VERSION "FL_IC_CANFD"

NS_ :

BS_:

BU_: AVAS BBCM CMSM DVR EAMP EPC FLZCU ICC PCL PLG SBOX SCU

BO_ 1028 PEPS_2: 16 FLZCU
 SG_ PEPS_WelcomeON : 17|2@0+ (1,0) [0|3] ""  ICC
 SG_ PEPS_VehicleSearchReq : 19|2@0+ (1,0) [0|3] ""  ICC
 SG_ PEPS_SATOReminder : 21|2@0+ (1,0) [0|3] ""  ICC
 SG_ PEPS_PLGUnlockReq : 23|2@0+ (1,0) [0|3] ""  ICC
 SG_ PEPS_RKETrunkSts : 25|2@0+ (1,0) [0|3] ""  ICC
 SG_ PEPS_SSBInhibitCWCSts : 27|2@0+ (1,0) [0|3] ""  ICC
 SG_ PEPS_WirelessChargingCtrSts : 29|2@0+ (1,0) [0|3] ""  ICC
 SG_ PEPS_EmgyShutdown : 35|2@0+ (1,0) [0|3] ""  ICC
 SG_ PEPS_SSBInputFailure : 37|2@0+ (1,0) [0|3] ""  ICC
 SG_ PEPS_SmartSystemWarning1_1 : 39|2@0+ (1,0) [0|3] ""  ICC
 SG_ PEPS_SmartSystemWarning2_2 : 41|2@0+ (1,0) [0|3] ""  ICC
 SG_ PEPS_SmartSystemWarning3_1 : 43|2@0+ (1,0) [0|3] ""  ICC
 SG_ PEPS_SmartSystemWarning3_2 : 45|2@0+ (1,0) [0|3] ""  ICC
 SG_ PEPS_SmartSystemWarning4_2 : 47|2@0+ (1,0) [0|3] ""  ICC
 SG_ PEPS_SmartSystemWarning4_3 : 49|2@0+ (1,0) [0|3] ""  ICC
 SG_ PEPS_SystemWarning : 51|2@0+ (1,0) [0|3] ""  ICC
 SG_ PEPS_BLTKeyPESts : 53|2@0+ (1,0) [0|3] ""  ICC

BO_ 1030 FLZCU_12: 16 FLZCU
 SG_ RearViewFoldSts : 58|2@0+ (1,0) [0|3] ""  ICC
 SG_ FLZCU_AlrmSts : 61|3@0+ (1,0) [0|7] ""  ICC
 SG_ FLZCU_SteeringMode : 82|2@0+ (1,0) [0|3] ""  ICC
 SG_ FLZCU_OBDDiagOccupy : 105|2@0+ (1,0) [0|3] ""  ICC

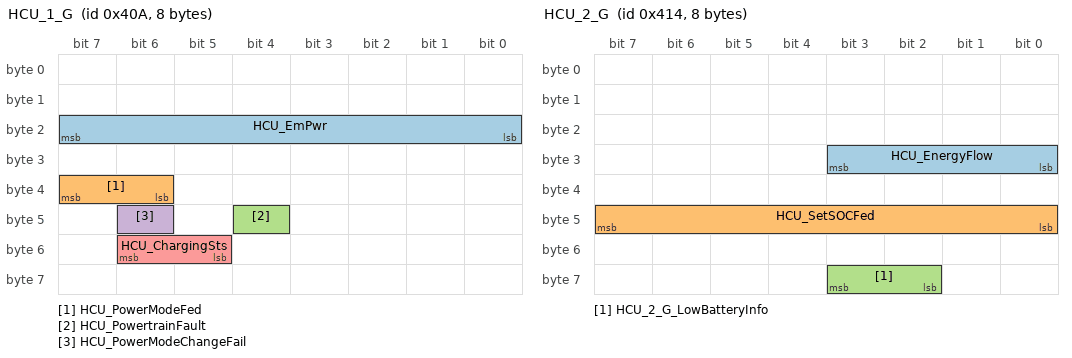
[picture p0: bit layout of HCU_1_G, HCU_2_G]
BO_ 1034 HCU_1_G: 8 FLZCU
 SG_ HCU_EmPwr : 23|8@0+ (1,-128) [-100|100] "%"  ICC
 SG_ HCU_PowerModeFed : 39|2@0+ (1,0) [0|3] ""  ICC
 SG_ HCU_PowertrainFault : 44|1@0+ (1,0) [0|1] ""  ICC
 SG_ HCU_PowerModeChangeFail : 46|1@0+ (1,0) [0|1] ""  ICC
 SG_ HCU_ChargingSts : 54|2@0+ (1,0) [0|3] ""  ICC

BO_ 1035 VCC_1: 8 FLZCU
 SG_ VCC_1_OTASts : 17|2@0+ (1,0) [0|3] ""  ICC
 SG_ VCC_1_DriveMode : 36|5@0+ (1,0) [0|31] ""  ICC

BO_ 1037 ADAS_ZCU_1: 24 FLZCU
 SG_ ADS_FCTAWarn_Right : 26|1@0+ (1,0) [0|1] ""  ICC
 SG_ ADS_FCTAWarn_Left : 27|1@0+ (1,0) [0|1] ""  ICC
 SG_ ADS_RCTAWarn_Rigth : 28|1@0+ (1,0) [0|1] ""  ICC
 SG_ ADS_RCTAWarn_Left : 29|1@0+ (1,0) [0|1] ""  ICC
 SG_ ADAS_enum_AESSts_40Dh : 33|2@0+ (1,0) [0|3] ""  ICC
 SG_ ADAS_enum_AudibleBeepRate_40Dh : 44|3@0+ (1,0) [0|7] ""  ICC
 SG_ ADAS_enum_FCTASettingStsFb_40Dh : 55|3@0+ (1,0) [0|7] ""  ICC
 SG_ ADAS_enum_RadarWorkSts_40Dh : 80|1@0+ (1,0) [0|1] ""  ICC
 SG_ ADAS_enum_PasSwitch_40Dh : 81|1@0+ (1,0) [0|1] ""  ICC
 SG_ ADAS_enum_MEBSts_40Dh : 83|2@0+ (1,0) [0|3] ""  ICC
 SG_ ADAS_enum_MAASts_40Dh : 85|2@0+ (1,0) [0|3] ""  ICC
 SG_ IHU_11_VoiceplayModeSwtSet_40Dh : 113|2@0+ (1,0) [0|3] ""  ICC
 SG_ IHU_11_LightingBlueSwtSet_40Dh : 115|2@0+ (1,0) [0|3] ""  ICC
 SG_ enum_CECULVDSOutputStatus_40Dh : 160|1@0+ (1,0) [0|1] ""  ICC

BO_ 1041 ADS_HW_411h: 48 FLZCU
 SG_ ADS_RadarWarning0Distance_411h : 23|8@0+ (1,0) [0|255] "cm"  ICC
 SG_ ADS_RadarWarning1Distance_411h : 31|8@0+ (1,0) [0|255] "cm"  ICC
 SG_ ADS_RadarWarning2Distance_411h : 39|8@0+ (1,0) [0|255] "cm"  ICC
 SG_ ADS_RadarWarning3Distance_411h : 47|8@0+ (1,0) [0|255] "cm"  ICC
 SG_ ADS_RadarWarning4Distance_411h : 55|8@0+ (1,0) [0|255] "cm"  ICC
 SG_ ADS_RadarWarning5Distance_411h : 63|8@0+ (1,0) [0|255] "cm"  ICC
 SG_ ADS_RadarWarning6Distance_411h : 87|8@0+ (1,0) [0|255] "cm"  ICC
 SG_ ADS_RadarWarning7Distance_411h : 95|8@0+ (1,0) [0|255] "cm"  ICC
 SG_ ADS_RadarWarning8Distance_411h : 103|8@0+ (1,0) [0|255] "cm"  ICC
 SG_ ADS_RadarWarning9Distance_411h : 111|8@0+ (1,0) [0|255] "cm"  ICC
 SG_ ADS_RadarWarning10Distance_411h : 119|8@0+ (1,0) [0|255] "cm"  ICC
 SG_ ADS_RadarWarning11Distance_411h : 127|8@0+ (1,0) [0|255] "cm"  ICC
 SG_ ADS_RadarWarning12Distance_411h : 151|8@0+ (1,0) [0|255] "cm"  ICC
 SG_ ADS_RadarWarning13Distance_411h : 159|8@0+ (1,0) [0|255] "cm"  ICC
 SG_ ADS_RadarWarning14Distance_411h : 167|8@0+ (1,0) [0|255] "cm"  ICC
 SG_ ADS_RadarWarning15Distance_411h : 175|8@0+ (1,0) [0|255] "cm"  ICC
 SG_ ADS_RadarWarning2AcLvl_411h : 177|3@0+ (1,0) [0|7] ""  ICC
 SG_ ADS_RadarWarning1AcLvl_411h : 180|3@0+ (1,0) [0|7] ""  ICC
 SG_ ADS_RadarWarning0AcLvl_411h : 183|3@0+ (1,0) [0|7] ""  ICC
 SG_ ADS_RadarWarning4AcLvl_411h : 187|3@0+ (1,0) [0|7] ""  ICC
 SG_ ADS_RadarWarning3AcLvl_411h : 190|3@0+ (1,0) [0|7] ""  ICC
 SG_ ADS_RadarWarning7AcLvl_411h : 209|3@0+ (1,0) [0|7] ""  ICC
 SG_ ADS_RadarWarning6AcLvl_411h : 212|3@0+ (1,0) [0|7] ""  ICC
 SG_ ADS_RadarWarning5AcLvl_411h : 215|3@0+ (1,0) [0|7] ""  ICC
 SG_ ADS_RadarWarning10AcLvl_411h : 216|3@0+ (1,0) [0|7] ""  ICC
 SG_ ADS_RadarWarning9AcLvl_411h : 219|3@0+ (1,0) [0|7] ""  ICC
 SG_ ADS_RadarWarning8AcLvl_411h : 222|3@0+ (1,0) [0|7] ""  ICC
 SG_ ADS_RadarWarning12AcLvl_411h : 226|3@0+ (1,0) [0|7] ""  ICC
 SG_ ADS_RadarWarning11AcLvl_411h : 229|3@0+ (1,0) [0|7] ""  ICC
 SG_ ADS_RadarWarning15AcLvl_411h : 233|3@0+ (1,0) [0|7] ""  ICC
 SG_ ADS_RadarWarning14AcLvl_411h : 236|3@0+ (1,0) [0|7] ""  ICC
 SG_ ADS_RadarWarning13AcLvl_411h : 239|3@0+ (1,0) [0|7] ""  ICC
 SG_ ADC_MdcSentryAlarmMod_411h : 244|1@0+ (1,0) [0|1] ""  ICC
 SG_ ADC_FuncReq_SentryModDetec_411h : 245|1@0+ (1,0) [0|1] ""  ICC
 SG_ ADC_FuncReq_SentryModWarn_411h : 246|1@0+ (1,0) [0|1] ""  ICC

BO_ 1042 ADS_HW_412h: 16 FLZCU
 SG_ ADS_CRC1_412h : 7|8@0+ (1,0) [0|255] ""  ICC
 SG_ ADS_RollgCntr1_412h : 11|4@0+ (1,0) [0|14] ""  ICC
 SG_ ADS_Resd1_412h : 15|4@0+ (1,0) [0|15] ""  ICC
 SG_ ADS_RiFrntDowWarning_412h : 17|2@0+ (1,0) [0|3] ""  ICC
 SG_ ADS_LeFrntDowWarning_412h : 19|2@0+ (1,0) [0|3] ""  ICC
 SG_ ADS_AutoLightSwCtrl_412h : 21|2@0+ (1,0) [0|3] ""  ICC
 SG_ ADS_BrkBeamReq_412h : 23|2@0+ (1,0) [0|3] ""  ICC
 SG_ ADS_RightMirrWarningCmd_412h : 25|2@0+ (1,0) [0|3] ""  ICC
 SG_ ADS_LeftMirrWarningCmd_412h : 27|2@0+ (1,0) [0|3] ""  ICC
 SG_ ADS_RiReDowWarning_412h : 29|2@0+ (1,0) [0|3] ""  ICC
 SG_ ADS_LeReDowWarning_412h : 31|2@0+ (1,0) [0|3] ""  ICC
 SG_ ADS_WshrReq_412h : 32|1@0+ (1,0) [0|1] ""  ICC
 SG_ ADS_SBeltControl_412h : 35|3@0+ (1,0) [0|7] ""  ICC
 SG_ ADS_DoorLockReq_412h : 37|2@0+ (1,0) [0|3] ""  ICC
 SG_ ADS_ReMirrReq_412h : 39|2@0+ (1,0) [0|3] ""  ICC
 SG_ ADS_LeFmtWinCtrl_412h : 41|2@0+ (1,0) [0|3] ""  ICC
 SG_ ADS_HornReq_412h : 43|2@0+ (1,0) [0|3] ""  ICC
 SG_ ADS_FrtWindshildHeatReq_412h : 45|2@0+ (1,0) [0|3] ""  ICC
 SG_ ADS_SeatShakeControl_412h : 47|2@0+ (1,0) [0|3] ""  ICC
 SG_ ADS_TopWinCtrl_412h : 49|2@0+ (1,0) [0|3] ""  ICC
 SG_ ADS_RiReWinCtrl_412h : 51|2@0+ (1,0) [0|3] ""  ICC
 SG_ ADS_LeReWinCtrl_412h : 53|2@0+ (1,0) [0|3] ""  ICC
 SG_ ADS_RiFmtWinCtrl_412h : 55|2@0+ (1,0) [0|3] ""  ICC
 SG_ ADS_MdcCrtSts_412h : 59|3@0+ (1,0) [0|7] ""  ICC
 SG_ ADAS_FctSts_412h : 60|1@0+ (1,0) [0|1] ""  ICC
 SG_ ADS_ChargingPortCmd_412h : 62|2@0+ (1,0) [0|3] ""  ICC
 SG_ ADS_FrontWiperReq_412h : 63|1@0+ (1,0) [0|1] ""  ICC
 SG_ ADS_PwrOnOffReq_412h : 81|3@0+ (1,0) [0|7] ""  ICC
 SG_ ADS_FlowReq_412h : 85|4@0+ (1,0) [0|15] ""  ICC
 SG_ ADS_ThmPostRun_412h : 86|1@0+ (1,0) [0|1] ""  ICC
 SG_ ADS_HVCtrlReq_412h : 87|1@0+ (1,0) [0|1] ""  ICC
 SG_ ADS_HiBeamReq_412h : 90|1@0+ (1,0) [0|1] ""  ICC
 SG_ ADS_HMAStatus_412h : 92|2@0+ (1,0) [0|3] ""  ICC
 SG_ ADS_hmaOnOffSts_412h : 94|2@0+ (1,0) [0|3] ""  ICC

BO_ 1043 FLZCU_8: 8 FLZCU
 SG_ EBS_U_BATT : 7|14@0+ (0.0009765625,3) [3|18] "V"  ICC

BO_ 1044 HCU_2_G: 8 FLZCU
 SG_ HCU_EnergyFlow : 27|4@0+ (1,0) [0|15] ""  ICC
 SG_ HCU_SetSOCFed : 47|8@0+ (1,0) [0|100] ""  ICC
 SG_ HCU_2_G_LowBatteryInfo : 59|2@0+ (1,0) [0|3] ""  ICC

BO_ 1046 LBMS_SysSt4: 32 FLZCU
 SG_ LBMS_LoWSocFlt : 87|4@0+ (1,0) [0|15] ""  ICC
 SG_ LBMS_EndLifeFlt : 152|1@0+ (1,0) [0|1] ""  ICC
 SG_ LBMS_SysFlt : 157|1@0+ (1,0) [0|1] ""  ICC
 SG_ LBMS_ThermRunawayFlt : 158|1@0+ (1,0) [0|1] ""  ICC
 SG_ LBMS_LowPowerRemind : 167|4@0+ (1,0) [0|15] ""  ICC

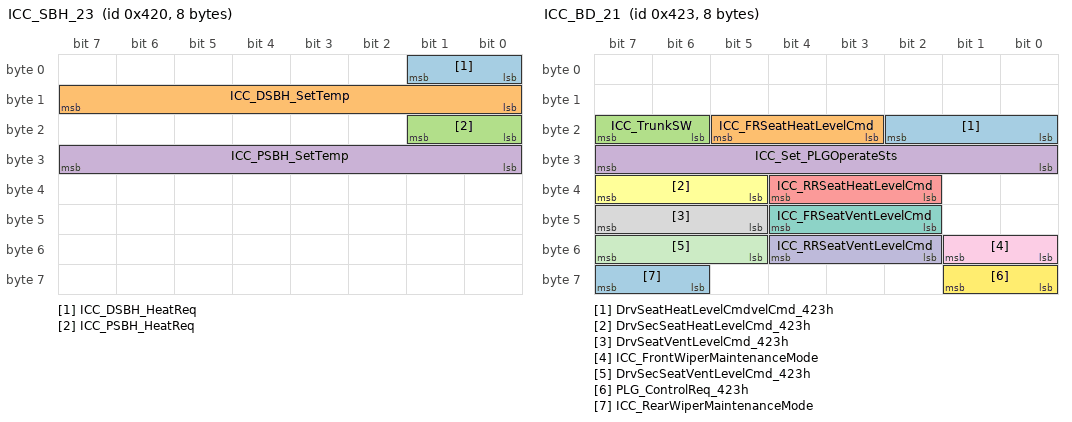
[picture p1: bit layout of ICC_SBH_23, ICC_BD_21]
BO_ 1056 ICC_SBH_23: 8 ICC
 SG_ ICC_DSBH_HeatReq : 1|2@0+ (1,0) [0|3] "" Vector__XXX
 SG_ ICC_DSBH_SetTemp : 15|8@0+ (1,0) [30|65] "°C" Vector__XXX
 SG_ ICC_PSBH_HeatReq : 17|2@0+ (1,0) [0|3] "" Vector__XXX
 SG_ ICC_PSBH_SetTemp : 31|8@0+ (1,0) [30|65] "°C" Vector__XXX

BO_ 1057 VCU_7_G: 32 FLZCU
 SG_ VCU_shfChk : 16|1@0+ (1,0) [0|1] ""  ICC
 SG_ VCU_TowingMode : 33|2@0+ (1,0) [0|3] ""  ICC
 SG_ VCU_ChgSocSetFed : 63|8@0+ (1,0) [50|100] "%"  ICC
 SG_ VCU_EngyConsuPer50Km : 111|12@0+ (0.1,-100) [-100|100] ""  ICC
 SG_ VCU_BookChrgSetFailRes : 154|3@0+ (1,0) [0|7] ""  ICC
 SG_ VCU_BookChrgFailRes : 158|4@0+ (1,0) [0|15] ""  ICC
 SG_ VCU_BookChrgStsFb : 215|2@0+ (1,0) [0|3] ""  ICC
 SG_ HCU_EngineSelfMaintain : 231|2@0+ (1,0) [0|3] ""  ICC

BO_ 1059 ICC_BD_21: 8 ICC
 SG_ DrvSeatHeatLevelCmdvelCmd_423h : 18|3@0+ (1,0) [0|7] ""  FLZCU
 SG_ ICC_FRSeatHeatLevelCmd : 21|3@0+ (1,0) [0|7] ""  FLZCU
 SG_ ICC_TrunkSW : 23|2@0+ (1,0) [0|3] ""  FLZCU
 SG_ ICC_Set_PLGOperateSts : 31|8@0+ (1,-1) [-1|100] "%"  FLZCU,PLG
 SG_ ICC_RRSeatHeatLevelCmd : 36|3@0+ (1,0) [0|7] ""  FLZCU
 SG_ DrvSecSeatHeatLevelCmd_423h : 39|3@0+ (1,0) [0|7] ""  FLZCU
 SG_ ICC_FRSeatVentLevelCmd : 44|3@0+ (1,0) [0|7] ""  FLZCU
 SG_ DrvSeatVentLevelCmd_423h : 47|3@0+ (1,0) [0|7] ""  FLZCU
 SG_ ICC_FrontWiperMaintenanceMode : 49|2@0+ (1,0) [0|3] ""  FLZCU
 SG_ ICC_RRSeatVentLevelCmd : 52|3@0+ (1,0) [0|7] ""  FLZCU
 SG_ DrvSecSeatVentLevelCmd_423h : 55|3@0+ (1,0) [0|7] ""  FLZCU
 SG_ PLG_ControlReq_423h : 57|2@0+ (1,0) [0|3] ""  FLZCU,PLG
 SG_ ICC_RearWiperMaintenanceMode : 63|2@0+ (1,0) [0|3] ""  FLZCU

BO_ 1060 TCU_424h: 64 FLZCU
 SG_ InforDisplay_424h : 38|4@0+ (1,0) [0|15] ""  ICC

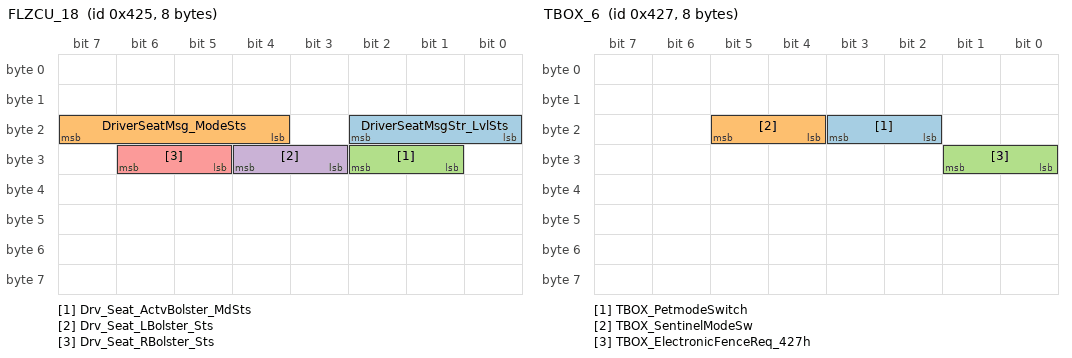
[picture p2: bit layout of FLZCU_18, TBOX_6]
BO_ 1061 FLZCU_18: 8 FLZCU
 SG_ DriverSeatMsgStr_LvlSts : 18|3@0+ (1,0) [0|7] ""  ICC
 SG_ DriverSeatMsg_ModeSts : 23|4@0+ (1,0) [0|15] ""  ICC
 SG_ Drv_Seat_ActvBolster_MdSts : 26|2@0+ (1,0) [0|3] ""  ICC
 SG_ Drv_Seat_LBolster_Sts : 28|2@0+ (1,0) [0|3] ""  ICC
 SG_ Drv_Seat_RBolster_Sts : 30|2@0+ (1,0) [0|3] ""  ICC

BO_ 1063 TBOX_6: 8 FLZCU
 SG_ TBOX_PetmodeSwitch : 19|2@0+ (1,0) [0|3] ""  ICC
 SG_ TBOX_SentinelModeSw : 21|2@0+ (1,0) [0|3] ""  ICC
 SG_ TBOX_ElectronicFenceReq_427h : 25|2@0+ (1,0) [0|3] ""  ICC

BO_ 1065 FLZCU_19: 8 FLZCU
 SG_ LeftSeatMsgStr_LvlSts : 18|3@0+ (1,0) [0|7] ""  ICC
 SG_ LeftSeatMsg_ModeSts : 23|4@0+ (1,0) [0|15] ""  ICC

BO_ 1069 FLZCU_20: 8 FLZCU
 SG_ PassSeatMsgStr_LvlSts : 18|3@0+ (1,0) [0|7] ""  ICC
 SG_ PassSeatMsg_ModeSts : 23|4@0+ (1,0) [0|15] ""  ICC

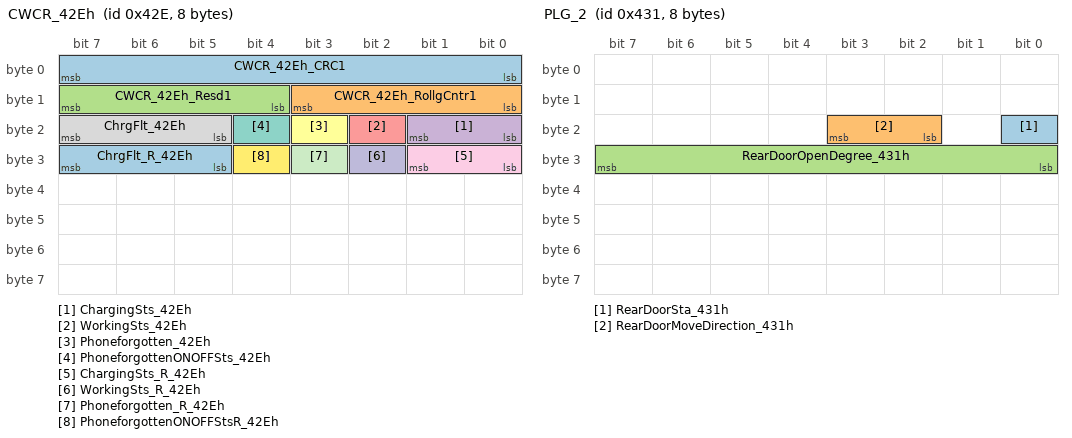
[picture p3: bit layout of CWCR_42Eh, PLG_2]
BO_ 1070 CWCR_42Eh: 8 FLZCU
 SG_ CWCR_42Eh_CRC1 : 7|8@0+ (1,0) [0|255] ""  ICC
 SG_ CWCR_42Eh_RollgCntr1 : 11|4@0+ (1,0) [0|14] ""  ICC
 SG_ CWCR_42Eh_Resd1 : 15|4@0+ (1,0) [0|15] ""  ICC
 SG_ ChargingSts_42Eh : 17|2@0+ (1,0) [0|3] ""  ICC
 SG_ WorkingSts_42Eh : 18|1@0+ (1,0) [0|1] ""  ICC
 SG_ Phoneforgotten_42Eh : 19|1@0+ (1,0) [0|1] ""  ICC
 SG_ PhoneforgottenONOFFSts_42Eh : 20|1@0+ (1,0) [0|1] ""  ICC
 SG_ ChrgFlt_42Eh : 23|3@0+ (1,0) [0|7] ""  ICC
 SG_ ChargingSts_R_42Eh : 25|2@0+ (1,0) [0|3] ""  ICC
 SG_ WorkingSts_R_42Eh : 26|1@0+ (1,0) [0|1] ""  ICC
 SG_ Phoneforgotten_R_42Eh : 27|1@0+ (1,0) [0|1] ""  ICC
 SG_ PhoneforgottenONOFFStsR_42Eh : 28|1@0+ (1,0) [0|1] ""  ICC
 SG_ ChrgFlt_R_42Eh : 31|3@0+ (1,0) [0|7] ""  ICC

BO_ 1071 FLZCU_15: 48 FLZCU
 SG_ FLZCU_CarSearhSetSW : 17|2@0+ (1,0) [0|3] ""  ICC
 SG_ FLZCU_AutoFoldSts : 18|1@0+ (1,0) [0|1] ""  ICC
 SG_ FLZCU_AutolockSts : 19|1@0+ (1,0) [0|1] ""  ICC
 SG_ FLZCU_FGHeat_Req_CmdFeedback : 20|1@0+ (1,0) [0|1] ""  ICC
 SG_ FLZCU_WindowInhibitSts : 21|1@0+ (1,0) [0|1] ""  ICC
 SG_ FLZCU_AutoReadLightSts : 22|1@0+ (1,0) [0|1] ""  ICC
 SG_ FLZCU_HeatingSW : 23|1@0+ (1,0) [0|1] ""  ICC
 SG_ FLZCU_AutoHeatingFb : 24|1@0+ (1,0) [0|1] ""  ICC
 SG_ FLZCU_SteerNeedMemory : 25|1@0+ (1,0) [0|1] ""  ICC
 SG_ FLZCU_LowBeamFaults : 26|1@0+ (1,0) [0|1] ""  ICC
 SG_ FLZCU_RearNeedMemory : 27|1@0+ (1,0) [0|1] ""  ICC
 SG_ FLZCU_BrkLightFaults : 28|1@0+ (1,0) [0|1] ""  ICC
 SG_ FLZCU_TurnLiSwtSts : 31|3@0+ (1,0) [0|7] ""  ICC
 SG_ DrvHandleFoldedSts_42Fh : 33|2@0+ (1,0) [0|3] ""  ICC
 SG_ DrvRearHandleFoldedSts_42Fh : 35|2@0+ (1,0) [0|3] ""  ICC
 SG_ PassHandleFoldedSts_42Fh : 37|2@0+ (1,0) [0|3] ""  ICC
 SG_ PassRearHandleFoldedSts_42Fh : 39|2@0+ (1,0) [0|3] ""  ICC
 SG_ FLZCU_RvsExtMirrFbSts : 41|2@0+ (1,0) [0|3] ""  ICC
 SG_ FLZCU_LightMainSwitchSts : 44|3@0+ (1,0) [0|7] ""  ICC
 SG_ FLZCU_BeamDelaySts : 47|3@0+ (1,0) [0|7] ""  ICC
 SG_ FLZCU_LowBeamHighSts : 50|3@0+ (1,0) [0|7] ""  ICC
 SG_ FLZCU_WipeSensitivitySts : 53|3@0+ (1,0) [0|7] ""  ICC
 SG_ FLZCU_WipeMaintenanceSWSts : 55|2@0+ (1,0) [0|3] ""  ICC
 SG_ FLZCU_HiBeamSwtSts : 57|2@0+ (1,0) [0|3] ""  ICC
 SG_ FLZCU_ImmoRequest : 60|3@0+ (1,0) [0|7] ""  ICC
 SG_ FLZCU_AlarmWarnSetSW : 63|3@0+ (1,0) [0|7] ""  ICC
 SG_ FLZCU_CleanModeStatus : 81|2@0+ (1,0) [0|3] ""  ICC
 SG_ DrvReleaseLockSts_42Fh : 84|3@0+ (1,0) [0|7] ""  ICC
 SG_ FLZCU_RearFogLightSts : 85|1@0+ (1,0) [0|1] ""  ICC
 SG_ PassFoglightSts_42Fh : 86|1@0+ (1,0) [0|1] ""  ICC
 SG_ DrvFoglightSts_42Fh : 87|1@0+ (1,0) [0|1] ""  ICC
 SG_ FLZCU_RearFogLightFaults : 88|1@0+ (1,0) [0|1] ""  ICC
 SG_ FLZCU_HighBeamFaults : 89|1@0+ (1,0) [0|1] ""  ICC
 SG_ FLZCU_HighBeamSts : 90|1@0+ (1,0) [0|1] ""  ICC
 SG_ FLZCU_LowBeamSts : 91|1@0+ (1,0) [0|1] ""  ICC
 SG_ FLZCU_ParkUnlockEnableFb : 92|1@0+ (1,0) [0|1] ""  ICC
 SG_ DrvRearReleaseLockSts_42Fh : 95|3@0+ (1,0) [0|7] ""  ICC
 SG_ FLZCU_EasyEntryExitFb : 97|2@0+ (1,0) [0|3] ""  ICC
 SG_ FLZCU_EmgyLiSwtSts : 98|1@0+ (1,0) [0|1] ""  ICC
 SG_ FLZCU_HMASwSts : 99|1@0+ (1,0) [0|1] ""  ICC
 SG_ FLZCU_DaytimeLight : 101|2@0+ (1,0) [0|3] ""  ICC
 SG_ FLZCU_FGHeatFaults : 102|1@0+ (1,0) [0|1] ""  ICC
 SG_ FLZCU_ParkLightFaults : 103|1@0+ (1,0) [0|1] ""  ICC
 SG_ FLZCU_LbatipVehPwrMod : 106|1@0+ (1,0) [0|1] ""  ICC
 SG_ FLZCU_HMASwSts_MDC : 108|2@0+ (1,0) [0|3] ""  ICC
 SG_ FLZCU_LVPowICDsp : 111|3@0+ (1,0) [0|7] ""  ICC
 SG_ FLZCU_LockCarWinCloseFb : 113|2@0+ (1,0) [0|3] ""  ICC
 SG_ FLZCU_BrkLightSts : 115|2@0+ (1,0) [0|3] ""  ICC
 SG_ FLZCU_ReverseLightSts : 117|2@0+ (1,0) [0|3] ""  ICC
 SG_ FLZCU_LowWashLqdWarning : 119|2@0+ (1,0) [0|3] ""  ICC
 SG_ FLZCU_SteerWheelHeatingFb : 123|3@0+ (1,0) [0|7] ""  ICC
 SG_ FLZCU_FrontFogLightSts : 124|1@0+ (1,0) [0|1] ""  ICC
 SG_ FLZCU_NapAreaFb : 145|2@0+ (1,0) [0|3] ""  ICC
 SG_ FLZCU_NapTimeFb : 151|6@0+ (1,0) [0|60] "min"  ICC
 SG_ FLZCU_NapAlarmStatus : 153|2@0+ (1,0) [0|3] ""  ICC
 SG_ FLZCU_NapFailCause : 157|4@0+ (1,0) [0|15] ""  ICC
 SG_ FLZCU_NapStatusFb : 159|2@0+ (1,0) [0|3] ""  ICC
 SG_ FLZCU_CleanModeFailCause : 163|2@0+ (1,0) [0|3] ""  ICC
 SG_ LockCarSunRoofShadeCloseFb : 165|2@0+ (1,0) [0|3] ""  ICC
 SG_ FLZCU_NapClosePrompt : 167|2@0+ (1,0) [0|3] ""  ICC
 SG_ FLZCU_AutoWipingInhibit : 175|2@0+ (1,0) [0|3] ""  ICC
 SG_ FLZCU_RemoteUnlockFb : 177|2@0+ (1,0) [0|3] ""  ICC
 SG_ FLZCU_FrntWiprSwSts : 181|4@0+ (1,0) [0|15] ""  ICC
 SG_ TurnLightFaults_42Fh : 208|1@0+ (1,0) [0|1] ""  ICC
 SG_ FLZCU_HazardLightSWSts_42Fh : 232|1@0+ (1,0) [0|1] ""  ICC
 SG_ DrvRearWinSts_42Fh : 252|3@0+ (1,0) [0|7] ""  ICC
 SG_ DrvWinSts_42Fh : 255|3@0+ (1,0) [0|7] ""  ICC
 SG_ FLZCU_DaytimeLightFaults : 273|2@0+ (1,0) [0|3] ""  ICC
 SG_ FLZCU_FrontFogLightFaults : 275|2@0+ (1,0) [0|3] ""  ICC
 SG_ FLZCU_HomeLinkWelLightSetSts : 277|2@0+ (1,0) [0|3] ""  ICC
 SG_ FLZCU_HomeLinkArmHornSetSts : 279|2@0+ (1,0) [0|3] ""  ICC
 SG_ FLZCU_UIROpenStas : 283|2@0+ (1,0) [0|3] ""  ICC
 SG_ FLZCU_WALOpenStas : 285|2@0+ (1,0) [0|3] ""  ICC
 SG_ FLZCU_WelcomeOpenStas : 287|2@0+ (1,0) [0|3] ""  ICC
 SG_ FLZCU_RearWiprSwSts_42Fh : 291|2@0+ (1,0) [0|3] ""  ICC
 SG_ FLZCU_ExtLiSwtClsSts : 359|2@0+ (1,0) [0|3] ""  ICC

BO_ 1072 FLZCU_31: 16 FLZCU
 SG_ AutoSeatHeatLevelsFb_430h : 17|2@0+ (1,0) [0|3] ""  ICC
 SG_ AutoSteerWhlHeatFb_430h : 19|2@0+ (1,0) [0|3] ""  ICC
 SG_ AutoSeatVentLevelsFb_430h : 21|2@0+ (1,0) [0|3] ""  ICC
 SG_ DrvDoorSts_430h : 23|2@0+ (1,0) [0|3] ""  ICC
 SG_ DrvSeatBeltSW_430h : 31|1@0+ (1,0) [0|1] ""  ICC
 SG_ DrvRearWinPosn_430h : 47|7@0+ (1,0) [0|100] "%"  ICC
 SG_ DrvSeatHeatLevels_430h : 49|2@0+ (1,0) [0|3] ""  ICC
 SG_ DrvRearChildProtectSwt_430h : 55|2@0+ (1,0) [0|3] ""  ICC
 SG_ DrvSecSeatHeatLevels_430h : 61|2@0+ (1,0) [0|3] ""  ICC
 SG_ DrvSeatVentLevels_430h : 63|2@0+ (1,0) [0|3] ""  ICC
 SG_ DrvSecSeatVentLevels_430h : 87|2@0+ (1,0) [0|3] ""  ICC
 SG_ DrvWinPosn_430h : 94|7@0+ (1,0) [0|100] "%"  ICC
 SG_ FLZCU_RearWiperMaintenanceSts : 107|2@0+ (1,0) [0|3] ""  ICC
 SG_ FLZCU_FrontWiperMaintenanceSts : 109|2@0+ (1,0) [0|3] ""  ICC

BO_ 1073 PLG_2: 8 PLG
 SG_ RearDoorSta_431h : 16|1@0+ (1,0) [0|1] ""  ICC
 SG_ RearDoorMoveDirection_431h : 19|2@0+ (1,0) [0|3] ""  ICC
 SG_ RearDoorOpenDegree_431h : 31|8@0+ (1,0) [0|100] "%"  ICC

BO_ 1075 VCC_2: 8 FLZCU
 SG_ VCC_2_ConfigurationMessageTrg : 23|1@0+ (1,0) [0|1] ""  ICC

BO_ 1078 PLG_1: 8 BBCM
 SG_ PLG_LatchSts : 33|2@0+ (1,0) [0|3] ""  ICC
 SG_ PLG_Set_PLGOperateStsFb : 63|8@0+ (1,0) [0|100] "%"  ICC

BO_ 1079 BSCU_1: 8 FLZCU
 SG_ BSCU_1_MotorLockSts : 17|2@0+ (1,0) [0|3] ""  ICC

BO_ 1087 FLZCU_21: 8 FLZCU
 SG_ RightSeatMsgStr_LvlSts : 18|3@0+ (1,0) [0|7] ""  ICC
 SG_ RightSeatMsg_ModeSts : 23|4@0+ (1,0) [0|15] ""  ICC

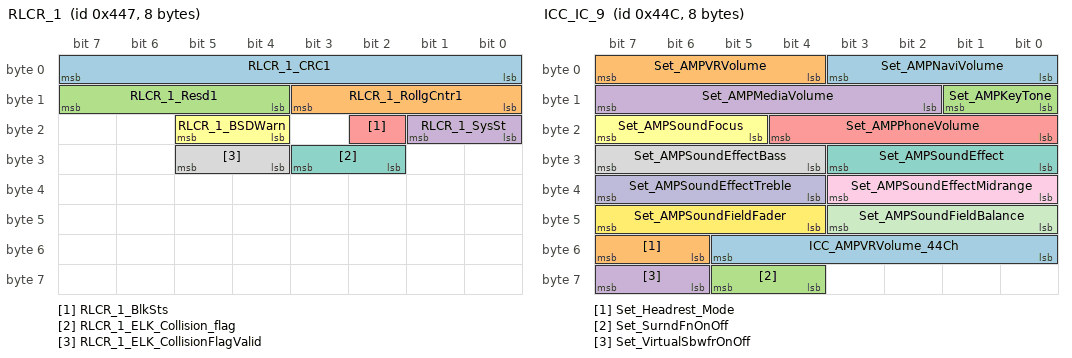
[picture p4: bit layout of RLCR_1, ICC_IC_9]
BO_ 1095 RLCR_1: 8 FLZCU
 SG_ RLCR_1_CRC1 : 7|8@0+ (1,0) [0|255] ""  ICC
 SG_ RLCR_1_RollgCntr1 : 11|4@0+ (1,0) [0|14] ""  ICC
 SG_ RLCR_1_Resd1 : 15|4@0+ (1,0) [0|15] ""  ICC
 SG_ RLCR_1_SysSt : 17|2@0+ (1,0) [0|3] ""  ICC
 SG_ RLCR_1_BlkSts : 18|1@0+ (1,0) [0|1] ""  ICC
 SG_ RLCR_1_BSDWarn : 21|2@0+ (1,0) [0|3] ""  ICC
 SG_ RLCR_1_ELK_Collision_flag : 27|2@0+ (1,0) [0|3] ""  ICC
 SG_ RLCR_1_ELK_CollisionFlagValid : 29|2@0+ (1,0) [0|3] ""  ICC

BO_ 1096 TMS_11: 32 FLZCU
 SG_ TMS_AirPurgeReminderSts : 17|2@0+ (1,0) [0|3] ""  ICC
 SG_ TMS_CirculationInTunnelsSts : 19|2@0+ (1,0) [0|3] ""  ICC
 SG_ TMS_First_BlowingSts : 21|2@0+ (1,0) [0|3] ""  ICC
 SG_ TMS_BT_Reduce_Wind_SpeedSts : 23|2@0+ (1,0) [0|3] ""  ICC
 SG_ TMS_CoolantFillSts : 25|2@0+ (1,0) [0|3] ""  ICC
 SG_ TMS_ParkingAirConditioningStatus : 27|2@0+ (1,0) [0|3] ""  ICC
 SG_ TMS_crosscountry_coolingSts : 29|2@0+ (1,0) [0|3] ""  ICC
 SG_ TMS_ICC_Lightoff_Sts : 33|2@0+ (1,0) [0|3] ""  ICC
 SG_ TMS_UVC_LuminanceSts : 36|3@0+ (1,0) [0|7] ""  ICC
 SG_ TMS_AutoDefogActiveSts : 37|1@0+ (1,0) [0|1] ""  ICC
 SG_ TMS_UVC_ControlSts : 39|2@0+ (1,0) [0|3] ""  ICC
 SG_ TMS_ICC_Memoff_Sts : 47|2@0+ (1,0) [0|3] ""  ICC
 SG_ TMS_keepwarmSet_TemperatureSts : 55|8@0+ (1,0) [0|255] ""  ICC
 SG_ TMS_BiochemicalFuncSts : 95|2@0+ (1,0) [0|3] ""  ICC
 SG_ TMS_TimedVentilationSts : 97|2@0+ (1,0) [0|3] ""  ICC
 SG_ TMS_LowbattACDisable_448h : 107|2@0+ (1,0) [0|3] ""  ICC
 SG_ TMS_SailEACDisable_448h : 109|2@0+ (1,0) [0|3] ""  ICC
 SG_ TMS_ICAstsFed_448h : 111|2@0+ (1,0) [0|3] ""  ICC

BO_ 1099 ISGF_4: 8 FLZCU
 SG_ ISGF_SysTempOvrInd : 40|1@0+ (1,0) [0|1] ""  ICC

BO_ 1100 ICC_IC_9: 8 ICC
 SG_ Set_AMPNaviVolume : 3|4@0+ (1,0) [0|15] ""  EAMP
 SG_ Set_AMPVRVolume : 7|4@0+ (1,0) [0|15] ""  EAMP
 SG_ Set_AMPKeyTone : 9|2@0+ (1,0) [0|3] ""  EAMP
 SG_ Set_AMPMediaVolume : 15|6@0+ (1,0) [0|63] ""  EAMP
 SG_ Set_AMPPhoneVolume : 20|5@0+ (1,0) [0|31] ""  EAMP
 SG_ Set_AMPSoundFocus : 23|3@0+ (1,0) [0|7] ""  EAMP
 SG_ Set_AMPSoundEffect : 27|4@0+ (1,0) [0|15] ""  EAMP
 SG_ Set_AMPSoundEffectBass : 31|4@0+ (1,0) [0|15] ""  EAMP
 SG_ Set_AMPSoundEffectMidrange : 35|4@0+ (1,0) [0|15] ""  EAMP
 SG_ Set_AMPSoundEffectTreble : 39|4@0+ (1,0) [0|15] ""  EAMP
 SG_ Set_AMPSoundFieldBalance : 43|4@0+ (1,0) [0|15] ""  EAMP
 SG_ Set_AMPSoundFieldFader : 47|4@0+ (1,0) [0|15] ""  EAMP
 SG_ ICC_AMPVRVolume_44Ch : 53|6@0+ (1,0) [0|63] ""  EAMP
 SG_ Set_Headrest_Mode : 55|2@0+ (1,0) [0|3] ""  EAMP
 SG_ Set_SurndFnOnOff : 61|2@0+ (1,0) [0|3] ""  EAMP
 SG_ Set_VirtualSbwfrOnOff : 63|2@0+ (1,0) [0|3] ""  EAMP

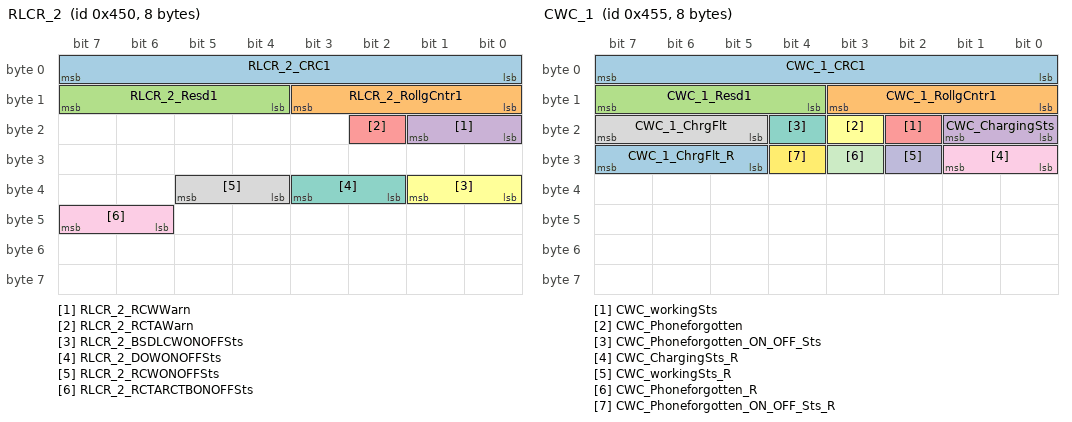
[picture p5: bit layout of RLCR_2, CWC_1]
BO_ 1104 RLCR_2: 8 FLZCU
 SG_ RLCR_2_CRC1 : 7|8@0+ (1,0) [0|255] ""  ICC
 SG_ RLCR_2_RollgCntr1 : 11|4@0+ (1,0) [0|14] ""  ICC
 SG_ RLCR_2_Resd1 : 15|4@0+ (1,0) [0|15] ""  ICC
 SG_ RLCR_2_RCWWarn : 17|2@0+ (1,0) [0|3] ""  ICC
 SG_ RLCR_2_RCTAWarn : 18|1@0+ (1,0) [0|1] ""  ICC
 SG_ RLCR_2_BSDLCWONOFFSts : 33|2@0+ (1,0) [0|3] ""  ICC
 SG_ RLCR_2_DOWONOFFSts : 35|2@0+ (1,0) [0|3] ""  ICC
 SG_ RLCR_2_RCWONOFFSts : 37|2@0+ (1,0) [0|3] ""  ICC
 SG_ RLCR_2_RCTARCTBONOFFSts : 47|2@0+ (1,0) [0|3] ""  ICC

BO_ 1105 ICC_MFS_22: 8 ICC
 SG_ ICC_MultiplexSignalStatusSet : 12|3@0+ (1,0) [0|7] "" Vector__XXX

BO_ 1107 TMS_10: 8 FLZCU
 SG_ TMS_CCP_FLTempSts : 21|6@0+ (0.5,15.5) [15.5|30.5] "℃"  ICC
 SG_ TMS_CCP_FrontAutoACSts : 22|1@0+ (1,0) [0|1] ""  ICC
 SG_ TMS_PM25_Detect : 23|1@0+ (1,0) [0|1] ""  ICC
 SG_ TMS_CCP_FrontDefrostSts : 25|1@0+ (1,0) [0|1] ""  ICC
 SG_ TMS_CCP_FBlowSpdCtrlSts : 29|4@0+ (1,0) [0|15] ""  ICC
 SG_ TMS_CCP_FrontOFFSts : 30|1@0+ (1,0) [0|1] ""  ICC
 SG_ TMS_CCP_ACStatus : 31|1@0+ (1,0) [0|1] ""  ICC
 SG_ TMS_CCP_FRTempSts : 37|6@0+ (0.5,15.5) [15.5|30.5] "℃"  ICC
 SG_ TMS_CCP_RecyMode : 39|2@0+ (1,0) [0|3] ""  ICC
 SG_ TMS_CCP_ACFastHeat : 41|2@0+ (1,0) [0|3] ""  ICC
 SG_ TMS_CCP_ACFastCool : 43|2@0+ (1,0) [0|3] ""  ICC
 SG_ TMS_UVC_LuminanceBfReq : 45|2@0+ (1,0) [0|3] ""  ICC
 SG_ TMS_UVC_WorkingBfReq : 47|2@0+ (1,0) [0|3] ""  ICC
 SG_ TMS_ThrSetTempFb_C_453h : 52|5@0+ (0.5,15.5) [15.5|30.5] "℃"  ICC
 SG_ TMS_ThrModeStsFb_453h : 55|3@0+ (1,0) [0|7] ""  ICC
 SG_ TMS_ThrCLMSwitchFb_453h : 57|2@0+ (1,0) [0|3] ""  ICC
 SG_ TMS_ThrAutoSwitchFb_453h : 59|2@0+ (1,0) [0|3] ""  ICC
 SG_ TMS_ThrACReqKeyStsFb_453h : 61|2@0+ (1,0) [0|3] ""  ICC

BO_ 1109 CWC_1: 8 FLZCU
 SG_ CWC_1_CRC1 : 7|8@0+ (1,0) [0|255] ""  ICC
 SG_ CWC_1_RollgCntr1 : 11|4@0+ (1,0) [0|14] ""  ICC
 SG_ CWC_1_Resd1 : 15|4@0+ (1,0) [0|15] ""  ICC
 SG_ CWC_ChargingSts : 17|2@0+ (1,0) [0|3] ""  ICC
 SG_ CWC_workingSts : 18|1@0+ (1,0) [0|1] ""  ICC
 SG_ CWC_Phoneforgotten : 19|1@0+ (1,0) [0|1] ""  ICC
 SG_ CWC_Phoneforgotten_ON_OFF_Sts : 20|1@0+ (1,0) [0|1] ""  ICC
 SG_ CWC_1_ChrgFlt : 23|3@0+ (1,0) [0|7] ""  ICC
 SG_ CWC_ChargingSts_R : 25|2@0+ (1,0) [0|3] ""  ICC
 SG_ CWC_workingSts_R : 26|1@0+ (1,0) [0|1] ""  ICC
 SG_ CWC_Phoneforgotten_R : 27|1@0+ (1,0) [0|1] ""  ICC
 SG_ CWC_Phoneforgotten_ON_OFF_Sts_R : 28|1@0+ (1,0) [0|1] ""  ICC
 SG_ CWC_1_ChrgFlt_R : 31|3@0+ (1,0) [0|7] ""  ICC

BO_ 1110 IMMO_ICC_11: 8 FLZCU
 SG_ IMMO_Chall_ICC : 7|64@0+ (1,0) [0|1.84467440737096E+019] ""  ICC

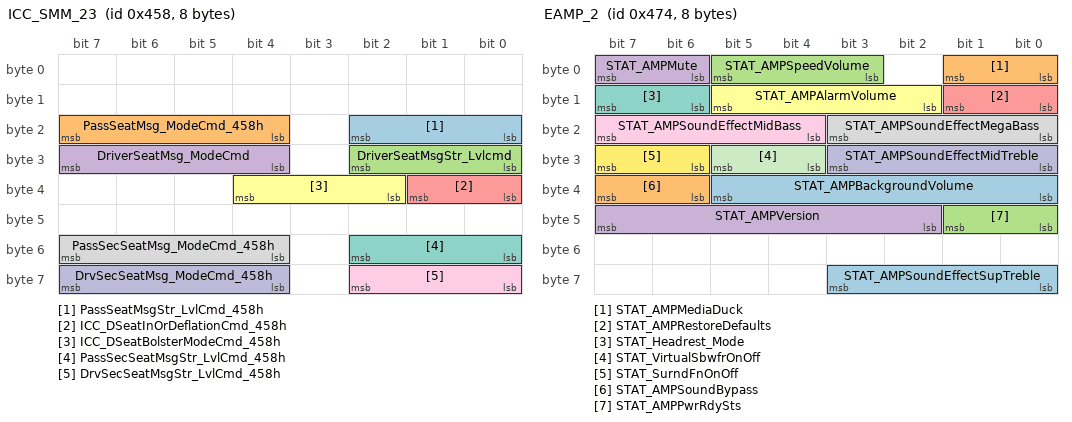
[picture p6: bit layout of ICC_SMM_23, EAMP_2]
BO_ 1112 ICC_SMM_23: 8 ICC
 SG_ PassSeatMsgStr_LvlCmd_458h : 18|3@0+ (1,0) [0|7] ""  FLZCU
 SG_ PassSeatMsg_ModeCmd_458h : 23|4@0+ (1,0) [0|15] ""  FLZCU
 SG_ DriverSeatMsgStr_Lvlcmd : 26|3@0+ (1,0) [0|7] ""  FLZCU
 SG_ DriverSeatMsg_ModeCmd : 31|4@0+ (1,0) [0|15] ""  FLZCU
 SG_ ICC_DSeatInOrDeflationCmd_458h : 33|2@0+ (1,0) [0|3] ""  FLZCU
 SG_ ICC_DSeatBolsterModeCmd_458h : 36|3@0+ (1,0) [0|7] ""  FLZCU
 SG_ PassSecSeatMsgStr_LvlCmd_458h : 50|3@0+ (1,0) [0|7] ""  FLZCU
 SG_ PassSecSeatMsg_ModeCmd_458h : 55|4@0+ (1,0) [0|15] ""  FLZCU
 SG_ DrvSecSeatMsgStr_LvlCmd_458h : 58|3@0+ (1,0) [0|7] ""  FLZCU
 SG_ DrvSecSeatMsg_ModeCmd_458h : 63|4@0+ (1,0) [0|15] ""  FLZCU

BO_ 1116 ICC_IMMO_11: 8 ICC
 SG_ ICC_Auth_IMMO : 7|64@0+ (1,0) [0|1.84467440737096E+019] ""  FLZCU

BO_ 1119 ICC_IC_10: 8 ICC
 SG_ Set_AMPMediaDuck : 1|2@0+ (1,0) [0|3] ""  EAMP
 SG_ Set_AMPSpeedVolume : 5|3@0+ (1,0) [0|7] ""  EAMP
 SG_ Set_AMPMute : 7|2@0+ (1,0) [0|3] ""  EAMP
 SG_ REQ_AMPA2BMediaSound : 9|2@0+ (1,0) [0|3] ""  EAMP
 SG_ REQ_AMPA2BNaviSound : 11|2@0+ (1,0) [0|3] ""  EAMP
 SG_ REQ_AMPA2BVRSound : 13|2@0+ (1,0) [0|3] ""  EAMP
 SG_ REQ_AMPA2BTTSSound : 15|2@0+ (1,0) [0|3] ""  EAMP
 SG_ ICC_AMPPhoneVolume_45Fh : 21|6@0+ (1,0) [0|63] ""  EAMP
 SG_ REQ_AMPA2BKeyTone : 23|2@0+ (1,0) [0|3] ""  EAMP
 SG_ Set_AMPRestoreDefaults : 25|2@0+ (1,0) [0|3] ""  EAMP
 SG_ Set_AMPAlarmVolume : 29|4@0+ (1,0) [0|15] ""  EAMP
 SG_ REQ_AMPA2BPhoneSound : 31|2@0+ (1,0) [0|3] ""  EAMP
 SG_ Set_AMPSoundEffectMegaBass : 35|4@0+ (1,0) [0|15] ""  EAMP
 SG_ Set_AMPSoundEffectMidBass : 39|4@0+ (1,0) [0|15] ""  EAMP
 SG_ Set_AMPSoundEffectMidTreble : 43|4@0+ (1,0) [0|15] ""  EAMP
 SG_ Set_AMPSoundBypass : 45|2@0+ (1,0) [0|3] ""  EAMP
 SG_ Set_AMPA2BConfig : 47|2@0+ (1,0) [0|3] ""  EAMP
 SG_ Set_AMPBackgroundVolume : 53|6@0+ (1,0) [0|63] ""  EAMP
 SG_ ICC_AMPNaviVolume_45Fh : 61|6@0+ (1,0) [0|63] ""  EAMP

BO_ 1120 FLZCU_3: 8 FLZCU
 SG_ RLHS_2_AmbBrightness : 19|12@0+ (20,0) [0|81880] "Lux"  ICC
 SG_ RLHS_LiSwithReason : 49|2@0+ (1,0) [0|3] ""  ICC

BO_ 1121 EAMP_1: 8 EAMP
 SG_ STAT_AMPNaviVolume : 3|4@0+ (1,0) [0|15] ""  ICC
 SG_ STAT_AMPVRVolume : 7|4@0+ (1,0) [0|15] ""  ICC
 SG_ STAT_AMPKeyTone : 9|2@0+ (1,0) [0|3] ""  ICC
 SG_ STAT_AMPMediaVolume : 15|6@0+ (1,0) [0|63] ""  ICC
 SG_ STAT_AMPPhoneVolume : 20|5@0+ (1,0) [0|31] ""  ICC
 SG_ STAT_AMPSoundFocus : 23|3@0+ (1,0) [0|7] ""  ICC
 SG_ STAT_AMPSoundEffect : 27|4@0+ (1,0) [0|15] ""  ICC
 SG_ STAT_AMPSoundEffectBass : 31|4@0+ (1,0) [0|15] ""  ICC
 SG_ STAT_AMPSoundEffectMidrange : 35|4@0+ (1,0) [0|15] ""  ICC
 SG_ STAT_AMPSoundEffectTreble : 39|4@0+ (1,0) [0|15] ""  ICC
 SG_ STAT_AMPSoundFieldBalance : 43|4@0+ (1,0) [0|15] ""  ICC
 SG_ STAT_AMPSoundFieldFader : 47|4@0+ (1,0) [0|15] ""  ICC
 SG_ STAT_REQ_AMPA2BMediaSound : 49|2@0+ (1,0) [0|3] ""  ICC
 SG_ STAT_REQ_AMPA2BNaviSound : 51|2@0+ (1,0) [0|3] ""  ICC
 SG_ STAT_REQ_AMPA2BVRSound : 53|2@0+ (1,0) [0|3] ""  ICC
 SG_ STAT_REQ_AMPA2BTTSSound : 55|2@0+ (1,0) [0|3] ""  ICC
 SG_ STAT_REQ_AMPA2BPhoneSound : 57|2@0+ (1,0) [0|3] ""  ICC
 SG_ STAT_REQ_AMPAlarm : 63|6@0+ (1,0) [0|63] ""  ICC

BO_ 1123 EMS_463h: 16 FLZCU
 SG_ IMMOCodeWarningLightSts_463h : 19|2@0+ (1,0) [0|3] ""  ICC
 SG_ ISS_Switch_Sts_463h : 21|2@0+ (1,0) [0|3] ""  ICC

BO_ 1127 CDU_DCDC_1: 24 FLZCU
 SG_ DCDC_FaultLevelSts : 107|3@0+ (1,0) [0|7] ""  ICC

BO_ 1128 EMS_ICC_468h: 24 FLZCU
 SG_ ISS_Sts_GS_468h : 20|5@0+ (1,0) [0|31] ""  ICC
 SG_ PromptMesg_468h : 31|2@0+ (1,0) [0|3] ""  ICC
 SG_ GPFWarning_468h : 33|2@0+ (1,0) [0|3] ""  ICC
 SG_ FuelRollingCounter_468h : 63|8@0+ (7.88519E-005,0) [0|0.0200283826] "ltr"  ICC
 SG_ MILSts_468h : 97|2@0+ (1,0) [0|3] ""  ICC
 SG_ IEMSts_468h : 99|2@0+ (1,0) [0|3] ""  ICC
 SG_ EPCSts_468h : 105|2@0+ (1,0) [0|3] ""  ICC
 SG_ FuelRollingCounterValidData_468h : 109|2@0+ (1,0) [0|3] ""  ICC
 SG_ CruiseControlStsForDisplay_468h : 111|2@0+ (1,0) [0|3] ""  ICC
 SG_ Crosscountry_coolingSts_468h : 123|2@0+ (1,0) [0|3] ""  ICC

BO_ 1129 EMS_COM_469h: 16 FLZCU
 SG_ EngineCoolantTemp_469h : 23|8@0+ (0.75,-48) [-48|142.5] "℃"  ICC
 SG_ EngineSpeed_469h : 87|11@0+ (4,0) [0|8000] "rpm"  ICC
 SG_ EngineSpeedValidData_469h : 92|2@0+ (1,0) [0|3] ""  ICC

BO_ 1130 TCU_23: 64 FLZCU
 SG_ TCU_23_GBFaultstatus : 23|2@0+ (1,0) [0|3] ""  ICC
 SG_ TCU_23_TeachInState : 30|3@0+ (1,0) [0|7] ""  ICC
 SG_ TCU_23_CluSelfLrng : 39|1@0+ (1,0) [0|1] ""  ICC

BO_ 1131 TCU_46Bh: 16 FLZCU
 SG_ New_Signal_46B_4 : 57|2@0+ (1,0) [0|0] ""  ICC
 SG_ New_Signal_46B_3 : 50|3@0+ (1,0) [0|0] ""  ICC
 SG_ New_Signal_46B_2 : 31|24@0+ (1,0) [0|0] ""  ICC
 SG_ New_Signal_46B_1 : 7|24@0+ (1,0) [0|0] ""  ICC
 SG_ GBPositoionDisplay_46Bh : 55|5@0+ (1,0) [0|31] ""  ICC
 SG_ SpeParkSts_46Bh : 59|2@0+ (1,0) [0|3] ""  ICC
 SG_ GBFaultstatus_46Bh : 61|2@0+ (1,0) [0|3] ""  ICC
 SG_ ClutchTemperature_46Bh : 63|2@0+ (1,0) [0|3] ""  ICC

BO_ 1136 VCC_3: 32 FLZCU
 SG_ VCC_3_CRC : 7|8@0+ (1,0) [0|255] ""  ICC
 SG_ VCC_3_RollgCntr : 11|4@0+ (1,0) [0|14] ""  ICC
 SG_ VCC_3_Resd1 : 15|4@0+ (1,0) [0|15] ""  ICC
 SG_ VCC_3_SN : 23|8@0+ (1,0) [1|32] ""  ICC

BO_ 1137 ICC_TBOX_27: 32 ICC
 SG_ ICC_BookChrgSetReq : 23|2@0+ (1,0) [0|3] ""  FLZCU
 SG_ ICC_BkChrgStartTimeYear : 31|16@0+ (1,1900) [1900|9999] "年"  FLZCU
 SG_ ICC_BkChrgStartTimeDay : 47|5@0+ (1,0) [1|31] "日"  FLZCU
 SG_ ICC_BkChrgStartTimeHour : 55|5@0+ (1,0) [0|23] "小时"  FLZCU
 SG_ ICC_BkChrgStartTimemMin : 63|6@0+ (1,0) [0|59] "分钟"  FLZCU
 SG_ ICC_BkChrgDuration : 83|11@0+ (1,0) [0|1440] "min"  FLZCU
 SG_ ICC_BkChrgStartTimeMonth : 87|4@0+ (1,0) [1|12] "月"  FLZCU
 SG_ ICC_BkChrgCycleMon : 98|2@0+ (1,0) [0|3] ""  FLZCU
 SG_ ICC_StopChrgReq : 100|2@0+ (1,0) [0|3] ""  FLZCU
 SG_ ICC_BkChrgCycleType : 103|3@0+ (1,0) [0|7] ""  FLZCU
 SG_ ICC_BkChrgCycleFri : 105|2@0+ (1,0) [0|3] ""  FLZCU
 SG_ ICC_BkChrgCycleThur : 107|2@0+ (1,0) [0|3] ""  FLZCU
 SG_ ICC_BkChrgCycleWen : 109|2@0+ (1,0) [0|3] ""  FLZCU
 SG_ ICC_BkChrgCycleTues : 111|2@0+ (1,0) [0|3] ""  FLZCU
 SG_ ICC_BkChrgCycleSun : 117|2@0+ (1,0) [0|3] ""  FLZCU
 SG_ ICC_BkChrgCycleSat : 119|2@0+ (1,0) [0|3] ""  FLZCU
 SG_ ICC_KeepWarmStrt : 124|5@0+ (1,0) [1|31] "日"  FLZCU
 SG_ ICC_KeepWarmStrtHour : 148|5@0+ (1,0) [0|23] "小时"  FLZCU
 SG_ ICC_KeepWarmStrtMin : 157|6@0+ (1,0) [0|59] "分钟"  FLZCU
 SG_ ICC_PetmodeFb : 159|2@0+ (1,0) [0|3] ""  FLZCU
 SG_ ICC_SentinelModeFaultSts : 161|2@0+ (1,0) [0|3] ""  FLZCU
 SG_ ICC_SentinelModeWorkingSts : 165|4@0+ (1,0) [0|15] ""  FLZCU
 SG_ ICC_SentinelModeSwitchSts : 167|2@0+ (1,0) [0|3] ""  FLZCU
 SG_ ICC_PetModeWarn : 170|3@0+ (1,0) [0|7] ""  FLZCU
 SG_ ICC_SentinelModeExitReason : 173|3@0+ (1,0) [0|7] ""  FLZCU
 SG_ ICC_SentinelModeAlarmSts : 175|2@0+ (1,0) [0|3] ""  FLZCU
 SG_ ICC_TBOXPetmodeReq : 178|2@0+ (1,0) [0|3] ""  FLZCU
 SG_ ICC_PetModeWarn_2 : 183|5@0+ (1,0) [0|31] ""  FLZCU
 SG_ ICC_GPSSailingSpeed_471h : 189|6@0+ (0.1,0) [0|6.3] "Km/h"  FLZCU
 SG_ ICM_FuelLevel : 215|8@0+ (1,0) [0|255] "L"  FLZCU
 SG_ ICM_AverageVehicleSpeed : 223|8@0+ (1,0) [0|255] "Km/h"  FLZCU
 SG_ ICM_DistenceToEmpty_Km : 231|11@0+ (1,0) [0|2047] "km"  FLZCU
 SG_ ICC_ElectronicFenceStsFed_471h : 233|2@0+ (1,0) [0|3] ""  FLZCU
 SG_ ICM_Maintenance_tips : 234|1@0+ (1,0) [0|1] ""  FLZCU
 SG_ ICM_FuelLevelFailSts : 235|1@0+ (1,0) [0|1] ""  FLZCU
 SG_ ICM_SumTrip : 247|14@0+ (1,0) [0|16383] "km"  FLZCU
 SG_ ICC_ChgSOCPrioritySet_471h : 249|2@0+ (1,0) [0|3] ""  FLZCU

BO_ 1140 EAMP_2: 8 EAMP
 SG_ STAT_AMPSoundEffectSupTreble : 59|4@0+ (1,0) [0|15] ""  ICC
 SG_ STAT_AMPMediaDuck : 1|2@0+ (1,0) [0|3] ""  ICC
 SG_ STAT_AMPSpeedVolume : 5|3@0+ (1,0) [0|7] ""  ICC
 SG_ STAT_AMPMute : 7|2@0+ (1,0) [0|3] ""  ICC
 SG_ STAT_AMPRestoreDefaults : 9|2@0+ (1,0) [0|3] ""  ICC
 SG_ STAT_AMPAlarmVolume : 13|4@0+ (1,0) [0|15] ""  ICC
 SG_ STAT_Headrest_Mode : 15|2@0+ (1,0) [0|3] ""  ICC
 SG_ STAT_AMPSoundEffectMegaBass : 19|4@0+ (1,0) [0|15] ""  ICC
 SG_ STAT_AMPSoundEffectMidBass : 23|4@0+ (1,0) [0|15] ""  ICC
 SG_ STAT_AMPSoundEffectMidTreble : 27|4@0+ (1,0) [0|15] ""  ICC
 SG_ STAT_VirtualSbwfrOnOff : 29|2@0+ (1,0) [0|3] ""  ICC
 SG_ STAT_SurndFnOnOff : 31|2@0+ (1,0) [0|3] ""  ICC
 SG_ STAT_AMPBackgroundVolume : 37|6@0+ (1,0) [0|63] ""  ICC
 SG_ STAT_AMPSoundBypass : 39|2@0+ (1,0) [0|3] ""  ICC
 SG_ STAT_AMPPwrRdySts : 41|2@0+ (1,0) [0|3] ""  ICC
 SG_ STAT_AMPVersion : 47|6@0+ (1,0) [0|63] ""  ICC

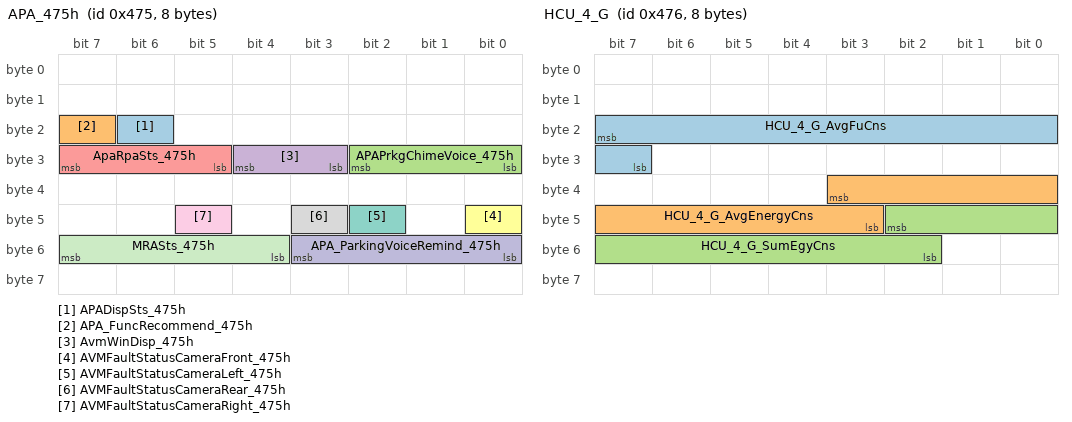
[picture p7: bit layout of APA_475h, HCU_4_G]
BO_ 1141 APA_475h: 8 FLZCU
 SG_ APADispSts_475h : 22|1@0+ (1,0) [0|1] ""  ICC
 SG_ APA_FuncRecommend_475h : 23|1@0+ (1,0) [0|1] ""  ICC
 SG_ APAPrkgChimeVoice_475h : 26|3@0+ (1,0) [0|7] ""  ICC
 SG_ AvmWinDisp_475h : 28|2@0+ (1,0) [0|3] ""  ICC
 SG_ ApaRpaSts_475h : 31|3@0+ (1,0) [0|7] ""  ICC
 SG_ AVMFaultStatusCameraFront_475h : 40|1@0+ (1,0) [0|1] ""  ICC
 SG_ AVMFaultStatusCameraLeft_475h : 42|1@0+ (1,0) [0|1] ""  ICC
 SG_ AVMFaultStatusCameraRear_475h : 43|1@0+ (1,0) [0|1] ""  ICC
 SG_ AVMFaultStatusCameraRight_475h : 45|1@0+ (1,0) [0|1] ""  ICC
 SG_ APA_ParkingVoiceRemind_475h : 51|4@0+ (1,0) [0|15] ""  ICC
 SG_ MRASts_475h : 55|4@0+ (1,0) [0|15] ""  ICC

BO_ 1142 HCU_4_G: 8 FLZCU
 SG_ HCU_4_G_AvgFuCns : 23|9@0+ (0.1,0) [0|50] "L/100km"  ICC
 SG_ HCU_4_G_AvgEnergyCns : 35|9@0+ (0.1,0) [0|50] "L/100km"  ICC
 SG_ HCU_4_G_SumEgyCns : 42|9@0+ (0.1,0) [0|50] "L/100km"  ICC

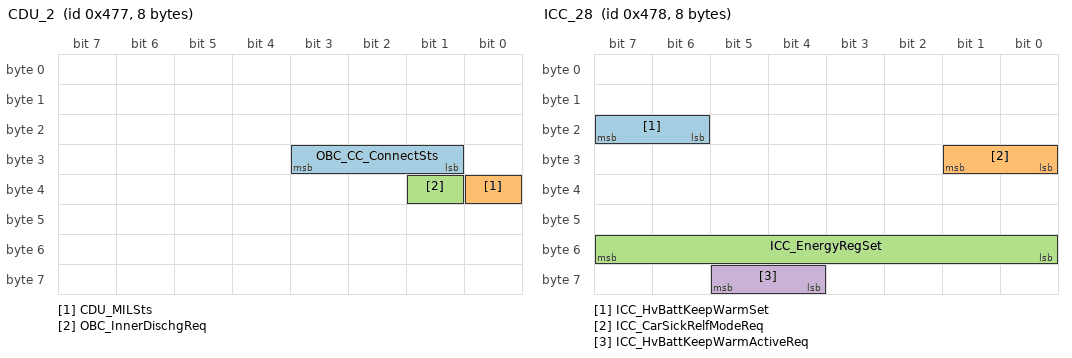
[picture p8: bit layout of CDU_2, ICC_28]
BO_ 1143 CDU_2: 8 FLZCU
 SG_ OBC_CC_ConnectSts : 27|3@0+ (1,0) [0|7] ""  ICC
 SG_ CDU_MILSts : 32|1@0+ (1,0) [0|1] ""  ICC
 SG_ OBC_InnerDischgReq : 33|1@0+ (1,0) [0|1] ""  ICC

BO_ 1144 ICC_28: 8 ICC
 SG_ ICC_HvBattKeepWarmSet : 23|2@0+ (1,0) [0|3] ""  FLZCU
 SG_ ICC_CarSickRelfModeReq : 25|2@0+ (1,0) [0|3] ""  FLZCU
 SG_ ICC_EnergyRegSet : 55|8@0+ (1,-1) [-1|100] "%"  FLZCU
 SG_ ICC_HvBattKeepWarmActiveReq : 61|2@0+ (1,0) [0|3] ""  FLZCU

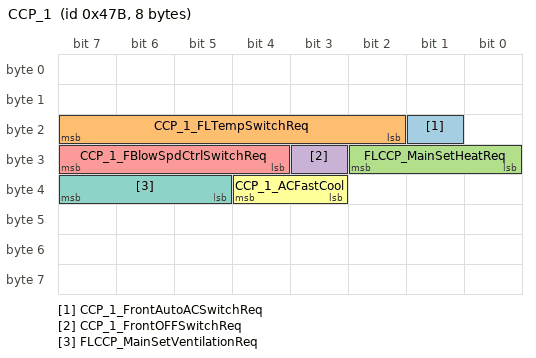
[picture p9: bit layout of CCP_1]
BO_ 1147 CCP_1: 8 FLZCU
 SG_ CCP_1_FrontAutoACSwitchReq : 17|1@0+ (1,0) [0|1] ""  ICC
 SG_ CCP_1_FLTempSwitchReq : 23|6@0+ (0.5,15.5) [15.5|30.5] "℃"  ICC
 SG_ FLCCP_MainSetHeatReq : 26|3@0+ (1,0) [0|7] ""  ICC
 SG_ CCP_1_FrontOFFSwitchReq : 27|1@0+ (1,0) [0|1] ""  ICC
 SG_ CCP_1_FBlowSpdCtrlSwitchReq : 31|4@0+ (1,0) [0|15] ""  ICC
 SG_ CCP_1_ACFastCool : 36|2@0+ (1,0) [0|3] ""  ICC
 SG_ FLCCP_MainSetVentilationReq : 39|3@0+ (1,0) [0|7] ""  ICC

BO_ 1148 TBOX_7: 32 FLZCU
 SG_ TBOX_BkChrgStartTimeDay : 23|5@0+ (1,0) [1|31] "日"  ICC
 SG_ TBOX_BkChrgStartTimeeHour : 31|5@0+ (1,0) [0|23] "小时"  ICC
 SG_ TBOX_GPSSwitchSts : 33|2@0+ (1,0) [0|3] ""  ICC
 SG_ TBOX_BkChrgStartTimeMin : 39|6@0+ (1,0) [0|59] "分钟"  ICC
 SG_ TBOX_BkChrgStartTimeMonth : 47|4@0+ (1,0) [1|12] "月"  ICC
 SG_ TBOX_BkChrgStartTimeYear : 55|16@0+ (1,1900) [1900|9999] "年"  ICC
 SG_ TBOX_BkChrgDuration : 87|12@0+ (1,0) [0|1440] "min"  ICC
 SG_ TBOX_BkChrgCycleType : 91|3@0+ (1,0) [0|7] ""  ICC
 SG_ TBOX_BkChrgCycleThur : 97|2@0+ (1,0) [0|3] ""  ICC
 SG_ TBOX_BkChrgCycleWen : 99|2@0+ (1,0) [0|3] ""  ICC
 SG_ TBOX_BkChrgCycleTues : 101|2@0+ (1,0) [0|3] ""  ICC
 SG_ TBOX_BkChrgCycleMon : 103|2@0+ (1,0) [0|3] ""  ICC
 SG_ TBOX_BkChrgCycleSun : 107|2@0+ (1,0) [0|3] ""  ICC
 SG_ TBOX_BkChrgCycleSat : 109|2@0+ (1,0) [0|3] ""  ICC
 SG_ TBOX_BkChrgCycleFri : 111|2@0+ (1,0) [0|3] ""  ICC
 SG_ TBOX_KeepWarmStrt : 119|5@0+ (1,0) [1|31] "日"  ICC
 SG_ TBOX_KeepWarmStrtHour : 127|5@0+ (1,0) [0|23] "小时"  ICC
 SG_ TBOX_KeepWarmStrtMin : 151|6@0+ (1,0) [0|59] "分钟"  ICC
 SG_ TimeToStartSentinelDayFed_47Ch : 153|2@0+ (1,0) [0|3] "日"  ICC
 SG_ TimeToStartSentinelHourFed_47Ch : 158|5@0+ (1,0) [0|31] "小时"  ICC
 SG_ TimeToStartSentinelMinutFed_47Ch : 165|6@0+ (1,0) [0|63] "分钟"  ICC
 SG_ TimeToStopSentinelHourFed_47Ch : 172|5@0+ (1,0) [0|31] "小时"  ICC
 SG_ TimeToStopSentinelMinutFed_47Ch : 181|6@0+ (1,0) [0|63] "分钟"  ICC
 SG_ ReservationSentinelSts_Fed_47Ch : 183|2@0+ (1,0) [0|3] ""  ICC

BO_ 1149 IMMO_VCC_12: 8 FLZCU
 SG_ IMMO_Teach_VCC : 7|64@0+ (1,0) [0|1.84467440737096E+019] ""  ICC

BO_ 1150 ICC_BD_11: 8 ICC
 SG_ ICC_BD_11_CRC : 7|8@0+ (1,0) [0|255] ""  FLZCU
 SG_ ICC_BD_11_RollgCntr : 11|4@0+ (1,0) [0|14] ""  FLZCU
 SG_ ICC_CPDDelaySwitchSet : 13|2@0+ (1,0) [0|3] ""  FLZCU
 SG_ ICC_PPMIDBSRBPASet : 17|2@0+ (1,0) [0|3] ""  FLZCU
 SG_ ICC_PPMIDHwSet : 19|2@0+ (1,0) [0|3] ""  FLZCU
 SG_ ICC_FLDoorButton : 25|2@0+ (1,0) [0|3] ""  FLZCU
 SG_ ICC_FRDoorButton : 27|2@0+ (1,0) [0|3] ""  FLZCU
 SG_ ICC_DriveDrosinessLevel : 31|3@0+ (1,0) [0|7] ""  FLZCU
 SG_ ICC_RRDoorButton : 33|2@0+ (1,0) [0|3] ""  FLZCU
 SG_ ICC_RLDoorButton : 35|2@0+ (1,0) [0|3] ""  FLZCU
 SG_ ICC_CloseAllDoors : 37|2@0+ (1,0) [0|3] ""  FLZCU
 SG_ ICC_DoorRemoteKeyControlEnable : 39|2@0+ (1,0) [0|3] ""  FLZCU
 SG_ ICC_SetOpenAngle : 41|2@0+ (1,0) [0|3] ""  FLZCU
 SG_ ICC_CPDSwitchSet : 43|2@0+ (1,0) [0|3] ""  FLZCU
 SG_ ICC_FrontDoorPowerMode : 45|2@0+ (1,0) [0|3] ""  FLZCU
 SG_ ICC_RearDoorPowerMode : 47|2@0+ (1,0) [0|3] ""  FLZCU
 SG_ ICC_PedalCloseDriverDoorEnable : 49|2@0+ (1,0) [0|3] ""  FLZCU
 SG_ RR_Door_RearScreen_Control : 51|2@0+ (1,0) [0|3] ""  FLZCU
 SG_ ICC_RearDoorVoiceControlEnable : 53|2@0+ (1,0) [0|3] ""  FLZCU
 SG_ ICC_FLVoiceControl : 55|2@0+ (1,0) [0|3] ""  FLZCU
 SG_ ICC_FRVoiceControl : 57|2@0+ (1,0) [0|3] ""  FLZCU
 SG_ ICC_RRVoiceControl : 59|2@0+ (1,0) [0|3] ""  FLZCU
 SG_ ICC_RLVoiceControl : 61|2@0+ (1,0) [0|3] ""  FLZCU
 SG_ RL_Door_RearScreen_Control : 63|2@0+ (1,0) [0|3] ""  FLZCU

BO_ 1151 VCC_IMMO_12: 8 ICC
 SG_ VCC_Teach_IMMO : 7|64@0+ (1,0) [0|1.84467440737096E+019] ""  FLZCU

BO_ 1152 TBOX_8: 16 FLZCU
 SG_ TBOX_PetmodeSetTemperature : 118|5@0+ (0.5,15.5) [15.5|30.5] "℃"  ICC

BO_ 1155 ASU_3: 16 FLZCU
 SG_ ASU_3_horizontalSts : 55|2@0+ (1,0) [0|3] ""  ICC
 SG_ ASU_3_horizontalmodeFb : 58|3@0+ (1,0) [0|7] ""  ICC

BO_ 1157 ICC_DA_15: 8 ICC
 SG_ ICC_DA_15_CRC : 7|8@0+ (1,0) [0|255] ""  FLZCU
 SG_ ICC_DA_15_RollgCntr : 11|4@0+ (1,0) [0|14] ""  FLZCU
 SG_ ICC_DA_15_Resd : 15|4@0+ (1,0) [0|15] ""  FLZCU
 SG_ ICC_DA_15_BSDLCWSettingSt : 17|2@0+ (1,0) [0|3] ""  FLZCU
 SG_ ICC_DA_15_DOWSettingSt : 19|2@0+ (1,0) [0|3] ""  FLZCU
 SG_ ICC_DA_15_RCWSettingSt : 21|2@0+ (1,0) [0|3] ""  FLZCU
 SG_ ICC_DA_15_RCTARCTBWarnType : 23|2@0+ (1,0) [0|3] ""  FLZCU
 SG_ ICC_DA_15_FCTAFCTBWarnType : 25|2@0+ (1,0) [0|3] ""  FLZCU
 SG_ ICC_DA_15_FrontPDCMuteSet : 26|1@0+ (1,0) [0|1] ""  FLZCU
 SG_ ICC_DA_15_FKPMuteSet : 27|1@0+ (1,0) [0|1] ""  FLZCU
 SG_ ICC_DA_15_ExtremeEnergySaveMode : 28|1@0+ (1,0) [0|1] ""  FLZCU
 SG_ Driver_AbnormalBehavior : 33|2@0+ (1,0) [0|3] ""  FLZCU
 SG_ Dms_Status : 36|3@0+ (1,0) [0|7] ""  FLZCU
 SG_ Driver_EyeOnRoad : 39|3@0+ (1,0) [0|7] ""  FLZCU
 SG_ ICC_IHCfunctionSw : 41|2@0+ (1,0) [0|3] ""  FLZCU
 SG_ Dms_DriverPresence : 43|2@0+ (1,0) [0|3] ""  FLZCU
 SG_ Driver_GazeRegion : 47|4@0+ (1,0) [0|15] ""  FLZCU

BO_TX_BU_ 1078 : BBCM,PCL,PLG;
CM_ BO_ 1028 "捷途新增";
CM_ SG_ 1028 PEPS_WelcomeON "welcome light request
迎宾开启请求";
CM_ SG_ 1028 PEPS_VehicleSearchReq "VehicleSearchRequest
寻车请求";
CM_ SG_ 1028 PEPS_SATOReminder "Easy trunk function start light
进入后备箱区域激活ETR功能闪灯信号";
CM_ SG_ 1028 PEPS_PLGUnlockReq "PLG解锁指令";
CM_ SG_ 1028 PEPS_RKETrunkSts "实体钥匙尾门按键";
CM_ SG_ 1028 PEPS_SSBInhibitCWCSts "OFF档时点按SSB，发送1值。
OFF档，CWC接收到SSBInhibitCWCSts=1后屏蔽无线充电功能；";
CM_ SG_ 1028 PEPS_WirelessChargingCtrSts "发送1时，PEPS处于搜索遥控钥匙的状态，无线充电功能应关闭";
CM_ SG_ 1028 PEPS_EmgyShutdown "Emergency shut down. If happen ,Send three frame continuous signal 1
此信号代表发生过紧急熄火功能。如果没发生都是发0，如果发生了，连续发3帧1出来。";
CM_ SG_ 1028 PEPS_SSBInputFailure "The warning indicator the SSB is faulty";
CM_ SG_ 1028 PEPS_SmartSystemWarning1_1 "非OFF档关门钥匙不在车内报警";
CM_ SG_ 1028 PEPS_SmartSystemWarning2_2 "车速无钥匙报警";
CM_ SG_ 1028 PEPS_SmartSystemWarning3_1 "钥匙电池电量低报警";
CM_ SG_ 1028 PEPS_SmartSystemWarning3_2 "用于SSB启动时，非P档时启动报警";
CM_ SG_ 1028 PEPS_SmartSystemWarning4_2 "用于SSB启动时，未踩刹车提醒报警";
CM_ SG_ 1028 PEPS_SmartSystemWarning4_3 "下电不在P档报警";
CM_ SG_ 1028 PEPS_SystemWarning "PEPS系统故障提醒";
CM_ SG_ 1028 PEPS_BLTKeyPESts "蓝牙钥匙的PE功能开启关闭状态信号";
CM_ SG_ 1030 RearViewFoldSts "后视镜折叠状态";
CM_ SG_ 1030 FLZCU_AlrmSts "解防设防动作信号";
CM_ SG_ 1030 FLZCU_SteeringMode "个性化-转向模式反馈
拆帧转发至GL ,IC CAN 0x406(bit 81)";
CM_ SG_ 1030 FLZCU_OBDDiagOccupy "OBD诊断占用指示";
CM_ SG_ 1034 HCU_EmPwr "E-Motor power indication";
CM_ SG_ 1034 HCU_PowerModeFed "Power mode Feedback";
CM_ SG_ 1034 HCU_PowertrainFault "Powertrain fault";
CM_ SG_ 1034 HCU_PowerModeChangeFail "(Once triggered,send 5 frames 'Active 'immediately, then send 'No active')";
CM_ SG_ 1034 HCU_ChargingSts "charge status";
CM_ SG_ 1035 VCC_1_OTASts "OTA status";
CM_ SG_ 1035 VCC_1_DriveMode "驾驶模式状态信号/原股份信号
（此信号为驾驶模式真实状态反馈）";
CM_ SG_ 1037 ADAS_enum_AESSts_40Dh "AES软开关，OTA预留";
CM_ SG_ 1037 ADAS_enum_AudibleBeepRate_40Dh "报警频率";
CM_ SG_ 1037 ADAS_enum_FCTASettingStsFb_40Dh "FCTA&FCTB软开关信号";
CM_ SG_ 1037 ADAS_enum_RadarWorkSts_40Dh "雷达工作状态（PDC正常工作）";
CM_ SG_ 1037 ADAS_enum_PasSwitch_40Dh "雷达开关状态反馈（声音开关）";
CM_ SG_ 1037 ADAS_enum_MEBSts_40Dh "低速紧急制动软开关，OTA预留";
CM_ SG_ 1037 ADAS_enum_MAASts_40Dh "油门踏板防误踩软开关，OTA预留";
CM_ SG_ 1037 IHU_11_VoiceplayModeSwtSet_40Dh "辅助驾驶语音播报开关请求";
CM_ SG_ 1037 IHU_11_LightingBlueSwtSet_40Dh "辅助驾驶指示灯开关";
CM_ SG_ 1037 enum_CECULVDSOutputStatus_40Dh "智能驾驶控制器总成LVDS输出状态
0x0:无输出
0x1:输出";
CM_ BO_ 1041 "华为MDC新增";
CM_ SG_ 1041 ADS_RadarWarning0Distance_411h "雷达告警扇区与障碍物距离";
CM_ SG_ 1041 ADS_RadarWarning1Distance_411h "雷达告警扇区与障碍物距离";
CM_ SG_ 1041 ADS_RadarWarning2Distance_411h "雷达告警扇区与障碍物距离";
CM_ SG_ 1041 ADS_RadarWarning3Distance_411h "雷达告警扇区与障碍物距离";
CM_ SG_ 1041 ADS_RadarWarning4Distance_411h "雷达告警扇区与障碍物距离";
CM_ SG_ 1041 ADS_RadarWarning5Distance_411h "雷达告警扇区与障碍物距离";
CM_ SG_ 1041 ADS_RadarWarning6Distance_411h "雷达告警扇区与障碍物距离";
CM_ SG_ 1041 ADS_RadarWarning7Distance_411h "雷达告警扇区与障碍物距离";
CM_ SG_ 1041 ADS_RadarWarning8Distance_411h "雷达告警扇区与障碍物距离";
CM_ SG_ 1041 ADS_RadarWarning9Distance_411h "雷达告警扇区与障碍物距离";
CM_ SG_ 1041 ADS_RadarWarning10Distance_411h "雷达告警扇区与障碍物距离";
CM_ SG_ 1041 ADS_RadarWarning11Distance_411h "雷达告警扇区与障碍物距离";
CM_ SG_ 1041 ADS_RadarWarning12Distance_411h "雷达告警扇区与障碍物距离";
CM_ SG_ 1041 ADS_RadarWarning13Distance_411h "雷达告警扇区与障碍物距离";
CM_ SG_ 1041 ADS_RadarWarning14Distance_411h "雷达告警扇区与障碍物距离";
CM_ SG_ 1041 ADS_RadarWarning15Distance_411h "雷达告警扇区与障碍物距离";
CM_ SG_ 1041 ADS_RadarWarning2AcLvl_411h "雷达告警扇区与障碍物声音报警等级";
CM_ SG_ 1041 ADS_RadarWarning1AcLvl_411h "雷达告警扇区与障碍物声音报警等级";
CM_ SG_ 1041 ADS_RadarWarning0AcLvl_411h "雷达告警扇区与障碍物声音报警等级";
CM_ SG_ 1041 ADS_RadarWarning4AcLvl_411h "雷达告警扇区与障碍物声音报警等级";
CM_ SG_ 1041 ADS_RadarWarning3AcLvl_411h "雷达告警扇区与障碍物声音报警等级";
CM_ SG_ 1041 ADS_RadarWarning7AcLvl_411h "雷达告警扇区与障碍物声音报警等级";
CM_ SG_ 1041 ADS_RadarWarning6AcLvl_411h "雷达告警扇区与障碍物声音报警等级";
CM_ SG_ 1041 ADS_RadarWarning5AcLvl_411h "雷达告警扇区与障碍物声音报警等级";
CM_ SG_ 1041 ADS_RadarWarning10AcLvl_411h "雷达告警扇区与障碍物声音报警等级";
CM_ SG_ 1041 ADS_RadarWarning9AcLvl_411h "雷达告警扇区与障碍物声音报警等级";
CM_ SG_ 1041 ADS_RadarWarning8AcLvl_411h "雷达告警扇区与障碍物声音报警等级";
CM_ SG_ 1041 ADS_RadarWarning12AcLvl_411h "雷达告警扇区与障碍物声音报警等级";
CM_ SG_ 1041 ADS_RadarWarning11AcLvl_411h "雷达告警扇区与障碍物声音报警等级";
CM_ SG_ 1041 ADS_RadarWarning15AcLvl_411h "雷达告警扇区与障碍物声音报警等级";
CM_ SG_ 1041 ADS_RadarWarning14AcLvl_411h "雷达告警扇区与障碍物声音报警等级";
CM_ SG_ 1041 ADS_RadarWarning13AcLvl_411h "雷达告警扇区与障碍物声音报警等级";
CM_ SG_ 1041 ADC_MdcSentryAlarmMod_411h "ADS哨兵模式警告";
CM_ SG_ 1041 ADC_FuncReq_SentryModDetec_411h "哨兵模式功能维持信号";
CM_ SG_ 1041 ADC_FuncReq_SentryModWarn_411h "ADS哨兵模式告警唤醒功能报文";
CM_ BO_ 1042 "华为MDC新增";
CM_ SG_ 1042 ADS_CRC1_412h "Profile1A:E2E CRC (SAE J1850 CRC-8) for 8 Bytes
DataID:0x01DF";
CM_ SG_ 1042 ADS_RollgCntr1_412h "Profile1A:E2E Rolling message counter(the maximum value of Alive counter is 14)";
CM_ SG_ 1042 ADS_Resd1_412h "Profile1A:E2E Reserved";
CM_ SG_ 1042 ADS_RiFrntDowWarning_412h "右前门氛围灯报警";
CM_ SG_ 1042 ADS_LeFrntDowWarning_412h "左前门氛围灯报警";
CM_ SG_ 1042 ADS_AutoLightSwCtrl_412h "自动灯光控制（Auto）";
CM_ SG_ 1042 ADS_BrkBeamReq_412h "刹车灯开启请求";
CM_ SG_ 1042 ADS_RightMirrWarningCmd_412h "右后视镜告警请求";
CM_ SG_ 1042 ADS_LeftMirrWarningCmd_412h "左后视镜告警请求";
CM_ SG_ 1042 ADS_RiReDowWarning_412h "右后门氛围灯报警";
CM_ SG_ 1042 ADS_LeReDowWarning_412h "左后门氛围灯报警";
CM_ SG_ 1042 ADS_WshrReq_412h "洗涤点动开启请求";
CM_ SG_ 1042 ADS_SBeltControl_412h "主动安全带控制";
CM_ SG_ 1042 ADS_DoorLockReq_412h "车门解闭锁控制请求";
CM_ SG_ 1042 ADS_ReMirrReq_412h "后视镜控制请求";
CM_ SG_ 1042 ADS_LeFmtWinCtrl_412h "驾驶员侧车窗控制";
CM_ SG_ 1042 ADS_HornReq_412h "喇叭开启请求";
CM_ SG_ 1042 ADS_FrtWindshildHeatReq_412h "前风挡加热丝控制请求";
CM_ SG_ 1042 ADS_SeatShakeControl_412h "座椅震动提示";
CM_ SG_ 1042 ADS_TopWinCtrl_412h "天窗控制（若有）";
CM_ SG_ 1042 ADS_RiReWinCtrl_412h "右后侧车窗控制";
CM_ SG_ 1042 ADS_LeReWinCtrl_412h "左后侧车窗控制";
CM_ SG_ 1042 ADS_RiFmtWinCtrl_412h "副驾驶员侧车窗控制";
CM_ SG_ 1042 ADS_MdcCrtSts_412h "MDC工作状态";
CM_ SG_ 1042 ADAS_FctSts_412h "智驾功能状态";
CM_ SG_ 1042 ADS_ChargingPortCmd_412h "充电口控制";
CM_ SG_ 1042 ADS_FrontWiperReq_412h "雨刮开启请求";
CM_ SG_ 1042 ADS_PwrOnOffReq_412h "整车上下电控制请求
泊车上下电和上下Ready";
CM_ SG_ 1042 ADS_FlowReq_412h "MDC冷却液流速请求（百分比或枚举如下）";
CM_ SG_ 1042 ADS_ThmPostRun_412h "MDC液冷需求";
CM_ SG_ 1042 ADS_HVCtrlReq_412h "MDC请求高压";
CM_ SG_ 1042 ADS_HiBeamReq_412h "HMA远光灯控制请求";
CM_ SG_ 1042 ADS_HMAStatus_412h "智能远光灯状态";
CM_ SG_ 1042 ADS_hmaOnOffSts_412h "智能大灯辅助(HMA)功能开启/关闭状态信号";
CM_ BO_ 1043 "LIN转CAN";
CM_ SG_ 1043 EBS_U_BATT "Current measured battery voltage, max value is 18V.Invalid Raw Value:16383.";
CM_ SG_ 1044 HCU_EnergyFlow "Energy Flow（股份信号D01不使用)";
CM_ SG_ 1044 HCU_SetSOCFed "Set SOC Feedback";
CM_ SG_ 1044 HCU_2_G_LowBatteryInfo "0x1:No Request  无需显示
0x2:Request  弹窗提示动力电池电量过低，请立即插枪充电或切换到Ready充电（股份信号D01不使用)
0x3:Sail Request 航行模式下的低电量提示";
CM_ SG_ 1046 LBMS_LoWSocFlt "SOC过低故障(同时也是电量告警整车的标志)";
CM_ SG_ 1046 LBMS_EndLifeFlt "锂电池寿命终结信号，SOH≤70%置为1";
CM_ SG_ 1046 LBMS_SysFlt "低压电池故障状态";
CM_ SG_ 1046 LBMS_ThermRunawayFlt "热失控故障";
CM_ SG_ 1046 LBMS_LowPowerRemind "锁电信号提示";
CM_ SG_ 1056 ICC_DSBH_HeatReq "加热请求信号";
CM_ SG_ 1056 ICC_DSBH_SetTemp "设置加热温度，范围为30-65℃，即0x1E-0x41";
CM_ SG_ 1056 ICC_PSBH_HeatReq "加热请求信号";
CM_ SG_ 1056 ICC_PSBH_SetTemp "设置加热温度，范围为30-65℃，即0x1E-0x41";
CM_ SG_ 1057 VCU_shfChk "上报N档文字提醒信息";
CM_ SG_ 1057 VCU_TowingMode "上报拖车模式提醒信息";
CM_ SG_ 1057 VCU_ChgSocSetFed "SOC设置反馈";
CM_ SG_ 1057 VCU_EngyConsuPer50Km "最近行驶50Km换算的平均百公里电耗";
CM_ SG_ 1057 VCU_BookChrgSetFailRes "预约失败原因反馈";
CM_ SG_ 1057 VCU_BookChrgFailRes "无法进入预约充电原因反馈";
CM_ SG_ 1057 VCU_BookChrgStsFb "预约充电状态";
CM_ SG_ 1057 HCU_EngineSelfMaintain "增程发动机自启维护";
CM_ SG_ 1059 DrvSeatHeatLevelCmdvelCmd_423h "一排主驾座椅加热信号";
CM_ SG_ 1059 ICC_FRSeatHeatLevelCmd "一排副驾座椅加热信号";
CM_ SG_ 1059 ICC_TrunkSW "后备箱开关";
CM_ SG_ 1059 ICC_Set_PLGOperateSts "电动尾门开度调节
0x0:Not active";
CM_ SG_ 1059 ICC_RRSeatHeatLevelCmd "二排右座椅加热";
CM_ SG_ 1059 DrvSecSeatHeatLevelCmd_423h "二排主驾侧座椅加热";
CM_ SG_ 1059 ICC_FRSeatVentLevelCmd "副驾座椅通风";
CM_ SG_ 1059 DrvSeatVentLevelCmd_423h "主驾座椅通风";
CM_ SG_ 1059 ICC_FrontWiperMaintenanceMode "大屏设置前雨刮维修
0x1:ON 进入维修
0x2: OFF退出维修";
CM_ SG_ 1059 ICC_RRSeatVentLevelCmd "二排右座椅通风";
CM_ SG_ 1059 DrvSecSeatVentLevelCmd_423h "二排主驾侧座椅通风";
CM_ SG_ 1059 PLG_ControlReq_423h "电尾门开启请求";
CM_ SG_ 1059 ICC_RearWiperMaintenanceMode "大屏设置后雨刮维修
0x1:ON 进入维修
0x2: OFF退出维修";
CM_ SG_ 1060 InforDisplay_424h "误操作提示信号";
CM_ BO_ 1061 "LIN-CAN";
CM_ SG_ 1061 DriverSeatMsgStr_LvlSts "0x0:关
0x1:低
0x2:中
0x3:高
CANID0x458";
CM_ SG_ 1061 DriverSeatMsg_ModeSts "0x0:无动作
0x1:背部激活-脉冲模式
0x2:背部放松-波浪模式
0x3背部舒缓-:猫步模式
0x4:脊柱松弛-单排模式
0x5:腰部放松-交叉模式
0x6:腰部激活-蝶形模式
0x7:背部舒展-腰部按摩模式
0x8:肩部放松-蛇形模式
0x9:特殊模式1
0xA:特殊模式2
0xB:特殊模式3
0xC:特殊模式4
CANID0x458";
CM_ SG_ 1061 Drv_Seat_ActvBolster_MdSts "0x0:无动作
0x1:主动侧翼模式关
0x2:主动侧翼标准
0x3:主动侧翼灵敏";
CM_ SG_ 1061 Drv_Seat_LBolster_Sts "0x0:无动作
0x1:左侧翼充气
0x2:左侧翼放气
0x3:左侧翼故障";
CM_ SG_ 1061 Drv_Seat_RBolster_Sts "0x0:无动作
0x1:右侧翼充气
0x2:右侧翼放气
0x3:右侧翼故障";
CM_ BO_ 1063 "触发一次发送三帧有效+三帧 Not Active";
CM_ SG_ 1063 TBOX_PetmodeSwitch "宠物模式远程开关信号";
CM_ SG_ 1063 TBOX_SentinelModeSw "哨兵开关";
CM_ SG_ 1063 TBOX_ElectronicFenceReq_427h "电子围栏开启状态";
CM_ BO_ 1065 "LIN-CAN";
CM_ SG_ 1065 LeftSeatMsgStr_LvlSts "0x0:关
0x1:低
0x2:中
0x3:高";
CM_ SG_ 1065 LeftSeatMsg_ModeSts "0x0:无动作
0x1:背部激活-脉冲模式
0x2:背部放松-波浪模式
0x3背部舒缓-:猫步模式
0x4:脊柱松弛-单排模式
0x5:腰部放松-交叉模式
0x6:腰部激活-蝶形模式
0x7:背部舒展-腰部按摩模式
0x8:肩部放松-蛇形模式
0x9:特殊模式1
0xA:特殊模式2
0xB:特殊模式3
0xC:特殊模式4";
CM_ BO_ 1069 "LIN-CAN";
CM_ SG_ 1069 PassSeatMsgStr_LvlSts "0x0:关
0x1:低
0x2:中
0x3:高";
CM_ SG_ 1069 PassSeatMsg_ModeSts "0x0:无动作
0x1:背部激活-脉冲模式
0x2:背部放松-波浪模式
0x3背部舒缓-:猫步模式
0x4:脊柱松弛-单排模式
0x5:腰部放松-交叉模式
0x6:腰部激活-蝶形模式
0x7:背部舒展-腰部按摩模式
0x8:肩部放松-蛇形模式
0x9:特殊模式1
0xA:特殊模式2
0xB:特殊模式3
0xC:特殊模式4
CANID0x458";
CM_ SG_ 1070 CWCR_42Eh_CRC1 "Profile1A:E2E CRC (SAE J1850 CRC-8) for 8 Bytes
DataID:No ASIL requirements.Not configure
CRC Reserved.";
CM_ SG_ 1070 CWCR_42Eh_RollgCntr1 "Profile1A:E2E Rolling message counter(the maximum value of Alive counter is 14)";
CM_ SG_ 1070 CWCR_42Eh_Resd1 "Profile1A:E2E Reserved";
CM_ SG_ 1070 ChargingSts_42Eh "无线充电器充电状态(DVD接收显示)
0x0: 没有充电
0x1: 充电中
0x2: 充电完成
0x3:充电故障";
CM_ SG_ 1070 WorkingSts_42Eh "无线充电器工作状态(DVD接收显示)
0x0: 无线充电器关闭
0x1: 无线充电器打开";
CM_ SG_ 1070 Phoneforgotten_42Eh "手机是否遗忘在无线充电器上(DVD接收驱动手机遗忘报警)
0x0:手机没有遗忘
0x1:手机遗忘提醒";
CM_ SG_ 1070 PhoneforgottenONOFFSts_42Eh "手机遗忘提醒功能是否打开
0x0:功能关闭
0x1:功能打开";
CM_ SG_ 1070 ChrgFlt_42Eh "无线充电器充电故障";
CM_ SG_ 1070 ChargingSts_R_42Eh "无线充电器充电状态(DVD接收显示)
0x0: 副驾手机没有充电
0x1: 副驾手机充电中
0x2: 副驾手机充电完成
0x3:副驾手机充电故障";
CM_ SG_ 1070 WorkingSts_R_42Eh "无线充电器工作状态(DVD接收显示)
0x0: 副驾无线充电器关闭
0x1: 副驾无线充电器打开";
CM_ SG_ 1070 Phoneforgotten_R_42Eh "手机是否遗忘在无线充电器上(DVD接收驱动手机遗忘报警)
0x0:副驾手机没有遗忘
0x1:副驾手机遗忘提醒";
CM_ SG_ 1070 PhoneforgottenONOFFStsR_42Eh "副驾手机遗忘提醒功能是否打开
0x0:功能关闭
0x1:功能打开";
CM_ SG_ 1070 ChrgFlt_R_42Eh "副驾手机无线充电器充电故障";
CM_ BO_ 1071 "域控直发";
CM_ SG_ 1071 FLZCU_CarSearhSetSW "寻车提示设置状态";
CM_ SG_ 1071 FLZCU_AutoFoldSts "后视镜自动折叠状态";
CM_ SG_ 1071 FLZCU_AutolockSts "设置自动落锁模式";
CM_ SG_ 1071 FLZCU_FGHeat_Req_CmdFeedback "前风挡加热反馈信号";
CM_ SG_ 1071 FLZCU_WindowInhibitSts "车窗禁止状态";
CM_ SG_ 1071 FLZCU_AutoReadLightSts "自动顶灯开关状态";
CM_ SG_ 1071 FLZCU_HeatingSW "后视镜加热开关状态";
CM_ SG_ 1071 FLZCU_AutoHeatingFb "雨天后视镜自动加热设置项";
CM_ SG_ 1071 FLZCU_SteerNeedMemory "方向盘停止调节，是否需要记忆";
CM_ SG_ 1071 FLZCU_LowBeamFaults "近光灯故障";
CM_ SG_ 1071 FLZCU_RearNeedMemory "后视镜停止调节，是否需要记忆";
CM_ SG_ 1071 FLZCU_BrkLightFaults "制动灯故障";
CM_ SG_ 1071 FLZCU_TurnLiSwtSts "转向灯开关状态信号（需可自动复位）";
CM_ SG_ 1071 DrvHandleFoldedSts_42Fh "主驾门把手折叠状态";
CM_ SG_ 1071 DrvRearHandleFoldedSts_42Fh "主驾后门把手折叠状态";
CM_ SG_ 1071 PassHandleFoldedSts_42Fh "副驾门把手折叠状态";
CM_ SG_ 1071 PassRearHandleFoldedSts_42Fh "副驾后门把手折叠状态";
CM_ SG_ 1071 FLZCU_RvsExtMirrFbSts "后视镜倒车自动下翻开启关闭";
CM_ SG_ 1071 FLZCU_LightMainSwitchSts "小灯、近光、Auto开关位置";
CM_ SG_ 1071 FLZCU_BeamDelaySts "前照灯延迟时间";
CM_ SG_ 1071 FLZCU_LowBeamHighSts "反馈当前大灯高度调节等级";
CM_ SG_ 1071 FLZCU_WipeSensitivitySts "雨刮灵敏度当前状态";
CM_ SG_ 1071 FLZCU_WipeMaintenanceSWSts "雨刮维修开关当前状态";
CM_ SG_ 1071 FLZCU_HiBeamSwtSts "远光灯开关状态";
CM_ SG_ 1071 FLZCU_ImmoRequest "防盗认证需求";
CM_ SG_ 1071 FLZCU_AlarmWarnSetSW "设防提示设置项";
CM_ SG_ 1071 FLZCU_CleanModeStatus "洗车模式状态反馈给大屏";
CM_ SG_ 1071 DrvReleaseLockSts_42Fh "主驾电释放状态
0x0:None
0x1:已释放
0x2:释放中
0x3:已复位
0x4:复位中";
CM_ SG_ 1071 FLZCU_RearFogLightSts "后雾灯状态反馈";
CM_ SG_ 1071 PassFoglightSts_42Fh "副驾侧雾灯状态反馈";
CM_ SG_ 1071 DrvFoglightSts_42Fh "主驾侧雾灯状态,用于副驾侧雾灯开关判断";
CM_ SG_ 1071 FLZCU_RearFogLightFaults "后雾灯故障";
CM_ SG_ 1071 FLZCU_HighBeamFaults "远光灯故障";
CM_ SG_ 1071 FLZCU_HighBeamSts "远光灯状态";
CM_ SG_ 1071 FLZCU_LowBeamSts "近光灯状态";
CM_ SG_ 1071 FLZCU_ParkUnlockEnableFb "驻车解锁设置反馈";
CM_ SG_ 1071 DrvRearReleaseLockSts_42Fh "主驾后电释放状态
0x0:None
0x1:已释放
0x2:释放中
0x3:已复位
0x4:复位中";
CM_ SG_ 1071 FLZCU_EasyEntryExitFb "便捷进入\离车";
CM_ SG_ 1071 FLZCU_EmgyLiSwtSts "紧急报警灯开关";
CM_ SG_ 1071 FLZCU_HMASwSts "IHC激活状态";
CM_ SG_ 1071 FLZCU_DaytimeLight "日行灯状态";
CM_ SG_ 1071 FLZCU_FGHeatFaults "前风挡加热故障";
CM_ SG_ 1071 FLZCU_ParkLightFaults "位置灯故障";
CM_ SG_ 1071 FLZCU_LbatipVehPwrMod "负载限制仪表提示";
CM_ SG_ 1071 FLZCU_HMASwSts_MDC "整车HMA激活状态";
CM_ SG_ 1071 FLZCU_LVPowICDsp "低压电池故障仪表指示灯显示";
CM_ SG_ 1071 FLZCU_LockCarWinCloseFb "锁车关窗";
CM_ SG_ 1071 FLZCU_BrkLightSts "制动灯状态";
CM_ SG_ 1071 FLZCU_ReverseLightSts "倒车灯状态";
CM_ SG_ 1071 FLZCU_LowWashLqdWarning "清洗液液位低报警";
CM_ SG_ 1071 FLZCU_SteerWheelHeatingFb "方向盘加热反馈";
CM_ SG_ 1071 FLZCU_FrontFogLightSts "前雾灯状态反馈";
CM_ SG_ 1071 FLZCU_NapAreaFb "小憩模式开启区域设置反馈";
CM_ SG_ 1071 FLZCU_NapTimeFb "小憩模式时长设置反馈";
CM_ SG_ 1071 FLZCU_NapAlarmStatus "小憩模式闹铃提醒";
CM_ SG_ 1071 FLZCU_NapFailCause "小憩模式开启失败原因反馈
0x0:Not_Active
0x1:档位非P档
0x2:车速≠0km/h
0x3:前舱盖未关
0x4:后背门未关
0x5:左前门未关
0x6:右前门未关
0x7:左后门未关
0x8:右后门未关
0x9:低压电池电压低，不满足开启条件
0xA:高压电池电量低，不满足开启条件
0xB:制动踏板被踩下，不满足开启条件
0xC:电源档位非Comfortable档，不满足开启条件-捷途特有";
CM_ SG_ 1071 FLZCU_NapStatusFb "小憩模式开关设置反馈";
CM_ SG_ 1071 FLZCU_CleanModeFailCause "洗车模式开启失败提示";
CM_ SG_ 1071 LockCarSunRoofShadeCloseFb "遮阳帘锁车关窗设置反馈（大屏开关没打开，钥匙闭锁，遮阳帘不关闭）";
CM_ SG_ 1071 FLZCU_NapClosePrompt "小憩模式关闭提示信号
0x0:Not Active
0x1:低压电池电量低，退出小憩模式
0x2:高压电池电量低，退出小憩模式";
CM_ SG_ 1071 FLZCU_AutoWipingInhibit "洗车模式自动雨刮禁用状态";
CM_ SG_ 1071 FLZCU_RemoteUnlockFb "遥控解锁设置状态（默认为四门解锁）按键一次,仅解锁主驾车门、按键两次解锁四门";
CM_ SG_ 1071 FLZCU_FrntWiprSwSts "雨刮开关状态";
CM_ SG_ 1071 FLZCU_HazardLightSWSts_42Fh "双闪开关状态，触发后发三帧";
CM_ SG_ 1071 DrvRearWinSts_42Fh "主驾后车窗运行状态反馈";
CM_ SG_ 1071 DrvWinSts_42Fh "主驾车窗运行状态反馈";
CM_ SG_ 1071 FLZCU_DaytimeLightFaults "日行灯故障";
CM_ SG_ 1071 FLZCU_FrontFogLightFaults "前雾灯故障";
CM_ SG_ 1071 FLZCU_HomeLinkWelLightSetSts "HomeLink 迎宾灯设置状态";
CM_ SG_ 1071 FLZCU_HomeLinkArmHornSetSts "HomeLink设防鸣笛设置状态";
CM_ SG_ 1071 FLZCU_UIROpenStas "走近开关状态";
CM_ SG_ 1071 FLZCU_WALOpenStas "远离闭锁状态";
CM_ SG_ 1071 FLZCU_WelcomeOpenStas "迎宾灯状态";
CM_ SG_ 1071 FLZCU_RearWiprSwSts_42Fh "后雨刮状态";
CM_ SG_ 1071 FLZCU_ExtLiSwtClsSts "0x0: Not Active
0x1:外部灯全关
0x2:外部灯未全关";
CM_ SG_ 1072 AutoSeatHeatLevelsFb_430h "座椅自动加热设置状态反馈";
CM_ SG_ 1072 AutoSteerWhlHeatFb_430h "方向盘自动加热设置状态反馈";
CM_ SG_ 1072 AutoSeatVentLevelsFb_430h "座椅自动通风设置状态反馈";
CM_ SG_ 1072 DrvDoorSts_430h "主驾门状态（PT3阶段可发）";
CM_ SG_ 1072 DrvSeatBeltSW_430h "安全带检测开关，0为未插入，1为插入";
CM_ SG_ 1072 DrvRearWinPosn_430h "Rear Left Window Position车窗（当前可发）";
CM_ SG_ 1072 DrvSeatHeatLevels_430h "捷途需要改9档";
CM_ SG_ 1072 DrvRearChildProtectSwt_430h "主驾后儿童锁";
CM_ SG_ 1072 DrvSecSeatHeatLevels_430h "捷途需要改9档";
CM_ SG_ 1072 DrvSeatVentLevels_430h "捷途需要改9档";
CM_ SG_ 1072 DrvSecSeatVentLevels_430h "捷途需要改9档";
CM_ SG_ 1072 DrvWinPosn_430h "Front Left Window Position车窗（当前可发）";
CM_ SG_ 1072 FLZCU_RearWiperMaintenanceSts "后雨刮维修模式开关状态反馈（当前可发）";
CM_ SG_ 1072 FLZCU_FrontWiperMaintenanceSts "前雨刮维修模式开关状态反馈（当前可发）";
CM_ SG_ 1073 RearDoorSta_431h "尾门状态:
0x0:尾门关闭
0x1:尾门打开";
CM_ SG_ 1073 RearDoorMoveDirection_431h "尾门移动方向:
0x0:关门中
0x1:开门中
0x2:暂停";
CM_ SG_ 1073 RearDoorOpenDegree_431h "尾门实时开门比例反馈";
CM_ SG_ 1078 PLG_LatchSts "尾门门锁状态";
CM_ SG_ 1078 PLG_Set_PLGOperateStsFb "尾门设置高度状态反馈（实时反馈设置状态）（预留）";
CM_ SG_ 1079 BSCU_1_MotorLockSts "储物背包锁1状态反馈，对应3种状态：全锁，半锁，解锁，用于仪表接收到0x3:Unlocked时弹窗提醒小书包未锁";
CM_ BO_ 1087 "LIN-CAN";
CM_ SG_ 1087 RightSeatMsgStr_LvlSts "0x0:关
0x1:低
0x2:中
0x3:高";
CM_ SG_ 1087 RightSeatMsg_ModeSts "0x0:无动作
0x1:背部激活-脉冲模式
0x2:背部放松-波浪模式
0x3背部舒缓-:猫步模式
0x4:脊柱松弛-单排模式
0x5:腰部放松-交叉模式
0x6:腰部激活-蝶形模式
0x7:背部舒展-腰部按摩模式
0x8:肩部放松-蛇形模式
0x9:特殊模式1
0xA:特殊模式2
0xB:特殊模式3
0xC:特殊模式4";
CM_ SG_ 1095 RLCR_1_CRC1 "Profile1A:E2E CRC (SAE J1850 CRC-8) for 8 Bytes
DataID:0x0044";
CM_ SG_ 1095 RLCR_1_RollgCntr1 "Profile1A:E2E Rolling message counter(the maximum value of Alive counter is 14)";
CM_ SG_ 1095 RLCR_1_Resd1 "Profile1A:E2E Reserved";
CM_ SG_ 1095 RLCR_1_SysSt "System self-test State";
CM_ SG_ 1095 RLCR_1_BlkSts "Blockage Status";
CM_ SG_ 1095 RLCR_1_BSDWarn "BSD/LCA Warning";
CM_ SG_ 1096 TMS_AirPurgeReminderSts "空气净化提醒开关状态";
CM_ SG_ 1096 TMS_CirculationInTunnelsSts "隧道内循环状态";
CM_ SG_ 1096 TMS_First_BlowingSts "空调启动时第一口风状态";
CM_ SG_ 1096 TMS_BT_Reduce_Wind_SpeedSts "蓝牙通话降低风速状态";
CM_ SG_ 1096 TMS_CoolantFillSts "一键除气";
CM_ SG_ 1096 TMS_ParkingAirConditioningStatus "驻车空调状态工作状态";
CM_ SG_ 1096 TMS_crosscountry_coolingSts "越野散热状态";
CM_ SG_ 1096 TMS_ICC_Lightoff_Sts "香氛氛围灯开关状态";
CM_ SG_ 1096 TMS_UVC_LuminanceSts "UVC亮度反馈";
CM_ SG_ 1096 TMS_AutoDefogActiveSts "自动除雾开启后激活功能弹窗使用";
CM_ SG_ 1096 TMS_UVC_ControlSts "UVC控制反馈";
CM_ SG_ 1096 TMS_ICC_Memoff_Sts "香氛记忆开关状态";
CM_ SG_ 1096 TMS_keepwarmSet_TemperatureSts "恒温模式温度设置";
CM_ SG_ 1096 TMS_BiochemicalFuncSts "生化功能开关反馈";
CM_ SG_ 1096 TMS_TimedVentilationSts "大屏定时换气开关状态反馈";
CM_ SG_ 1096 TMS_LowbattACDisable_448h "低电量禁止开制冷制热提示";
CM_ SG_ 1096 TMS_SailEACDisable_448h "航行禁止制冷制热提示";
CM_ SG_ 1096 TMS_ICAstsFed_448h "空调防水执行器状态反馈";
CM_ SG_ 1099 ISGF_SysTempOvrInd "前发电机系统过温故障灯（捷途D01不使用）";
CM_ SG_ 1100 Set_AMPNaviVolume "Amplifier navigation volume status";
CM_ SG_ 1100 Set_AMPVRVolume "Amplifier voice recognize volume status";
CM_ SG_ 1100 Set_AMPKeyTone "Amplifier key tone status";
CM_ SG_ 1100 Set_AMPMediaVolume "Amplifier media volume status";
CM_ SG_ 1100 Set_AMPPhoneVolume "Amplifier phone volume status";
CM_ SG_ 1100 Set_AMPSoundFocus "Amplifier sound focus status";
CM_ SG_ 1100 Set_AMPSoundEffect "Amplifier sound effect status";
CM_ SG_ 1100 Set_AMPSoundEffectBass "Amplifier sound effect bass status";
CM_ SG_ 1100 Set_AMPSoundEffectMidrange "Amplifier sound effect midrange status";
CM_ SG_ 1100 Set_AMPSoundEffectTreble "Amplifier sound effect treble status";
CM_ SG_ 1100 Set_AMPSoundFieldBalance "Amplifier sound field balance status";
CM_ SG_ 1100 Set_AMPSoundFieldFader "Amplifier sound field fader status";
CM_ SG_ 1100 ICC_AMPVRVolume_44Ch "Amplifier voice recognize volume status";
CM_ SG_ 1100 Set_Headrest_Mode "Headrest_Mode";
CM_ SG_ 1100 Set_SurndFnOnOff "Surround Function On Off Switch";
CM_ SG_ 1100 Set_VirtualSbwfrOnOff "Virtual_Subwoofer_On_Off_Request";
CM_ BO_ 1104 "DA-IC";
CM_ SG_ 1104 RLCR_2_CRC1 "Profile1A:E2E CRC (SAE J1850 CRC-8) for 8 Bytes
DataID:0x0045";
CM_ SG_ 1104 RLCR_2_RollgCntr1 "Profile1A:E2E Rolling message counter(the maximum value of Alive counter is 14)";
CM_ SG_ 1104 RLCR_2_Resd1 "Profile1A:E2E Reserved";
CM_ SG_ 1104 RLCR_2_RCWWarn "Rear Collision Warning Warning";
CM_ SG_ 1104 RLCR_2_RCTAWarn "RCTA Warning（高配不发）";
CM_ SG_ 1104 RLCR_2_BSDLCWONOFFSts "BSD/LCA Switch status";
CM_ SG_ 1104 RLCR_2_DOWONOFFSts "Door open warning Switch status";
CM_ SG_ 1104 RLCR_2_RCWONOFFSts "Rear Collision Warning Switch Status";
CM_ SG_ 1104 RLCR_2_RCTARCTBONOFFSts "RCTA/RCTB Switch status（高配不发，低配无0x2）";
CM_ BO_ 1107 "捷途新增-BD2&GL网段";
CM_ SG_ 1107 TMS_CCP_FLTempSts "前排左侧温度设置";
CM_ SG_ 1107 TMS_CCP_FrontAutoACSts "前排自动功能";
CM_ SG_ 1107 TMS_CCP_FrontDefrostSts "前除霜";
CM_ SG_ 1107 TMS_CCP_FBlowSpdCtrlSts "前排风速设置";
CM_ SG_ 1107 TMS_CCP_FrontOFFSts "空调关闭";
CM_ SG_ 1107 TMS_CCP_ACStatus "ACStatus
AC_状态";
CM_ SG_ 1107 TMS_CCP_FRTempSts "前排右侧温度设置";
CM_ SG_ 1107 TMS_CCP_RecyMode "内外循环";
CM_ SG_ 1107 TMS_CCP_ACFastHeat "一键制热反馈";
CM_ SG_ 1107 TMS_CCP_ACFastCool "一键制冷反馈";
CM_ SG_ 1107 TMS_UVC_LuminanceBfReq "紫外线杀菌灯强度请求";
CM_ SG_ 1107 TMS_UVC_WorkingBfReq "紫外线杀菌灯请求";
CM_ SG_ 1107 TMS_ThrSetTempFb_C_453h "三排温度反馈
0x1F:Not_active";
CM_ SG_ 1107 TMS_ThrModeStsFb_453h "三排模式反馈";
CM_ SG_ 1107 TMS_ThrCLMSwitchFb_453h "三排空调状态反馈
Not_active-关闭空调
Active--打开空调";
CM_ SG_ 1107 TMS_ThrAutoSwitchFb_453h "Auto_Display_Status
空调自动状态显示";
CM_ SG_ 1107 TMS_ThrACReqKeyStsFb_453h "AC请求指示
压缩机状态显示信号,和发给EMS的AC请求信号需区分开";
CM_ SG_ 1109 CWC_1_CRC1 "Profile1A:E2E CRC (SAE J1850 CRC-8) for 8 Bytes
DataID:No ASIL requirements.Not configure
CRC Reserved.";
CM_ SG_ 1109 CWC_1_RollgCntr1 "Profile1A:E2E Rolling message counter(the maximum value of Alive counter is 14)";
CM_ SG_ 1109 CWC_1_Resd1 "Profile1A:E2E Reserved";
CM_ SG_ 1109 CWC_ChargingSts "无线充电器充电状态(DVD接收显示)
0x0: 没有充电
0x1: 充电中
0x2: 充电完成
0x3：充电故障";
CM_ SG_ 1109 CWC_workingSts "无线充电器工作状态(DVD接收显示)
0x0: 无线充电器关闭
0x1: 无线充电器打开";
CM_ SG_ 1109 CWC_Phoneforgotten "手机是否遗忘在无线充电器上(DVD接收驱动手机遗忘报警)
0x0:手机没有遗忘
0x1:手机遗忘提醒";
CM_ SG_ 1109 CWC_Phoneforgotten_ON_OFF_Sts "手机遗忘提醒功能是否打开
0x0:功能关闭
0x1:功能打开";
CM_ SG_ 1109 CWC_1_ChrgFlt "无线充电器充电故障
charge fault
0x5:NFC_card_protect_L(左舵车，右侧信号无效)";
CM_ SG_ 1109 CWC_ChargingSts_R "无线充电器充电状态(DVD接收显示)
0x0: 副驾手机没有充电
0x1: 副驾手机充电中
0x2: 副驾手机充电完成
0x3：副驾手机充电故障";
CM_ SG_ 1109 CWC_workingSts_R "无线充电器工作状态(DVD接收显示)
0x0: 副驾无线充电器关闭
0x1: 副驾无线充电器打开";
CM_ SG_ 1109 CWC_Phoneforgotten_R "手机是否遗忘在无线充电器上(DVD接收驱动手机遗忘报警)
0x0:副驾手机没有遗忘
0x1:副驾手机遗忘提醒";
CM_ SG_ 1109 CWC_Phoneforgotten_ON_OFF_Sts_R "副驾手机遗忘提醒功能是否打开
0x0:功能关闭
0x1:功能打开";
CM_ SG_ 1109 CWC_1_ChrgFlt_R "副驾手机无线充电器充电故障
charge fault
0x5:NFC_card_protect_R(右舵车，左侧信号无效)";
CM_ SG_ 1112 PassSeatMsgStr_LvlCmd_458h "0x0:未激活
0x1:关
0x2:低
0x3:中
0x4:高";
CM_ SG_ 1112 PassSeatMsg_ModeCmd_458h "0x0:无动作
0x1:脉冲模式
0x2:波浪模式
0x3:猫步模式
0x4:单排模式
0x5:交叉模式
0x6:蝶形模式
0x7:腰部按摩模式
0x8:蛇形模式
0x9:特殊模式1
0xA:特殊模式2
0xB:特殊模式3
0xC:特殊模式4";
CM_ SG_ 1112 DriverSeatMsgStr_Lvlcmd "0x0:未激活
0x1:关
0x2:低
0x3:中
0x4:高";
CM_ SG_ 1112 DriverSeatMsg_ModeCmd "0x0:无动作
0x1:背部激活-脉冲模式
0x2:背部放松-波浪模式
0x3背部舒缓-:猫步模式
0x4:脊柱松弛-单排模式
0x5:腰部放松-交叉模式
0x6:腰部激活-蝶形模式
0x7:背部舒展-腰部按摩模式
0x8:肩部放松-蛇形模式
0x9:特殊模式1
0xA:特殊模式2
0xB:特殊模式3
0xC:特殊模式4";
CM_ SG_ 1112 ICC_DSeatInOrDeflationCmd_458h "侧翼调节
0x1:充气
0x2:泄气";
CM_ SG_ 1112 ICC_DSeatBolsterModeCmd_458h "侧翼支撑设置
0x1:关闭
0x2:标准
0x3:灵敏";
CM_ SG_ 1112 PassSecSeatMsgStr_LvlCmd_458h "0x0:未激活
0x1:关
0x2:低
0x3:中
0x4:高";
CM_ SG_ 1112 PassSecSeatMsg_ModeCmd_458h "0x0:无动作
0x1:脉冲模式
0x2:波浪模式
0x3:猫步模式
0x4:单排模式
0x5:交叉模式
0x6:蝶形模式
0x7:腰部按摩模式
0x8:蛇形模式
0x9:特殊模式1
0xA:特殊模式2
0xB:特殊模式3
0xC:特殊模式4";
CM_ SG_ 1112 DrvSecSeatMsgStr_LvlCmd_458h "0x0:未激活
0x1:关
0x2:低
0x3:中
0x4:高";
CM_ SG_ 1112 DrvSecSeatMsg_ModeCmd_458h "0x0:无动作
0x1:脉冲模式
0x2:波浪模式
0x3:猫步模式
0x4:单排模式
0x5:交叉模式
0x6:蝶形模式
0x7:腰部按摩模式
0x8:蛇形模式
0x9:特殊模式1
0xA:特殊模式2
0xB:特殊模式3
0xC:特殊模式4";
CM_ SG_ 1119 Set_AMPMediaDuck "Media Duck request to amplifier/发送媒体降音需求给外置功放";
CM_ SG_ 1119 Set_AMPSpeedVolume "Amplifier vehicle speed volume compensation setting";
CM_ SG_ 1119 Set_AMPMute "Amplifier audio mute or not setting";
CM_ SG_ 1119 REQ_AMPA2BMediaSound "Head unit media sound request to amplifier";
CM_ SG_ 1119 REQ_AMPA2BNaviSound "Head unit navigation sound request to amplifier";
CM_ SG_ 1119 REQ_AMPA2BVRSound "Head unit VR sound request to amplifier";
CM_ SG_ 1119 REQ_AMPA2BTTSSound "Head unit TTS sound request to amplifier";
CM_ SG_ 1119 ICC_AMPPhoneVolume_45Fh "Amplifier phone volume status";
CM_ SG_ 1119 REQ_AMPA2BKeyTone "Head unit Beep sound request to amplifier";
CM_ SG_ 1119 Set_AMPRestoreDefaults "Amplifier audio restore defaults setting/恢复默认音频参数设置开关";
CM_ SG_ 1119 Set_AMPAlarmVolume "Amplifier instrument panel cluster alarm volume setting/警报音量值设定";
CM_ SG_ 1119 REQ_AMPA2BPhoneSound "Head unit BT Phone and Tbox sound request to amplifier/电话/Tbox音源需求设定";
CM_ SG_ 1119 Set_AMPSoundEffectMegaBass "Amplifier sound effect megabass setting/重低音设定";
CM_ SG_ 1119 Set_AMPSoundEffectMidBass "Amplifier sound effect midbass setting/中低音设定";
CM_ SG_ 1119 Set_AMPSoundEffectMidTreble "Amplifier sound effect midtreble setting/中高音设定";
CM_ SG_ 1119 Set_AMPSoundBypass "Amplifier sound bypass need/第三方APP打开时，外置功放做音效bypass处理";
CM_ SG_ 1119 Set_AMPA2BConfig "Amplifier A2B Config status/EAMP的A2B节点配置完成后，下发OK";
CM_ SG_ 1119 Set_AMPBackgroundVolume "Amplifier background media volume status/背景音（迎宾音）音量值设定";
CM_ SG_ 1119 ICC_AMPNaviVolume_45Fh "Amplifier navigation volume status";
CM_ SG_ 1120 RLHS_2_AmbBrightness "顶向光";
CM_ SG_ 1120 RLHS_LiSwithReason "开关灯切换原因
RLS_ LightSwithReason";
CM_ SG_ 1121 STAT_AMPNaviVolume "Amplifier navigation volume status
反馈-导航音量设定";
CM_ SG_ 1121 STAT_AMPVRVolume "Amplifier voice recognize volume status
反馈语音音量设定";
CM_ SG_ 1121 STAT_AMPKeyTone "Amplifier key tone status
反馈按键音开关";
CM_ SG_ 1121 STAT_AMPMediaVolume "Amplifier media volume status
反馈媒体音量设定";
CM_ SG_ 1121 STAT_AMPPhoneVolume "Amplifier phone volume status
反馈电话音量设定";
CM_ SG_ 1121 STAT_AMPSoundFocus "Amplifier sound focus status
反馈音场（最佳听音位）设定";
CM_ SG_ 1121 STAT_AMPSoundEffect "Amplifier sound effect status
反馈-音效设定（预设EQ）";
CM_ SG_ 1121 STAT_AMPSoundEffectBass "Amplifier sound effect bass status
反馈-低音设定（用户自定义EQ下）";
CM_ SG_ 1121 STAT_AMPSoundEffectMidrange "Amplifier sound effect midrange status
反馈-中音设定（用户自定义EQ下）";
CM_ SG_ 1121 STAT_AMPSoundEffectTreble "Amplifier sound effect treble status
反馈-高音设定（用户自定义EQ下）";
CM_ SG_ 1121 STAT_AMPSoundFieldBalance "Amplifier sound field balance status
反馈-Balance设定（用户自定义声场)";
CM_ SG_ 1121 STAT_AMPSoundFieldFader "Amplifier sound field fader status
反馈-反馈-Fader设定（用户自定义声场）";
CM_ SG_ 1121 STAT_REQ_AMPA2BMediaSound "Status of Head unit media sound request to amplifier
媒体音源需求状态";
CM_ SG_ 1121 STAT_REQ_AMPA2BNaviSound "Status of Head unit navigation sound request to amplifier
导航音源需求状态";
CM_ SG_ 1121 STAT_REQ_AMPA2BVRSound "Status of Head unit VR sound request to amplifier
VR/Siri音源需求状态";
CM_ SG_ 1121 STAT_REQ_AMPA2BTTSSound "Status of Head unit TTS sound request to amplifier
TTS音源需求状态";
CM_ SG_ 1121 STAT_REQ_AMPA2BPhoneSound "Status of Head unit BT Phone and Tbox sound request to amplifier
电话/Tbox音源需求状态";
CM_ SG_ 1121 STAT_REQ_AMPAlarm "Status of Instrument panel cluster alarm status to amplifier for chime play
警报音需求状态";
CM_ SG_ 1123 IMMOCodeWarningLightSts_463h "IMMO Code Warning Light Sts
发动机防盗警报灯状态，EMS发送信号给BCM，BCM接受并转发给ICM显示防盗指示报警灯.
00表示防盗程序成功执行完成，并存储信息/默认值，仪表报警灯熄灭；
01表示防盗验证程序没执行完，仪表LED灯常亮；
10表示防盗程序成功执行完，但钥匙ID密码没被存储在EMS里面，仪表LED闪烁；11表示此信号无效。";
CM_ SG_ 1123 ISS_Switch_Sts_463h "Start-stop switch state feedback signal 启停开关状态反馈";
CM_ SG_ 1127 DCDC_FaultLevelSts "DCDC故障等级状态（捷途新增等级4）";
CM_ SG_ 1128 ISS_Sts_GS_468h "Start-stop state for China 6 Emission";
CM_ SG_ 1128 PromptMesg_468h "PromptMessage真空泵消息提示信号

当ICM接收到0x01时，仪表盘提示:“真空泵测试无法完成，请松开脚刹。”";
CM_ SG_ 1128 GPFWarning_468h "This signal indicates the status of GPF warning which need ICM to  inform driver. 
0x1: Green light
0x2: Yellow light";
CM_ SG_ 1128 FuelRollingCounter_468h "Instantaneous fuel consumption pulse signal
瞬时油耗脉冲信号";
CM_ SG_ 1128 MILSts_468h "MIL Status MIL灯状态";
CM_ SG_ 1128 IEMSts_468h "IEM Status 智能发电机状态";
CM_ SG_ 1128 EPCSts_468h "EPC status   EPC状态";
CM_ SG_ 1128 FuelRollingCounterValidData_468h "Valid check bit of the signal FuelRollingCounter 瞬时油耗脉冲信号有效位";
CM_ SG_ 1128 CruiseControlStsForDisplay_468h "Cruise Control Status For Display
巡航控制状态显示";
CM_ SG_ 1128 Crosscountry_coolingSts_468h "越野散热状态";
CM_ SG_ 1129 EngineCoolantTemp_469h "Engine Coolant Temperture发动机冷却液温度";
CM_ SG_ 1129 EngineSpeed_469h "Engine Speed发动机转速";
CM_ SG_ 1129 EngineSpeedValidData_469h "Valid check bit of the signal EngineSpeed发动机转速有效位";
CM_ SG_ 1130 TCU_23_GBFaultstatus "换挡故障状态";
CM_ SG_ 1130 TCU_23_TeachInState "TCU自学习状态";
CM_ SG_ 1130 TCU_23_CluSelfLrng "离合器自学习状态（T1J FL2智驾版3DHT使用）";
CM_ SG_ 1131 GBPositoionDisplay_46Bh "gear box positoion Display
挡位显示给仪表";
CM_ SG_ 1131 SpeParkSts_46Bh "印尼特殊驻车反馈信号";
CM_ SG_ 1131 GBFaultstatus_46Bh "Activation gearbox error Lamp, only for ICM including LCD to light LED and LCD. This signal should be sent with “AGErrorLamp” simultaneously
For 6DCT,only has 00/01.
For CVT/AMT/AT, only has 00/01/10.
变速箱故障状态";
CM_ SG_ 1131 ClutchTemperature_46Bh "Clutch temperature
离合器温度";
CM_ SG_ 1136 VCC_3_CRC "Profile1A:E2E CRC (SAE J1850 CRC-8) for 32 Bytes
DataID:0x0070";
CM_ SG_ 1136 VCC_3_RollgCntr "Profile1A:E2E Rolling message counter(the maximum value of Alive counter is 14)";
CM_ SG_ 1136 VCC_3_Resd1 "Profile1A:E2E Reserved";
CM_ SG_ 1136 VCC_3_SN "Message ID信号值.当VCC成功被写入配置信息时，VCC以100ms的周期滚动发送报文，Message ID信号值从1到32循环发送。";
CM_ SG_ 1137 ICC_BookChrgSetReq "预约充电开启/取消设置请求";
CM_ SG_ 1137 ICC_BkChrgStartTimeYear "预约充电开始时间设置-年";
CM_ SG_ 1137 ICC_BkChrgStartTimeDay "预约充电开始时间设置-日";
CM_ SG_ 1137 ICC_BkChrgStartTimeHour "预约充电开始时间设置-时";
CM_ SG_ 1137 ICC_BkChrgStartTimemMin "预约充电开始时间设置-分";
CM_ SG_ 1137 ICC_BkChrgDuration "本地预约充电时长设置";
CM_ SG_ 1137 ICC_BkChrgStartTimeMonth "预约充电开始时间设置-月";
CM_ SG_ 1137 ICC_BkChrgCycleMon "预约充电周期循环_每周一循环";
CM_ SG_ 1137 ICC_StopChrgReq "结束充电请求";
CM_ SG_ 1137 ICC_BkChrgCycleType "本地预约充电周期循环方式";
CM_ SG_ 1137 ICC_BkChrgCycleFri "预约充电周期循环_每周五循环";
CM_ SG_ 1137 ICC_BkChrgCycleThur "预约充电周期循环_每周四循环";
CM_ SG_ 1137 ICC_BkChrgCycleWen "预约充电周期循环_每周三循环";
CM_ SG_ 1137 ICC_BkChrgCycleTues "预约充电周期循环_每周二循环";
CM_ SG_ 1137 ICC_BkChrgCycleSun "预约充电周期循环_每周日循环";
CM_ SG_ 1137 ICC_BkChrgCycleSat "预约充电周期循环_每周六循环";
CM_ SG_ 1137 ICC_KeepWarmStrt "插枪保温开始时间设置-日";
CM_ SG_ 1137 ICC_KeepWarmStrtHour "插枪保温开始时间设置-时";
CM_ SG_ 1137 ICC_KeepWarmStrtMin "插枪保温开始时间设置-分";
CM_ SG_ 1137 ICC_PetmodeFb "宠物模式反馈信号";
CM_ SG_ 1137 ICC_SentinelModeFaultSts "哨兵故障状态（摄像头被遮挡）
0x0:Not Warming
0x1:Artificial occlusion摄像头被人为遮挡
0x2 :Rain and snow cover摄像头被雨雪遮挡";
CM_ SG_ 1137 ICC_SentinelModeWorkingSts "哨兵工作状态
0x0: NoActive，哨兵模式未进入或未激活
0x1: Active，哨兵模式已进入或激活
0x2: LowSOC 动力电池 电量低
0x3:HVNotReady，高压系统未上电
0x4: HVFault，高压系统故障
0x5: MirrorUnFold，后视镜未展开
0x6: CameraFault，摄像头故障
0x7:LowBatVolt，蓄电池电压低";
CM_ SG_ 1137 ICC_SentinelModeSwitchSts "哨兵开关状态";
CM_ SG_ 1137 ICC_PetModeWarn "宠物模式异常关闭
0x0:Not Active
0x1:高压电池电量低
0x2:空调异常
0x3:高压异常
0x4:低压电池电量低
0x5:高压电池电量低于15%
0x6:高压电池电量低于12%
0x7:时间过长预警";
CM_ SG_ 1137 ICC_SentinelModeExitReason "哨兵模式异常退出原因
0x0: Normal正常
0x1:LowSOC动力电池电量低
0x2:HVNotReady高压系统未上电
0x3:HVFault高压系统故障
0x4:MirrorUnFold后视镜未展开
0x5:CameraFault，摄像头故障
0x6:LowBatVolt蓄电池电压低";
CM_ SG_ 1137 ICC_SentinelModeAlarmSts "哨兵模式报警状态
0x1: Level 1待命
0x2: Level 2警惕
0x3: Level 3警报";
CM_ SG_ 1137 ICC_TBOXPetmodeReq "ICC发给TBOX宠物模式激活请求
0x1:ON 激活
0x2:OFF 退出";
CM_ SG_ 1137 ICC_PetModeWarn_2 "宠物模式异常关闭
0x0:Not Active
0x1:高压电池电量低
0x2:空调异常
0x3:高压异常
0x4:低压电池电量低
0x5:高压电池电量低于15%
0x6:高压电池电量低于12%
0x7:时间过长预警
0x8:车辆充电中
0x9:车辆未设防
0xA:车辆档位为非P档";
CM_ SG_ 1137 ICC_GPSSailingSpeed_471h "航行速度";
CM_ SG_ 1137 ICM_FuelLevel "燃油量";
CM_ SG_ 1137 ICM_AverageVehicleSpeed "平均车速 (仪表计算)";
CM_ SG_ 1137 ICM_DistenceToEmpty_Km "燃油续航里程";
CM_ SG_ 1137 ICC_ElectronicFenceStsFed_471h "电子围栏开启状态";
CM_ SG_ 1137 ICM_Maintenance_tips "保养提示（仪表计算，可能上传到平台）";
CM_ SG_ 1137 ICM_FuelLevelFailSts "燃油故障";
CM_ SG_ 1137 ICM_SumTrip "小计里程";
CM_ SG_ 1137 ICC_ChgSOCPrioritySet_471h "充电优先级设置
0x0:Not Active
0x1:充电时长优先/充满优先（交流预约充电时）
0x2:SOC设置优先；";
CM_ SG_ 1140 STAT_AMPMediaDuck "Media Duck request to amplifier/发送媒体降音反馈给主机";
CM_ SG_ 1140 STAT_AMPSpeedVolume "Amplifier vehicle speed volume compensation status
反馈-随速补偿等级设定";
CM_ SG_ 1140 STAT_AMPMute "Amplifier audio mute or not status
反馈-媒体音量开关";
CM_ SG_ 1140 STAT_AMPRestoreDefaults "Amplifier audio restore defaults status/恢复默认音频参数设置状态";
CM_ SG_ 1140 STAT_AMPAlarmVolume "Amplifier instrument panel cluster alarm volume status/警报音量值状态";
CM_ SG_ 1140 STAT_Headrest_Mode "Headrest mode status/头枕模式状态";
CM_ SG_ 1140 STAT_AMPSoundEffectMegaBass "Amplifier sound effect megabass feedback/重低音设定值反馈";
CM_ SG_ 1140 STAT_AMPSoundEffectMidBass "Amplifier sound effect midbass feedback/中低音设定值反馈";
CM_ SG_ 1140 STAT_AMPSoundEffectMidTreble "Amplifier sound effect midtreble feedback/中高音设定值反馈";
CM_ SG_ 1140 STAT_VirtualSbwfrOnOff "Amplifier sound effect midtreble feedback/虚拟现场设定状态";
CM_ SG_ 1140 STAT_SurndFnOnOff "Surround_On_Off_Request feedback/3D环绕设定状态";
CM_ SG_ 1140 STAT_AMPBackgroundVolume "Amplifier background media volume status/背景音（迎宾音）音量值状态";
CM_ SG_ 1140 STAT_AMPSoundBypass "Amplifier sound bypass status/第三方APP打开时，外置功放做音效bypass处理状态";
CM_ SG_ 1140 STAT_AMPPwrRdySts "Amplifier Power Ready Status with A2B/A2B交互成功并支持出声后，反馈Ready";
CM_ SG_ 1141 APADispSts_475h "ApaDisplayStatus
APA控制器投屏显示状态";
CM_ SG_ 1141 APA_FuncRecommend_475h "后台推荐泊车功能请求";
CM_ SG_ 1141 APAPrkgChimeVoice_475h "ApaParkingChimeVoice
泊车chime音播报";
CM_ SG_ 1141 AvmWinDisp_475h "AvmDisplayWindow
AVM浮窗显示";
CM_ SG_ 1141 ApaRpaSts_475h "ApaSystemStatus
APA状态机";
CM_ SG_ 1141 AVMFaultStatusCameraFront_475h "ApaSystemStatus
AVM前环视摄像头故障";
CM_ SG_ 1141 AVMFaultStatusCameraLeft_475h "ApaSystemStatus
AVM左环视摄像头故障";
CM_ SG_ 1141 AVMFaultStatusCameraRear_475h "ApaSystemStatus
AVM后环视摄像头故障";
CM_ SG_ 1141 AVMFaultStatusCameraRight_475h "ApaSystemStatus
AVM右环视摄像头故障";
CM_ SG_ 1141 APA_ParkingVoiceRemind_475h "泊车语音播报";
CM_ SG_ 1141 MRASts_475h "MRASystemStatus
MRA状态机";
CM_ SG_ 1142 HCU_4_G_AvgFuCns "Avg Fuel Consumption
近50km平均百公里油耗 L/100km";
CM_ SG_ 1142 HCU_4_G_AvgEnergyCns "Avg Energy Consumption
近50km平均百公里能耗 L/100km";
CM_ SG_ 1142 HCU_4_G_SumEgyCns "Sum Energy Consumption
自清零后累计百公里能耗 L/100km";
CM_ SG_ 1143 OBC_CC_ConnectSts "CC connect states";
CM_ SG_ 1143 CDU_MILSts "CDU请求点亮MIL灯
OBD方案增加
0x1表示点亮MIL灯";
CM_ SG_ 1143 OBC_InnerDischgReq "Internal discharge request";
CM_ SG_ 1144 ICC_HvBattKeepWarmSet "中控插枪保温开关";
CM_ SG_ 1144 ICC_CarSickRelfModeReq "晕车舒缓模式
触发一次快发三帧有效，之后返回0x0:Not Active";
CM_ SG_ 1144 ICC_EnergyRegSet "能量回收强度调节设置
0x0:Not active";
CM_ SG_ 1144 ICC_HvBattKeepWarmActiveReq "插枪保温开始请求";
CM_ BO_ 1147 "捷途新增按下触摸到抬起一次，信号有效的时候连发3帧，周期间隔100ms，后发No_Request周期500ms等下一次有效信号再发三帧信息（间隔100ms）后发No_Request_或者Invalid，周期500ms";
CM_ SG_ 1147 CCP_1_FrontAutoACSwitchReq "前排自动功能";
CM_ SG_ 1147 CCP_1_FLTempSwitchReq "前排左侧温度调节";
CM_ SG_ 1147 FLCCP_MainSetHeatReq "主驾座椅加热";
CM_ SG_ 1147 CCP_1_FrontOFFSwitchReq "前排空调关闭";
CM_ SG_ 1147 CCP_1_FBlowSpdCtrlSwitchReq "前排风速";
CM_ SG_ 1147 CCP_1_ACFastCool "一键制冷请求";
CM_ SG_ 1147 FLCCP_MainSetVentilationReq "主驾座椅通风";
CM_ SG_ 1148 TBOX_BkChrgStartTimeDay "预约充电开始时间设置-日";
CM_ SG_ 1148 TBOX_BkChrgStartTimeeHour "预约充电开始时间设置-时";
CM_ SG_ 1148 TBOX_GPSSwitchSts "GPS定位开关设置";
CM_ SG_ 1148 TBOX_BkChrgStartTimeMin "预约充电开始时间设置-分";
CM_ SG_ 1148 TBOX_BkChrgStartTimeMonth "预约充电开始时间设置-月";
CM_ SG_ 1148 TBOX_BkChrgStartTimeYear "预约充电开始时间设置-年";
CM_ SG_ 1148 TBOX_BkChrgDuration "远程预约充电时长设置";
CM_ SG_ 1148 TBOX_BkChrgCycleType "远程预约充电周期循环方式";
CM_ SG_ 1148 TBOX_BkChrgCycleThur "预约充电周期循环_每周四循环";
CM_ SG_ 1148 TBOX_BkChrgCycleWen "预约充电周期循环_每周三循环";
CM_ SG_ 1148 TBOX_BkChrgCycleTues "预约充电周期循环_每周二循环";
CM_ SG_ 1148 TBOX_BkChrgCycleMon "预约充电周期循环_每周一循环";
CM_ SG_ 1148 TBOX_BkChrgCycleSun "预约充电周期循环_每周日循环";
CM_ SG_ 1148 TBOX_BkChrgCycleSat "预约充电周期循环_每周六循环";
CM_ SG_ 1148 TBOX_BkChrgCycleFri "预约充电周期循环_每周五循环";
CM_ SG_ 1148 TBOX_KeepWarmStrt "插枪保温开始时间设置-日";
CM_ SG_ 1148 TBOX_KeepWarmStrtHour "插枪保温开始时间设置-时";
CM_ SG_ 1148 TBOX_KeepWarmStrtMin "插枪保温开始时间设置-分";
CM_ SG_ 1148 TimeToStartSentinelDayFed_47Ch "哨兵模式预约开始时间反馈(日)";
CM_ SG_ 1148 TimeToStartSentinelHourFed_47Ch "哨兵模式预约开始时间反馈(小时)";
CM_ SG_ 1148 TimeToStartSentinelMinutFed_47Ch "哨兵模式预约开始时间反馈(分钟)";
CM_ SG_ 1148 TimeToStopSentinelHourFed_47Ch "哨兵模式预约结束时间反馈(小时)";
CM_ SG_ 1148 TimeToStopSentinelMinutFed_47Ch "哨兵模式预约结束时间反馈（分钟）";
CM_ SG_ 1148 ReservationSentinelSts_Fed_47Ch "哨兵模式预约反馈
0x1:预约
0x2:取消预约";
CM_ BO_ 1150 "PPMID收";
CM_ SG_ 1150 ICC_BD_11_CRC "Profile1A:E2E CRC (SAE J1850 CRC-8) for 8 Bytes
DataID:0x009E";
CM_ SG_ 1150 ICC_BD_11_RollgCntr "Profile1A:E2E Rolling message counter(the maximum value of Alive counter is 14)";
CM_ SG_ 1150 ICC_CPDDelaySwitchSet "CIR功能延迟开关设置状态";
CM_ SG_ 1150 ICC_PPMIDBSRBPASet "Belt slack reduction(BSR) / 织带间隙消除
Belt parking assist(BPA) / 织带辅助回收";
CM_ SG_ 1150 ICC_PPMIDHwSet "Haptic Warning(HWA) /  震动触觉提醒";
CM_ SG_ 1150 ICC_FLDoorButton "大屏主驾门打开关闭，按钮按下是0x2 Active,不按是0x1 Inactive";
CM_ SG_ 1150 ICC_FRDoorButton "大屏副驾门打开关闭，按钮按下是0x2 Active,不按是0x1 Inactive";
CM_ SG_ 1150 ICC_DriveDrosinessLevel "0x0: not available;驾驶员在位检测输出“不在位”的时候触发
0x1: unknown;驾驶员不疲劳的默认状态
0x2: not fatigue;驾驶员不疲劳
0x3: lightly fatigue轻度疲劳,;
0x4: moderate fatigue中度疲劳;
0x5: severe fatigue重度疲劳;
0x6~0x7: Reserved";
CM_ SG_ 1150 ICC_RRDoorButton "大屏右后门打开关闭 按钮按下是0x2 Active,不按是0x1 Inactive";
CM_ SG_ 1150 ICC_RLDoorButton "大屏左后门打开关闭，按钮按下是0x2 Active,不按是0x1 Inactive";
CM_ SG_ 1150 ICC_CloseAllDoors "大屏一键电动门全关，按钮按下是0x2 Active,不按是0x1 Inactive";
CM_ SG_ 1150 ICC_DoorRemoteKeyControlEnable "长按钥匙远程控制使能";
CM_ SG_ 1150 ICC_SetOpenAngle "大屏设置侧门开度";
CM_ SG_ 1150 ICC_CPDSwitchSet "CIR功能开关设置状态";
CM_ SG_ 1150 ICC_FrontDoorPowerMode "前门手动模式、电动模式、半自动模式";
CM_ SG_ 1150 ICC_RearDoorPowerMode "后门手动模式、电动模式、半自动模式";
CM_ SG_ 1150 ICC_PedalCloseDriverDoorEnable "刹车踏板控制驾驶门 功能使能";
CM_ SG_ 1150 RR_Door_RearScreen_Control "The rear screen controls the door function to open/close/stop the rear door后排屏幕控制车门";
CM_ SG_ 1150 ICC_RearDoorVoiceControlEnable "后门语音控制使能";
CM_ SG_ 1150 ICC_FLVoiceControl "左前门语音控制";
CM_ SG_ 1150 ICC_FRVoiceControl "右前门语音控制";
CM_ SG_ 1150 ICC_RRVoiceControl "右后门语音控制";
CM_ SG_ 1150 ICC_RLVoiceControl "左后门语音控制";
CM_ SG_ 1150 RL_Door_RearScreen_Control "The rear screen controls the door function to open/close/stop the rear door后排屏幕控制车门";
CM_ BO_ 1151 "虽然名称奇怪，确是从IC报文路由";
CM_ BO_ 1152 "触发一次发送三帧有效+三帧Not Active";
CM_ SG_ 1152 TBOX_PetmodeSetTemperature "宠物模式远程空调温度设置";
CM_ SG_ 1155 ASU_3_horizontalSts "露营找平开关状态
0x1:ON开关开启
0x2:OFF开关关闭";
CM_ SG_ 1155 ASU_3_horizontalmodeFb "露营找平模式反馈
0x0:Not Active 条件不满足，未激活
0x1:Working  找平中
0x2:Complete 找平完成
0x3:Abort       找平中断
0x4:Failure      找平失败
0x5:Reserved  预留
0x6:Reserved   预留
0x7:Reserved   预留";
CM_ SG_ 1157 ICC_DA_15_CRC "Profile1A:E2E CRC (SAE J1850 CRC-8) for 8 Bytes
DataID:0x009D";
CM_ SG_ 1157 ICC_DA_15_RollgCntr "Profile1A:E2E Rolling message counter(the maximum value of Alive counter is 14)";
CM_ SG_ 1157 ICC_DA_15_Resd "Profile1A:E2E Reserved";
CM_ SG_ 1157 ICC_DA_15_BSDLCWSettingSt "BSD/LCA function setting button status";
CM_ SG_ 1157 ICC_DA_15_DOWSettingSt "Door open warning function setting button status";
CM_ SG_ 1157 ICC_DA_15_RCWSettingSt "Rear Collision Warning function setting button status";
CM_ SG_ 1157 ICC_DA_15_RCTARCTBWarnType "RCTA/RCTB function setting button status";
CM_ SG_ 1157 ICC_DA_15_FCTAFCTBWarnType "FCTA/FCTB function setting button status";
CM_ SG_ 1157 ICC_DA_15_FrontPDCMuteSet "前PDC、侧PDC声音开关";
CM_ SG_ 1157 ICC_DA_15_FKPMuteSet "侧PDC声音开关";
CM_ SG_ 1157 Driver_AbnormalBehavior "Driver Abnormal Behavior detection result
非正常行为";
CM_ SG_ 1157 Dms_Status "DMS(Driver Monitor System) Status
驾驶员监测状态";
CM_ SG_ 1157 Driver_EyeOnRoad "indicate Driver Eyes On Road status";
CM_ SG_ 1157 ICC_IHCfunctionSw "智能远光辅助开关";
CM_ SG_ 1157 Dms_DriverPresence "indicate Driver Presence detection status
未检测到驾驶员";
CM_ SG_ 1157 Driver_GazeRegion "Driver Gaze Region
凝视的区域";
BA_DEF_ SG_  "GenSigASIL" ENUM  "QM","A","B","C","D","vector_leerstring";
BA_DEF_ SG_  "ASIL" ENUM  "QM","A","B","C","D";
BA_DEF_ SG_  "E2EDataLength" INT 0 65535;
BA_DEF_ SG_  "GenSigInactiveValue" HEX 0 80000000;
BA_DEF_ SG_  "GenSigInvalidValue" HEX 0 281474976710655;
BA_DEF_ SG_  "GenSigStartValue" HEX 0 80000000;
BA_DEF_ SG_  "GenSigSendType" ENUM  "Cyclic","OnWrite","OnWriteWithRepetition","OnChange","OnChangeWithRepetition","IfActive","IfActiveWithRepetition","NoSigSendType";
BA_DEF_ BO_  "CANFD_BRS" ENUM  "0","1";
BA_DEF_ BO_  "DiagUudtResponse" ENUM  "True","False";
BA_DEF_ BO_  "GenMsgCycleTime" INT 0 65535;
BA_DEF_ BO_  "GenMsgCycleTimeFast" INT 0 65535;
BA_DEF_ BO_  "GenMsgDelayTime" INT 0 65535;
BA_DEF_ BO_  "GenMsgILSupport" ENUM  "No","Yes";
BA_DEF_ BO_  "GenMsgNrOfRepetition" INT 0 255;
BA_DEF_ BO_  "GenMsgSendType" ENUM  "Cyclic","Event","IfActive","CE","CA","NoMsgSendType";
BA_DEF_ BO_  "NmAsrMessage" ENUM  "No","Yes";
BA_DEF_ BO_  "NmMessage" ENUM  "No","Yes";
BA_DEF_ BO_  "SCP_AuthInfoTxLength" INT 9 512;
BA_DEF_ BO_  "SCP_FreshnessValueLength" INT 0 512;
BA_DEF_ BO_  "SCP_FreshnessValueTxLength" INT 0 512;
BA_DEF_ BO_  "VFrameFormat" ENUM  "StandardCAN","ExtendedCAN","reserved","J1939PG","reserved","reserved","reserved","reserved","reserved","reserved","reserved","reserved","reserved","reserved","StandardCAN_FD","ExtendedCAN_FD";
BA_DEF_DEF_  "GenSigASIL" "QM";
BA_DEF_DEF_  "ASIL" "QM";
BA_DEF_DEF_  "E2EDataLength" 64;
BA_DEF_DEF_  "GenSigInactiveValue" 0;
BA_DEF_DEF_  "GenSigInvalidValue" 0;
BA_DEF_DEF_  "GenSigStartValue" 0;
BA_DEF_DEF_  "GenSigSendType" "NoSigSendType";
BA_DEF_DEF_  "CANFD_BRS" "1";
BA_DEF_DEF_  "DiagUudtResponse" "True";
BA_DEF_DEF_  "GenMsgCycleTime" 0;
BA_DEF_DEF_  "GenMsgCycleTimeFast" 0;
BA_DEF_DEF_  "GenMsgDelayTime" 0;
BA_DEF_DEF_  "GenMsgILSupport" "Yes";
BA_DEF_DEF_  "GenMsgNrOfRepetition" 0;
BA_DEF_DEF_  "GenMsgSendType" "Cyclic";
BA_DEF_DEF_  "NmAsrMessage" "No";
BA_DEF_DEF_  "NmMessage" "No";
BA_DEF_DEF_  "SCP_AuthInfoTxLength" 28;
BA_DEF_DEF_  "SCP_FreshnessValueLength" 48;
BA_DEF_DEF_  "SCP_FreshnessValueTxLength" 4;
BA_DEF_DEF_  "VFrameFormat" "J1939PG";
BA_ "GenMsgNrOfRepetition" BO_ 1028 3;
BA_ "GenMsgCycleTime" BO_ 1028 100;
BA_ "GenMsgDelayTime" BO_ 1028 5;
BA_ "GenMsgCycleTimeFast" BO_ 1028 50;
BA_ "GenMsgSendType" BO_ 1028 3;
BA_ "VFrameFormat" BO_ 1028 14;
BA_ "GenMsgCycleTime" BO_ 1030 100;
BA_ "VFrameFormat" BO_ 1030 14;
BA_ "GenMsgCycleTime" BO_ 1034 100;
BA_ "VFrameFormat" BO_ 1034 14;
BA_ "GenMsgCycleTime" BO_ 1035 100;
BA_ "VFrameFormat" BO_ 1035 14;
BA_ "GenMsgCycleTime" BO_ 1037 100;
BA_ "VFrameFormat" BO_ 1037 14;
BA_ "GenMsgCycleTime" BO_ 1041 100;
BA_ "VFrameFormat" BO_ 1041 14;
BA_ "GenMsgCycleTime" BO_ 1042 100;
BA_ "VFrameFormat" BO_ 1042 14;
BA_ "GenMsgCycleTime" BO_ 1043 100;
BA_ "VFrameFormat" BO_ 1043 14;
BA_ "GenMsgCycleTime" BO_ 1044 100;
BA_ "VFrameFormat" BO_ 1044 14;
BA_ "GenMsgCycleTime" BO_ 1046 100;
BA_ "VFrameFormat" BO_ 1046 14;
BA_ "GenMsgNrOfRepetition" BO_ 1056 2;
BA_ "GenMsgCycleTime" BO_ 1056 100;
BA_ "GenMsgDelayTime" BO_ 1056 5;
BA_ "GenMsgCycleTimeFast" BO_ 1056 100;
BA_ "VFrameFormat" BO_ 1056 14;
BA_ "GenMsgCycleTime" BO_ 1057 100;
BA_ "VFrameFormat" BO_ 1057 14;
BA_ "GenMsgNrOfRepetition" BO_ 1059 2;
BA_ "GenMsgCycleTime" BO_ 1059 100;
BA_ "GenMsgDelayTime" BO_ 1059 5;
BA_ "GenMsgCycleTimeFast" BO_ 1059 100;
BA_ "VFrameFormat" BO_ 1059 14;
BA_ "GenMsgCycleTime" BO_ 1060 100;
BA_ "VFrameFormat" BO_ 1060 14;
BA_ "GenMsgCycleTime" BO_ 1061 100;
BA_ "VFrameFormat" BO_ 1061 14;
BA_ "GenMsgNrOfRepetition" BO_ 1063 3;
BA_ "GenMsgDelayTime" BO_ 1063 5;
BA_ "GenMsgCycleTimeFast" BO_ 1063 100;
BA_ "GenMsgSendType" BO_ 1063 1;
BA_ "VFrameFormat" BO_ 1063 14;
BA_ "GenMsgCycleTime" BO_ 1065 100;
BA_ "VFrameFormat" BO_ 1065 14;
BA_ "GenMsgCycleTime" BO_ 1069 100;
BA_ "VFrameFormat" BO_ 1069 14;
BA_ "GenMsgCycleTime" BO_ 1070 100;
BA_ "VFrameFormat" BO_ 1070 14;
BA_ "GenMsgCycleTime" BO_ 1071 100;
BA_ "VFrameFormat" BO_ 1071 14;
BA_ "GenMsgCycleTime" BO_ 1072 100;
BA_ "VFrameFormat" BO_ 1072 14;
BA_ "GenMsgCycleTime" BO_ 1073 100;
BA_ "VFrameFormat" BO_ 1073 14;
BA_ "GenMsgNrOfRepetition" BO_ 1075 3;
BA_ "GenMsgDelayTime" BO_ 1075 5;
BA_ "GenMsgCycleTimeFast" BO_ 1075 100;
BA_ "GenMsgSendType" BO_ 1075 1;
BA_ "VFrameFormat" BO_ 1075 14;
BA_ "GenMsgCycleTime" BO_ 1078 100;
BA_ "VFrameFormat" BO_ 1078 14;
BA_ "GenMsgCycleTime" BO_ 1079 100;
BA_ "VFrameFormat" BO_ 1079 14;
BA_ "GenMsgCycleTime" BO_ 1087 100;
BA_ "VFrameFormat" BO_ 1087 14;
BA_ "GenMsgCycleTime" BO_ 1095 100;
BA_ "VFrameFormat" BO_ 1095 14;
BA_ "GenMsgCycleTime" BO_ 1096 100;
BA_ "VFrameFormat" BO_ 1096 14;
BA_ "GenMsgCycleTime" BO_ 1099 100;
BA_ "VFrameFormat" BO_ 1099 14;
BA_ "GenMsgNrOfRepetition" BO_ 1100 2;
BA_ "GenMsgDelayTime" BO_ 1100 5;
BA_ "GenMsgCycleTimeFast" BO_ 1100 100;
BA_ "GenMsgSendType" BO_ 1100 1;
BA_ "VFrameFormat" BO_ 1100 14;
BA_ "GenMsgCycleTime" BO_ 1104 100;
BA_ "VFrameFormat" BO_ 1104 14;
BA_ "GenMsgNrOfRepetition" BO_ 1105 2;
BA_ "GenMsgCycleTime" BO_ 1105 100;
BA_ "GenMsgDelayTime" BO_ 1105 5;
BA_ "GenMsgCycleTimeFast" BO_ 1105 100;
BA_ "VFrameFormat" BO_ 1105 14;
BA_ "GenMsgCycleTime" BO_ 1107 100;
BA_ "VFrameFormat" BO_ 1107 14;
BA_ "GenMsgCycleTime" BO_ 1109 100;
BA_ "VFrameFormat" BO_ 1109 14;
BA_ "GenMsgSendType" BO_ 1110 1;
BA_ "VFrameFormat" BO_ 1110 14;
BA_ "GenMsgNrOfRepetition" BO_ 1112 2;
BA_ "GenMsgCycleTime" BO_ 1112 100;
BA_ "GenMsgDelayTime" BO_ 1112 5;
BA_ "GenMsgCycleTimeFast" BO_ 1112 100;
BA_ "VFrameFormat" BO_ 1112 14;
BA_ "GenMsgSendType" BO_ 1116 1;
BA_ "VFrameFormat" BO_ 1116 14;
BA_ "GenMsgNrOfRepetition" BO_ 1119 2;
BA_ "GenMsgDelayTime" BO_ 1119 5;
BA_ "GenMsgCycleTimeFast" BO_ 1119 100;
BA_ "GenMsgSendType" BO_ 1119 1;
BA_ "VFrameFormat" BO_ 1119 14;
BA_ "GenMsgCycleTime" BO_ 1120 100;
BA_ "VFrameFormat" BO_ 1120 14;
BA_ "GenMsgCycleTime" BO_ 1121 100;
BA_ "VFrameFormat" BO_ 1121 14;
BA_ "GenMsgCycleTime" BO_ 1123 100;
BA_ "VFrameFormat" BO_ 1123 14;
BA_ "GenMsgCycleTime" BO_ 1127 100;
BA_ "VFrameFormat" BO_ 1127 14;
BA_ "GenMsgCycleTime" BO_ 1128 100;
BA_ "VFrameFormat" BO_ 1128 14;
BA_ "GenMsgCycleTime" BO_ 1129 100;
BA_ "VFrameFormat" BO_ 1129 14;
BA_ "GenMsgCycleTime" BO_ 1130 100;
BA_ "VFrameFormat" BO_ 1130 14;
BA_ "GenMsgCycleTime" BO_ 1131 100;
BA_ "VFrameFormat" BO_ 1131 14;
BA_ "GenMsgNrOfRepetition" BO_ 1136 96;
BA_ "GenMsgDelayTime" BO_ 1136 5;
BA_ "GenMsgCycleTimeFast" BO_ 1136 100;
BA_ "GenMsgSendType" BO_ 1136 1;
BA_ "VFrameFormat" BO_ 1136 14;
BA_ "GenMsgNrOfRepetition" BO_ 1137 2;
BA_ "GenMsgCycleTime" BO_ 1137 100;
BA_ "GenMsgDelayTime" BO_ 1137 5;
BA_ "GenMsgCycleTimeFast" BO_ 1137 100;
BA_ "VFrameFormat" BO_ 1137 14;
BA_ "GenMsgCycleTime" BO_ 1140 100;
BA_ "VFrameFormat" BO_ 1140 14;
BA_ "GenMsgCycleTime" BO_ 1141 100;
BA_ "VFrameFormat" BO_ 1141 14;
BA_ "GenMsgCycleTime" BO_ 1142 100;
BA_ "VFrameFormat" BO_ 1142 14;
BA_ "GenMsgCycleTime" BO_ 1143 100;
BA_ "VFrameFormat" BO_ 1143 14;
BA_ "GenMsgNrOfRepetition" BO_ 1144 2;
BA_ "GenMsgCycleTime" BO_ 1144 100;
BA_ "GenMsgDelayTime" BO_ 1144 5;
BA_ "GenMsgCycleTimeFast" BO_ 1144 100;
BA_ "VFrameFormat" BO_ 1144 14;
BA_ "GenMsgNrOfRepetition" BO_ 1147 3;
BA_ "GenMsgCycleTime" BO_ 1147 100;
BA_ "GenMsgDelayTime" BO_ 1147 5;
BA_ "GenMsgCycleTimeFast" BO_ 1147 20;
BA_ "GenMsgSendType" BO_ 1147 3;
BA_ "VFrameFormat" BO_ 1147 14;
BA_ "GenMsgCycleTime" BO_ 1148 100;
BA_ "VFrameFormat" BO_ 1148 14;
BA_ "GenMsgSendType" BO_ 1149 1;
BA_ "VFrameFormat" BO_ 1149 14;
BA_ "GenMsgNrOfRepetition" BO_ 1150 2;
BA_ "GenMsgCycleTime" BO_ 1150 100;
BA_ "GenMsgDelayTime" BO_ 1150 5;
BA_ "GenMsgCycleTimeFast" BO_ 1150 50;
BA_ "VFrameFormat" BO_ 1150 14;
BA_ "GenMsgSendType" BO_ 1151 1;
BA_ "VFrameFormat" BO_ 1151 14;
BA_ "GenMsgNrOfRepetition" BO_ 1152 3;
BA_ "GenMsgDelayTime" BO_ 1152 5;
BA_ "GenMsgCycleTimeFast" BO_ 1152 100;
BA_ "GenMsgSendType" BO_ 1152 1;
BA_ "VFrameFormat" BO_ 1152 14;
BA_ "GenMsgCycleTime" BO_ 1155 100;
BA_ "VFrameFormat" BO_ 1155 14;
BA_ "GenMsgNrOfRepetition" BO_ 1157 2;
BA_ "GenMsgCycleTime" BO_ 1157 100;
BA_ "GenMsgDelayTime" BO_ 1157 5;
BA_ "GenMsgCycleTimeFast" BO_ 1157 50;
BA_ "VFrameFormat" BO_ 1157 14;
BA_ "GenSigSendType" SG_ 1028 PEPS_WelcomeON 4;
BA_ "GenSigSendType" SG_ 1028 PEPS_VehicleSearchReq 4;
BA_ "GenSigSendType" SG_ 1028 PEPS_SATOReminder 4;
BA_ "GenSigSendType" SG_ 1028 PEPS_PLGUnlockReq 4;
BA_ "GenSigSendType" SG_ 1028 PEPS_RKETrunkSts 0;
BA_ "GenSigSendType" SG_ 1028 PEPS_SSBInhibitCWCSts 0;
BA_ "GenSigSendType" SG_ 1028 PEPS_WirelessChargingCtrSts 0;
BA_ "GenSigSendType" SG_ 1028 PEPS_EmgyShutdown 0;
BA_ "GenSigSendType" SG_ 1028 PEPS_SSBInputFailure 0;
BA_ "GenSigSendType" SG_ 1028 PEPS_SmartSystemWarning1_1 0;
BA_ "GenSigSendType" SG_ 1028 PEPS_SmartSystemWarning2_2 0;
BA_ "GenSigSendType" SG_ 1028 PEPS_SmartSystemWarning3_1 0;
BA_ "GenSigSendType" SG_ 1028 PEPS_SmartSystemWarning3_2 0;
BA_ "GenSigSendType" SG_ 1028 PEPS_SmartSystemWarning4_2 0;
BA_ "GenSigSendType" SG_ 1028 PEPS_SmartSystemWarning4_3 0;
BA_ "GenSigSendType" SG_ 1028 PEPS_SystemWarning 0;
BA_ "GenSigSendType" SG_ 1028 PEPS_BLTKeyPESts 0;
BA_ "ASIL" SG_ 1030 RearViewFoldSts 2;
BA_ "GenSigSendType" SG_ 1030 RearViewFoldSts 0;
BA_ "GenSigSendType" SG_ 1030 FLZCU_AlrmSts 0;
BA_ "GenSigSendType" SG_ 1030 FLZCU_SteeringMode 0;
BA_ "GenSigSendType" SG_ 1030 FLZCU_OBDDiagOccupy 0;
BA_ "GenSigInvalidValue" SG_ 1034 HCU_EmPwr 255;
BA_ "GenSigStartValue" SG_ 1034 HCU_EmPwr 128;
BA_ "GenSigSendType" SG_ 1034 HCU_EmPwr 0;
BA_ "ASIL" SG_ 1034 HCU_PowerModeFed 1;
BA_ "GenSigSendType" SG_ 1034 HCU_PowerModeFed 0;
BA_ "GenSigSendType" SG_ 1034 HCU_PowertrainFault 0;
BA_ "GenSigSendType" SG_ 1034 HCU_PowerModeChangeFail 0;
BA_ "GenSigSendType" SG_ 1034 HCU_ChargingSts 0;
BA_ "GenSigSendType" SG_ 1035 VCC_1_OTASts 0;
BA_ "ASIL" SG_ 1035 VCC_1_DriveMode 2;
BA_ "GenSigSendType" SG_ 1035 VCC_1_DriveMode 0;
BA_ "GenSigSendType" SG_ 1037 ADS_FCTAWarn_Right 0;
BA_ "GenSigSendType" SG_ 1037 ADS_FCTAWarn_Left 0;
BA_ "GenSigSendType" SG_ 1037 ADS_RCTAWarn_Rigth 0;
BA_ "GenSigSendType" SG_ 1037 ADS_RCTAWarn_Left 0;
BA_ "GenSigSendType" SG_ 1037 ADAS_enum_AESSts_40Dh 0;
BA_ "GenSigSendType" SG_ 1037 ADAS_enum_AudibleBeepRate_40Dh 0;
BA_ "GenSigSendType" SG_ 1037 ADAS_enum_FCTASettingStsFb_40Dh 0;
BA_ "GenSigSendType" SG_ 1037 ADAS_enum_RadarWorkSts_40Dh 0;
BA_ "GenSigSendType" SG_ 1037 ADAS_enum_PasSwitch_40Dh 0;
BA_ "GenSigSendType" SG_ 1037 ADAS_enum_MEBSts_40Dh 0;
BA_ "GenSigSendType" SG_ 1037 ADAS_enum_MAASts_40Dh 0;
BA_ "GenSigSendType" SG_ 1037 IHU_11_VoiceplayModeSwtSet_40Dh 0;
BA_ "GenSigSendType" SG_ 1037 IHU_11_LightingBlueSwtSet_40Dh 0;
BA_ "GenSigSendType" SG_ 1037 enum_CECULVDSOutputStatus_40Dh 0;
BA_ "GenSigSendType" SG_ 1041 ADS_RadarWarning0Distance_411h 0;
BA_ "GenSigSendType" SG_ 1041 ADS_RadarWarning1Distance_411h 0;
BA_ "GenSigSendType" SG_ 1041 ADS_RadarWarning2Distance_411h 0;
BA_ "GenSigSendType" SG_ 1041 ADS_RadarWarning3Distance_411h 0;
BA_ "GenSigSendType" SG_ 1041 ADS_RadarWarning4Distance_411h 0;
BA_ "GenSigSendType" SG_ 1041 ADS_RadarWarning5Distance_411h 0;
BA_ "GenSigSendType" SG_ 1041 ADS_RadarWarning6Distance_411h 0;
BA_ "GenSigSendType" SG_ 1041 ADS_RadarWarning7Distance_411h 0;
BA_ "GenSigSendType" SG_ 1041 ADS_RadarWarning8Distance_411h 0;
BA_ "GenSigSendType" SG_ 1041 ADS_RadarWarning9Distance_411h 0;
BA_ "GenSigSendType" SG_ 1041 ADS_RadarWarning10Distance_411h 0;
BA_ "GenSigSendType" SG_ 1041 ADS_RadarWarning11Distance_411h 0;
BA_ "GenSigSendType" SG_ 1041 ADS_RadarWarning12Distance_411h 0;
BA_ "GenSigSendType" SG_ 1041 ADS_RadarWarning13Distance_411h 0;
BA_ "GenSigSendType" SG_ 1041 ADS_RadarWarning14Distance_411h 0;
BA_ "GenSigSendType" SG_ 1041 ADS_RadarWarning15Distance_411h 0;
BA_ "GenSigSendType" SG_ 1041 ADS_RadarWarning2AcLvl_411h 0;
BA_ "GenSigSendType" SG_ 1041 ADS_RadarWarning1AcLvl_411h 0;
BA_ "GenSigSendType" SG_ 1041 ADS_RadarWarning0AcLvl_411h 0;
BA_ "GenSigSendType" SG_ 1041 ADS_RadarWarning4AcLvl_411h 0;
BA_ "GenSigSendType" SG_ 1041 ADS_RadarWarning3AcLvl_411h 0;
BA_ "GenSigSendType" SG_ 1041 ADS_RadarWarning7AcLvl_411h 0;
BA_ "GenSigSendType" SG_ 1041 ADS_RadarWarning6AcLvl_411h 0;
BA_ "GenSigSendType" SG_ 1041 ADS_RadarWarning5AcLvl_411h 0;
BA_ "GenSigSendType" SG_ 1041 ADS_RadarWarning10AcLvl_411h 0;
BA_ "GenSigSendType" SG_ 1041 ADS_RadarWarning9AcLvl_411h 0;
BA_ "GenSigSendType" SG_ 1041 ADS_RadarWarning8AcLvl_411h 0;
BA_ "GenSigSendType" SG_ 1041 ADS_RadarWarning12AcLvl_411h 0;
BA_ "GenSigSendType" SG_ 1041 ADS_RadarWarning11AcLvl_411h 0;
BA_ "GenSigSendType" SG_ 1041 ADS_RadarWarning15AcLvl_411h 0;
BA_ "GenSigSendType" SG_ 1041 ADS_RadarWarning14AcLvl_411h 0;
BA_ "GenSigSendType" SG_ 1041 ADS_RadarWarning13AcLvl_411h 0;
BA_ "GenSigSendType" SG_ 1041 ADC_MdcSentryAlarmMod_411h 0;
BA_ "GenSigSendType" SG_ 1041 ADC_FuncReq_SentryModDetec_411h 0;
BA_ "GenSigSendType" SG_ 1041 ADC_FuncReq_SentryModWarn_411h 0;
BA_ "GenSigSendType" SG_ 1042 ADS_CRC1_412h 0;
BA_ "GenSigSendType" SG_ 1042 ADS_RollgCntr1_412h 0;
BA_ "GenSigSendType" SG_ 1042 ADS_Resd1_412h 0;
BA_ "GenSigSendType" SG_ 1042 ADS_RiFrntDowWarning_412h 0;
BA_ "GenSigSendType" SG_ 1042 ADS_LeFrntDowWarning_412h 0;
BA_ "GenSigSendType" SG_ 1042 ADS_AutoLightSwCtrl_412h 0;
BA_ "ASIL" SG_ 1042 ADS_BrkBeamReq_412h 2;
BA_ "GenSigSendType" SG_ 1042 ADS_BrkBeamReq_412h 0;
BA_ "GenSigSendType" SG_ 1042 ADS_RightMirrWarningCmd_412h 0;
BA_ "GenSigSendType" SG_ 1042 ADS_LeftMirrWarningCmd_412h 0;
BA_ "GenSigSendType" SG_ 1042 ADS_RiReDowWarning_412h 0;
BA_ "GenSigSendType" SG_ 1042 ADS_LeReDowWarning_412h 0;
BA_ "GenSigSendType" SG_ 1042 ADS_WshrReq_412h 0;
BA_ "GenSigSendType" SG_ 1042 ADS_SBeltControl_412h 0;
BA_ "GenSigSendType" SG_ 1042 ADS_DoorLockReq_412h 0;
BA_ "GenSigSendType" SG_ 1042 ADS_ReMirrReq_412h 0;
BA_ "GenSigSendType" SG_ 1042 ADS_LeFmtWinCtrl_412h 0;
BA_ "GenSigSendType" SG_ 1042 ADS_HornReq_412h 0;
BA_ "GenSigSendType" SG_ 1042 ADS_FrtWindshildHeatReq_412h 0;
BA_ "GenSigSendType" SG_ 1042 ADS_SeatShakeControl_412h 0;
BA_ "GenSigSendType" SG_ 1042 ADS_TopWinCtrl_412h 0;
BA_ "GenSigSendType" SG_ 1042 ADS_RiReWinCtrl_412h 0;
BA_ "GenSigSendType" SG_ 1042 ADS_LeReWinCtrl_412h 0;
BA_ "GenSigSendType" SG_ 1042 ADS_RiFmtWinCtrl_412h 0;
BA_ "GenSigInvalidValue" SG_ 1042 ADS_MdcCrtSts_412h 7;
BA_ "GenSigSendType" SG_ 1042 ADS_MdcCrtSts_412h 0;
BA_ "GenSigSendType" SG_ 1042 ADAS_FctSts_412h 0;
BA_ "GenSigSendType" SG_ 1042 ADS_ChargingPortCmd_412h 0;
BA_ "GenSigSendType" SG_ 1042 ADS_FrontWiperReq_412h 0;
BA_ "GenSigSendType" SG_ 1042 ADS_PwrOnOffReq_412h 0;
BA_ "GenSigInvalidValue" SG_ 1042 ADS_FlowReq_412h 15;
BA_ "GenSigSendType" SG_ 1042 ADS_FlowReq_412h 0;
BA_ "GenSigSendType" SG_ 1042 ADS_ThmPostRun_412h 0;
BA_ "GenSigSendType" SG_ 1042 ADS_HVCtrlReq_412h 0;
BA_ "GenSigSendType" SG_ 1042 ADS_HiBeamReq_412h 0;
BA_ "GenSigSendType" SG_ 1042 ADS_HMAStatus_412h 0;
BA_ "GenSigSendType" SG_ 1042 ADS_hmaOnOffSts_412h 0;
BA_ "GenSigInvalidValue" SG_ 1043 EBS_U_BATT 16383;
BA_ "GenSigStartValue" SG_ 1043 EBS_U_BATT 16383;
BA_ "GenSigSendType" SG_ 1043 EBS_U_BATT 0;
BA_ "GenSigSendType" SG_ 1044 HCU_EnergyFlow 0;
BA_ "GenSigInvalidValue" SG_ 1044 HCU_SetSOCFed 255;
BA_ "GenSigSendType" SG_ 1044 HCU_SetSOCFed 0;
BA_ "GenSigSendType" SG_ 1044 HCU_2_G_LowBatteryInfo 0;
BA_ "ASIL" SG_ 1046 LBMS_LoWSocFlt 2;
BA_ "GenSigSendType" SG_ 1046 LBMS_LoWSocFlt 0;
BA_ "ASIL" SG_ 1046 LBMS_EndLifeFlt 2;
BA_ "GenSigSendType" SG_ 1046 LBMS_EndLifeFlt 0;
BA_ "ASIL" SG_ 1046 LBMS_SysFlt 2;
BA_ "GenSigSendType" SG_ 1046 LBMS_SysFlt 0;
BA_ "ASIL" SG_ 1046 LBMS_ThermRunawayFlt 2;
BA_ "GenSigSendType" SG_ 1046 LBMS_ThermRunawayFlt 0;
BA_ "ASIL" SG_ 1046 LBMS_LowPowerRemind 2;
BA_ "GenSigSendType" SG_ 1046 LBMS_LowPowerRemind 0;
BA_ "GenSigSendType" SG_ 1056 ICC_DSBH_HeatReq 0;
BA_ "GenSigStartValue" SG_ 1056 ICC_DSBH_SetTemp 30;
BA_ "GenSigSendType" SG_ 1056 ICC_DSBH_SetTemp 0;
BA_ "GenSigSendType" SG_ 1056 ICC_PSBH_HeatReq 0;
BA_ "GenSigStartValue" SG_ 1056 ICC_PSBH_SetTemp 30;
BA_ "GenSigSendType" SG_ 1056 ICC_PSBH_SetTemp 0;
BA_ "GenSigSendType" SG_ 1057 VCU_shfChk 0;
BA_ "GenSigSendType" SG_ 1057 VCU_TowingMode 0;
BA_ "GenSigInvalidValue" SG_ 1057 VCU_ChgSocSetFed 255;
BA_ "GenSigStartValue" SG_ 1057 VCU_ChgSocSetFed 255;
BA_ "GenSigSendType" SG_ 1057 VCU_ChgSocSetFed 0;
BA_ "GenSigInvalidValue" SG_ 1057 VCU_EngyConsuPer50Km 4095;
BA_ "GenSigSendType" SG_ 1057 VCU_EngyConsuPer50Km 0;
BA_ "GenSigSendType" SG_ 1057 VCU_BookChrgSetFailRes 0;
BA_ "GenSigSendType" SG_ 1057 VCU_BookChrgFailRes 0;
BA_ "GenSigSendType" SG_ 1057 VCU_BookChrgStsFb 0;
BA_ "GenSigSendType" SG_ 1057 HCU_EngineSelfMaintain 0;
BA_ "GenSigSendType" SG_ 1059 DrvSeatHeatLevelCmdvelCmd_423h 2;
BA_ "GenSigSendType" SG_ 1059 ICC_FRSeatHeatLevelCmd 2;
BA_ "GenSigSendType" SG_ 1059 ICC_TrunkSW 2;
BA_ "GenSigInvalidValue" SG_ 1059 ICC_Set_PLGOperateSts 127;
BA_ "GenSigSendType" SG_ 1059 ICC_Set_PLGOperateSts 2;
BA_ "GenSigSendType" SG_ 1059 ICC_RRSeatHeatLevelCmd 2;
BA_ "GenSigSendType" SG_ 1059 DrvSecSeatHeatLevelCmd_423h 2;
BA_ "GenSigSendType" SG_ 1059 ICC_FRSeatVentLevelCmd 2;
BA_ "GenSigSendType" SG_ 1059 DrvSeatVentLevelCmd_423h 2;
BA_ "GenSigSendType" SG_ 1059 ICC_FrontWiperMaintenanceMode 2;
BA_ "GenSigSendType" SG_ 1059 ICC_RRSeatVentLevelCmd 2;
BA_ "GenSigSendType" SG_ 1059 DrvSecSeatVentLevelCmd_423h 2;
BA_ "GenSigSendType" SG_ 1059 PLG_ControlReq_423h 2;
BA_ "GenSigSendType" SG_ 1059 ICC_RearWiperMaintenanceMode 2;
BA_ "ASIL" SG_ 1060 InforDisplay_424h 1;
BA_ "GenSigSendType" SG_ 1060 InforDisplay_424h 0;
BA_ "GenSigSendType" SG_ 1061 DriverSeatMsgStr_LvlSts 0;
BA_ "GenSigSendType" SG_ 1061 DriverSeatMsg_ModeSts 0;
BA_ "GenSigSendType" SG_ 1061 Drv_Seat_ActvBolster_MdSts 0;
BA_ "GenSigSendType" SG_ 1061 Drv_Seat_LBolster_Sts 0;
BA_ "GenSigSendType" SG_ 1061 Drv_Seat_RBolster_Sts 0;
BA_ "GenSigSendType" SG_ 1063 TBOX_PetmodeSwitch 2;
BA_ "GenSigSendType" SG_ 1063 TBOX_SentinelModeSw 2;
BA_ "GenSigSendType" SG_ 1063 TBOX_ElectronicFenceReq_427h 2;
BA_ "GenSigSendType" SG_ 1065 LeftSeatMsgStr_LvlSts 0;
BA_ "GenSigSendType" SG_ 1065 LeftSeatMsg_ModeSts 0;
BA_ "GenSigSendType" SG_ 1069 PassSeatMsgStr_LvlSts 0;
BA_ "GenSigSendType" SG_ 1069 PassSeatMsg_ModeSts 0;
BA_ "GenSigSendType" SG_ 1070 CWCR_42Eh_CRC1 0;
BA_ "GenSigSendType" SG_ 1070 CWCR_42Eh_RollgCntr1 0;
BA_ "GenSigSendType" SG_ 1070 CWCR_42Eh_Resd1 0;
BA_ "GenSigSendType" SG_ 1070 ChargingSts_42Eh 0;
BA_ "GenSigStartValue" SG_ 1070 WorkingSts_42Eh 1;
BA_ "GenSigSendType" SG_ 1070 WorkingSts_42Eh 0;
BA_ "GenSigSendType" SG_ 1070 Phoneforgotten_42Eh 0;
BA_ "GenSigStartValue" SG_ 1070 PhoneforgottenONOFFSts_42Eh 1;
BA_ "GenSigSendType" SG_ 1070 PhoneforgottenONOFFSts_42Eh 0;
BA_ "GenSigSendType" SG_ 1070 ChrgFlt_42Eh 0;
BA_ "GenSigSendType" SG_ 1070 ChargingSts_R_42Eh 0;
BA_ "GenSigStartValue" SG_ 1070 WorkingSts_R_42Eh 1;
BA_ "GenSigSendType" SG_ 1070 WorkingSts_R_42Eh 0;
BA_ "GenSigSendType" SG_ 1070 Phoneforgotten_R_42Eh 0;
BA_ "GenSigStartValue" SG_ 1070 PhoneforgottenONOFFStsR_42Eh 1;
BA_ "GenSigSendType" SG_ 1070 PhoneforgottenONOFFStsR_42Eh 0;
BA_ "GenSigSendType" SG_ 1070 ChrgFlt_R_42Eh 0;
BA_ "GenSigSendType" SG_ 1071 FLZCU_CarSearhSetSW 0;
BA_ "GenSigSendType" SG_ 1071 FLZCU_AutoFoldSts 0;
BA_ "GenSigSendType" SG_ 1071 FLZCU_AutolockSts 0;
BA_ "GenSigSendType" SG_ 1071 FLZCU_FGHeat_Req_CmdFeedback 0;
BA_ "GenSigSendType" SG_ 1071 FLZCU_WindowInhibitSts 0;
BA_ "GenSigSendType" SG_ 1071 FLZCU_AutoReadLightSts 0;
BA_ "GenSigSendType" SG_ 1071 FLZCU_HeatingSW 0;
BA_ "GenSigSendType" SG_ 1071 FLZCU_AutoHeatingFb 0;
BA_ "GenSigSendType" SG_ 1071 FLZCU_SteerNeedMemory 0;
BA_ "GenSigSendType" SG_ 1071 FLZCU_LowBeamFaults 0;
BA_ "GenSigSendType" SG_ 1071 FLZCU_RearNeedMemory 0;
BA_ "ASIL" SG_ 1071 FLZCU_BrkLightFaults 2;
BA_ "GenSigSendType" SG_ 1071 FLZCU_BrkLightFaults 0;
BA_ "GenSigSendType" SG_ 1071 FLZCU_TurnLiSwtSts 0;
BA_ "GenSigSendType" SG_ 1071 DrvHandleFoldedSts_42Fh 0;
BA_ "GenSigSendType" SG_ 1071 DrvRearHandleFoldedSts_42Fh 0;
BA_ "GenSigSendType" SG_ 1071 PassHandleFoldedSts_42Fh 0;
BA_ "GenSigSendType" SG_ 1071 PassRearHandleFoldedSts_42Fh 0;
BA_ "GenSigSendType" SG_ 1071 FLZCU_RvsExtMirrFbSts 0;
BA_ "GenSigSendType" SG_ 1071 FLZCU_LightMainSwitchSts 0;
BA_ "GenSigSendType" SG_ 1071 FLZCU_BeamDelaySts 0;
BA_ "GenSigSendType" SG_ 1071 FLZCU_LowBeamHighSts 0;
BA_ "GenSigSendType" SG_ 1071 FLZCU_WipeSensitivitySts 0;
BA_ "GenSigSendType" SG_ 1071 FLZCU_WipeMaintenanceSWSts 0;
BA_ "GenSigSendType" SG_ 1071 FLZCU_HiBeamSwtSts 0;
BA_ "GenSigSendType" SG_ 1071 FLZCU_ImmoRequest 0;
BA_ "GenSigSendType" SG_ 1071 FLZCU_AlarmWarnSetSW 0;
BA_ "GenSigSendType" SG_ 1071 FLZCU_CleanModeStatus 0;
BA_ "GenSigSendType" SG_ 1071 DrvReleaseLockSts_42Fh 0;
BA_ "GenSigSendType" SG_ 1071 FLZCU_RearFogLightSts 0;
BA_ "GenSigSendType" SG_ 1071 PassFoglightSts_42Fh 0;
BA_ "GenSigSendType" SG_ 1071 DrvFoglightSts_42Fh 0;
BA_ "GenSigSendType" SG_ 1071 FLZCU_RearFogLightFaults 0;
BA_ "GenSigSendType" SG_ 1071 FLZCU_HighBeamFaults 0;
BA_ "GenSigSendType" SG_ 1071 FLZCU_HighBeamSts 0;
BA_ "GenSigSendType" SG_ 1071 FLZCU_LowBeamSts 0;
BA_ "GenSigSendType" SG_ 1071 FLZCU_ParkUnlockEnableFb 0;
BA_ "GenSigSendType" SG_ 1071 DrvRearReleaseLockSts_42Fh 0;
BA_ "GenSigSendType" SG_ 1071 FLZCU_EasyEntryExitFb 0;
BA_ "GenSigSendType" SG_ 1071 FLZCU_EmgyLiSwtSts 0;
BA_ "GenSigSendType" SG_ 1071 FLZCU_HMASwSts 0;
BA_ "GenSigSendType" SG_ 1071 FLZCU_DaytimeLight 0;
BA_ "GenSigSendType" SG_ 1071 FLZCU_FGHeatFaults 0;
BA_ "GenSigSendType" SG_ 1071 FLZCU_ParkLightFaults 0;
BA_ "GenSigSendType" SG_ 1071 FLZCU_LbatipVehPwrMod 0;
BA_ "GenSigSendType" SG_ 1071 FLZCU_HMASwSts_MDC 0;
BA_ "GenSigSendType" SG_ 1071 FLZCU_LVPowICDsp 0;
BA_ "GenSigSendType" SG_ 1071 FLZCU_LockCarWinCloseFb 0;
BA_ "ASIL" SG_ 1071 FLZCU_BrkLightSts 2;
BA_ "GenSigSendType" SG_ 1071 FLZCU_BrkLightSts 0;
BA_ "GenSigSendType" SG_ 1071 FLZCU_ReverseLightSts 0;
BA_ "GenSigSendType" SG_ 1071 FLZCU_LowWashLqdWarning 0;
BA_ "GenSigSendType" SG_ 1071 FLZCU_SteerWheelHeatingFb 0;
BA_ "GenSigSendType" SG_ 1071 FLZCU_FrontFogLightSts 0;
BA_ "GenSigSendType" SG_ 1071 FLZCU_NapAreaFb 0;
BA_ "GenSigSendType" SG_ 1071 FLZCU_NapTimeFb 0;
BA_ "GenSigSendType" SG_ 1071 FLZCU_NapAlarmStatus 0;
BA_ "GenSigSendType" SG_ 1071 FLZCU_NapFailCause 0;
BA_ "GenSigSendType" SG_ 1071 FLZCU_NapStatusFb 0;
BA_ "GenSigSendType" SG_ 1071 FLZCU_CleanModeFailCause 0;
BA_ "GenSigSendType" SG_ 1071 LockCarSunRoofShadeCloseFb 0;
BA_ "GenSigSendType" SG_ 1071 FLZCU_NapClosePrompt 0;
BA_ "GenSigSendType" SG_ 1071 FLZCU_AutoWipingInhibit 0;
BA_ "GenSigSendType" SG_ 1071 FLZCU_RemoteUnlockFb 0;
BA_ "ASIL" SG_ 1071 FLZCU_FrntWiprSwSts 1;
BA_ "GenSigSendType" SG_ 1071 FLZCU_FrntWiprSwSts 0;
BA_ "ASIL" SG_ 1071 TurnLightFaults_42Fh 2;
BA_ "GenSigSendType" SG_ 1071 TurnLightFaults_42Fh 0;
BA_ "GenSigSendType" SG_ 1071 FLZCU_HazardLightSWSts_42Fh 0;
BA_ "GenSigSendType" SG_ 1071 DrvRearWinSts_42Fh 0;
BA_ "GenSigSendType" SG_ 1071 DrvWinSts_42Fh 0;
BA_ "GenSigSendType" SG_ 1071 FLZCU_DaytimeLightFaults 0;
BA_ "GenSigSendType" SG_ 1071 FLZCU_FrontFogLightFaults 0;
BA_ "GenSigSendType" SG_ 1071 FLZCU_HomeLinkWelLightSetSts 0;
BA_ "GenSigSendType" SG_ 1071 FLZCU_HomeLinkArmHornSetSts 0;
BA_ "GenSigSendType" SG_ 1071 FLZCU_UIROpenStas 0;
BA_ "GenSigSendType" SG_ 1071 FLZCU_WALOpenStas 0;
BA_ "GenSigSendType" SG_ 1071 FLZCU_WelcomeOpenStas 0;
BA_ "GenSigSendType" SG_ 1071 FLZCU_RearWiprSwSts_42Fh 0;
BA_ "GenSigSendType" SG_ 1071 FLZCU_ExtLiSwtClsSts 0;
BA_ "GenSigSendType" SG_ 1072 AutoSeatHeatLevelsFb_430h 0;
BA_ "GenSigSendType" SG_ 1072 AutoSteerWhlHeatFb_430h 0;
BA_ "GenSigSendType" SG_ 1072 AutoSeatVentLevelsFb_430h 0;
BA_ "ASIL" SG_ 1072 DrvDoorSts_430h 1;
BA_ "GenSigSendType" SG_ 1072 DrvDoorSts_430h 0;
BA_ "ASIL" SG_ 1072 DrvSeatBeltSW_430h 1;
BA_ "GenSigSendType" SG_ 1072 DrvSeatBeltSW_430h 0;
BA_ "GenSigInvalidValue" SG_ 1072 DrvRearWinPosn_430h 127;
BA_ "GenSigStartValue" SG_ 1072 DrvRearWinPosn_430h 127;
BA_ "GenSigSendType" SG_ 1072 DrvRearWinPosn_430h 0;
BA_ "GenSigSendType" SG_ 1072 DrvSeatHeatLevels_430h 0;
BA_ "GenSigSendType" SG_ 1072 DrvRearChildProtectSwt_430h 0;
BA_ "GenSigSendType" SG_ 1072 DrvSecSeatHeatLevels_430h 0;
BA_ "GenSigSendType" SG_ 1072 DrvSeatVentLevels_430h 0;
BA_ "GenSigSendType" SG_ 1072 DrvSecSeatVentLevels_430h 0;
BA_ "GenSigInvalidValue" SG_ 1072 DrvWinPosn_430h 127;
BA_ "GenSigStartValue" SG_ 1072 DrvWinPosn_430h 127;
BA_ "GenSigSendType" SG_ 1072 DrvWinPosn_430h 0;
BA_ "GenSigSendType" SG_ 1072 FLZCU_RearWiperMaintenanceSts 0;
BA_ "GenSigSendType" SG_ 1072 FLZCU_FrontWiperMaintenanceSts 0;
BA_ "GenSigSendType" SG_ 1073 RearDoorSta_431h 0;
BA_ "GenSigSendType" SG_ 1073 RearDoorMoveDirection_431h 0;
BA_ "GenSigInvalidValue" SG_ 1073 RearDoorOpenDegree_431h 255;
BA_ "GenSigSendType" SG_ 1073 RearDoorOpenDegree_431h 0;
BA_ "GenSigSendType" SG_ 1075 VCC_2_ConfigurationMessageTrg 2;
BA_ "GenSigInvalidValue" SG_ 1078 PLG_LatchSts 3;
BA_ "GenSigStartValue" SG_ 1078 PLG_LatchSts 2;
BA_ "GenSigSendType" SG_ 1078 PLG_LatchSts 0;
BA_ "GenSigInvalidValue" SG_ 1078 PLG_Set_PLGOperateStsFb 255;
BA_ "GenSigSendType" SG_ 1078 PLG_Set_PLGOperateStsFb 0;
BA_ "GenSigSendType" SG_ 1079 BSCU_1_MotorLockSts 0;
BA_ "GenSigSendType" SG_ 1087 RightSeatMsgStr_LvlSts 0;
BA_ "GenSigSendType" SG_ 1087 RightSeatMsg_ModeSts 0;
BA_ "GenSigSendType" SG_ 1095 RLCR_1_CRC1 0;
BA_ "GenSigSendType" SG_ 1095 RLCR_1_RollgCntr1 0;
BA_ "GenSigSendType" SG_ 1095 RLCR_1_Resd1 0;
BA_ "GenSigSendType" SG_ 1095 RLCR_1_SysSt 0;
BA_ "GenSigSendType" SG_ 1095 RLCR_1_BlkSts 0;
BA_ "GenSigSendType" SG_ 1095 RLCR_1_BSDWarn 0;
BA_ "GenSigSendType" SG_ 1095 RLCR_1_ELK_Collision_flag 0;
BA_ "GenSigSendType" SG_ 1095 RLCR_1_ELK_CollisionFlagValid 0;
BA_ "GenSigSendType" SG_ 1096 TMS_AirPurgeReminderSts 0;
BA_ "GenSigSendType" SG_ 1096 TMS_CirculationInTunnelsSts 0;
BA_ "GenSigSendType" SG_ 1096 TMS_First_BlowingSts 0;
BA_ "GenSigSendType" SG_ 1096 TMS_BT_Reduce_Wind_SpeedSts 0;
BA_ "GenSigSendType" SG_ 1096 TMS_CoolantFillSts 0;
BA_ "GenSigSendType" SG_ 1096 TMS_ParkingAirConditioningStatus 0;
BA_ "GenSigSendType" SG_ 1096 TMS_crosscountry_coolingSts 0;
BA_ "GenSigSendType" SG_ 1096 TMS_ICC_Lightoff_Sts 0;
BA_ "GenSigSendType" SG_ 1096 TMS_UVC_LuminanceSts 0;
BA_ "GenSigSendType" SG_ 1096 TMS_AutoDefogActiveSts 0;
BA_ "GenSigSendType" SG_ 1096 TMS_UVC_ControlSts 0;
BA_ "GenSigSendType" SG_ 1096 TMS_ICC_Memoff_Sts 0;
BA_ "GenSigSendType" SG_ 1096 TMS_keepwarmSet_TemperatureSts 0;
BA_ "GenSigSendType" SG_ 1096 TMS_BiochemicalFuncSts 0;
BA_ "GenSigSendType" SG_ 1096 TMS_TimedVentilationSts 0;
BA_ "GenSigSendType" SG_ 1096 TMS_LowbattACDisable_448h 0;
BA_ "GenSigSendType" SG_ 1096 TMS_SailEACDisable_448h 0;
BA_ "GenSigSendType" SG_ 1096 TMS_ICAstsFed_448h 0;
BA_ "GenSigSendType" SG_ 1099 ISGF_SysTempOvrInd 0;
BA_ "GenSigSendType" SG_ 1100 Set_AMPNaviVolume 2;
BA_ "GenSigSendType" SG_ 1100 Set_AMPVRVolume 2;
BA_ "GenSigSendType" SG_ 1100 Set_AMPKeyTone 2;
BA_ "GenSigSendType" SG_ 1100 Set_AMPMediaVolume 2;
BA_ "GenSigSendType" SG_ 1100 Set_AMPPhoneVolume 2;
BA_ "GenSigSendType" SG_ 1100 Set_AMPSoundFocus 2;
BA_ "GenSigSendType" SG_ 1100 Set_AMPSoundEffect 2;
BA_ "GenSigSendType" SG_ 1100 Set_AMPSoundEffectBass 2;
BA_ "GenSigSendType" SG_ 1100 Set_AMPSoundEffectMidrange 2;
BA_ "GenSigSendType" SG_ 1100 Set_AMPSoundEffectTreble 2;
BA_ "GenSigSendType" SG_ 1100 Set_AMPSoundFieldBalance 2;
BA_ "GenSigSendType" SG_ 1100 Set_AMPSoundFieldFader 2;
BA_ "GenSigSendType" SG_ 1100 ICC_AMPVRVolume_44Ch 2;
BA_ "GenSigSendType" SG_ 1100 Set_Headrest_Mode 2;
BA_ "GenSigSendType" SG_ 1100 Set_SurndFnOnOff 2;
BA_ "GenSigSendType" SG_ 1100 Set_VirtualSbwfrOnOff 2;
BA_ "GenSigSendType" SG_ 1104 RLCR_2_CRC1 0;
BA_ "GenSigSendType" SG_ 1104 RLCR_2_RollgCntr1 0;
BA_ "GenSigSendType" SG_ 1104 RLCR_2_Resd1 0;
BA_ "GenSigSendType" SG_ 1104 RLCR_2_RCWWarn 0;
BA_ "GenSigSendType" SG_ 1104 RLCR_2_RCTAWarn 0;
BA_ "GenSigSendType" SG_ 1104 RLCR_2_BSDLCWONOFFSts 0;
BA_ "GenSigSendType" SG_ 1104 RLCR_2_DOWONOFFSts 0;
BA_ "GenSigSendType" SG_ 1104 RLCR_2_RCWONOFFSts 0;
BA_ "GenSigSendType" SG_ 1104 RLCR_2_RCTARCTBONOFFSts 0;
BA_ "GenSigSendType" SG_ 1105 ICC_MultiplexSignalStatusSet 2;
BA_ "GenSigInvalidValue" SG_ 1107 TMS_CCP_FLTempSts 31;
BA_ "GenSigStartValue" SG_ 1107 TMS_CCP_FLTempSts 31;
BA_ "GenSigSendType" SG_ 1107 TMS_CCP_FLTempSts 0;
BA_ "GenSigSendType" SG_ 1107 TMS_CCP_FrontAutoACSts 0;
BA_ "GenSigSendType" SG_ 1107 TMS_PM25_Detect 0;
BA_ "GenSigSendType" SG_ 1107 TMS_CCP_FrontDefrostSts 0;
BA_ "GenSigSendType" SG_ 1107 TMS_CCP_FBlowSpdCtrlSts 0;
BA_ "GenSigSendType" SG_ 1107 TMS_CCP_FrontOFFSts 0;
BA_ "GenSigSendType" SG_ 1107 TMS_CCP_ACStatus 0;
BA_ "GenSigInvalidValue" SG_ 1107 TMS_CCP_FRTempSts 31;
BA_ "GenSigStartValue" SG_ 1107 TMS_CCP_FRTempSts 31;
BA_ "GenSigSendType" SG_ 1107 TMS_CCP_FRTempSts 0;
BA_ "GenSigSendType" SG_ 1107 TMS_CCP_RecyMode 0;
BA_ "GenSigSendType" SG_ 1107 TMS_CCP_ACFastHeat 0;
BA_ "GenSigSendType" SG_ 1107 TMS_CCP_ACFastCool 0;
BA_ "GenSigSendType" SG_ 1107 TMS_UVC_LuminanceBfReq 0;
BA_ "GenSigSendType" SG_ 1107 TMS_UVC_WorkingBfReq 0;
BA_ "GenSigInvalidValue" SG_ 1107 TMS_ThrSetTempFb_C_453h 31;
BA_ "GenSigStartValue" SG_ 1107 TMS_ThrSetTempFb_C_453h 31;
BA_ "GenSigSendType" SG_ 1107 TMS_ThrSetTempFb_C_453h 0;
BA_ "GenSigStartValue" SG_ 1107 TMS_ThrModeStsFb_453h 7;
BA_ "GenSigSendType" SG_ 1107 TMS_ThrModeStsFb_453h 0;
BA_ "GenSigSendType" SG_ 1107 TMS_ThrCLMSwitchFb_453h 0;
BA_ "GenSigSendType" SG_ 1107 TMS_ThrAutoSwitchFb_453h 0;
BA_ "GenSigSendType" SG_ 1107 TMS_ThrACReqKeyStsFb_453h 0;
BA_ "GenSigSendType" SG_ 1109 CWC_1_CRC1 0;
BA_ "GenSigSendType" SG_ 1109 CWC_1_RollgCntr1 0;
BA_ "GenSigSendType" SG_ 1109 CWC_1_Resd1 0;
BA_ "GenSigSendType" SG_ 1109 CWC_ChargingSts 0;
BA_ "GenSigStartValue" SG_ 1109 CWC_workingSts 1;
BA_ "GenSigSendType" SG_ 1109 CWC_workingSts 0;
BA_ "GenSigSendType" SG_ 1109 CWC_Phoneforgotten 0;
BA_ "GenSigStartValue" SG_ 1109 CWC_Phoneforgotten_ON_OFF_Sts 1;
BA_ "GenSigSendType" SG_ 1109 CWC_Phoneforgotten_ON_OFF_Sts 0;
BA_ "GenSigSendType" SG_ 1109 CWC_1_ChrgFlt 0;
BA_ "GenSigSendType" SG_ 1109 CWC_ChargingSts_R 0;
BA_ "GenSigStartValue" SG_ 1109 CWC_workingSts_R 1;
BA_ "GenSigSendType" SG_ 1109 CWC_workingSts_R 0;
BA_ "GenSigSendType" SG_ 1109 CWC_Phoneforgotten_R 0;
BA_ "GenSigStartValue" SG_ 1109 CWC_Phoneforgotten_ON_OFF_Sts_R 1;
BA_ "GenSigSendType" SG_ 1109 CWC_Phoneforgotten_ON_OFF_Sts_R 0;
BA_ "GenSigSendType" SG_ 1109 CWC_1_ChrgFlt_R 0;
BA_ "GenSigSendType" SG_ 1110 IMMO_Chall_ICC 1;
BA_ "GenSigSendType" SG_ 1112 PassSeatMsgStr_LvlCmd_458h 2;
BA_ "GenSigSendType" SG_ 1112 PassSeatMsg_ModeCmd_458h 2;
BA_ "GenSigSendType" SG_ 1112 DriverSeatMsgStr_Lvlcmd 2;
BA_ "GenSigSendType" SG_ 1112 DriverSeatMsg_ModeCmd 2;
BA_ "GenSigSendType" SG_ 1112 ICC_DSeatInOrDeflationCmd_458h 2;
BA_ "GenSigSendType" SG_ 1112 ICC_DSeatBolsterModeCmd_458h 2;
BA_ "GenSigSendType" SG_ 1112 PassSecSeatMsgStr_LvlCmd_458h 2;
BA_ "GenSigSendType" SG_ 1112 PassSecSeatMsg_ModeCmd_458h 2;
BA_ "GenSigSendType" SG_ 1112 DrvSecSeatMsgStr_LvlCmd_458h 2;
BA_ "GenSigSendType" SG_ 1112 DrvSecSeatMsg_ModeCmd_458h 2;
BA_ "GenSigSendType" SG_ 1116 ICC_Auth_IMMO 1;
BA_ "GenSigSendType" SG_ 1119 Set_AMPMediaDuck 2;
BA_ "GenSigSendType" SG_ 1119 Set_AMPSpeedVolume 2;
BA_ "GenSigSendType" SG_ 1119 Set_AMPMute 2;
BA_ "GenSigSendType" SG_ 1119 REQ_AMPA2BMediaSound 2;
BA_ "GenSigSendType" SG_ 1119 REQ_AMPA2BNaviSound 2;
BA_ "GenSigSendType" SG_ 1119 REQ_AMPA2BVRSound 2;
BA_ "GenSigSendType" SG_ 1119 REQ_AMPA2BTTSSound 2;
BA_ "GenSigSendType" SG_ 1119 ICC_AMPPhoneVolume_45Fh 2;
BA_ "GenSigSendType" SG_ 1119 REQ_AMPA2BKeyTone 2;
BA_ "GenSigSendType" SG_ 1119 Set_AMPRestoreDefaults 2;
BA_ "GenSigSendType" SG_ 1119 Set_AMPAlarmVolume 2;
BA_ "GenSigSendType" SG_ 1119 REQ_AMPA2BPhoneSound 2;
BA_ "GenSigSendType" SG_ 1119 Set_AMPSoundEffectMegaBass 2;
BA_ "GenSigSendType" SG_ 1119 Set_AMPSoundEffectMidBass 2;
BA_ "GenSigSendType" SG_ 1119 Set_AMPSoundEffectMidTreble 2;
BA_ "GenSigSendType" SG_ 1119 Set_AMPSoundBypass 2;
BA_ "GenSigSendType" SG_ 1119 Set_AMPA2BConfig 2;
BA_ "GenSigSendType" SG_ 1119 Set_AMPBackgroundVolume 2;
BA_ "GenSigSendType" SG_ 1119 ICC_AMPNaviVolume_45Fh 2;
BA_ "GenSigInvalidValue" SG_ 1120 RLHS_2_AmbBrightness 4095;
BA_ "GenSigSendType" SG_ 1120 RLHS_2_AmbBrightness 0;
BA_ "GenSigSendType" SG_ 1120 RLHS_LiSwithReason 0;
BA_ "GenSigSendType" SG_ 1121 STAT_AMPNaviVolume 0;
BA_ "GenSigSendType" SG_ 1121 STAT_AMPVRVolume 0;
BA_ "GenSigSendType" SG_ 1121 STAT_AMPKeyTone 0;
BA_ "GenSigSendType" SG_ 1121 STAT_AMPMediaVolume 0;
BA_ "GenSigSendType" SG_ 1121 STAT_AMPPhoneVolume 0;
BA_ "GenSigSendType" SG_ 1121 STAT_AMPSoundFocus 0;
BA_ "GenSigSendType" SG_ 1121 STAT_AMPSoundEffect 0;
BA_ "GenSigSendType" SG_ 1121 STAT_AMPSoundEffectBass 0;
BA_ "GenSigSendType" SG_ 1121 STAT_AMPSoundEffectMidrange 0;
BA_ "GenSigSendType" SG_ 1121 STAT_AMPSoundEffectTreble 0;
BA_ "GenSigSendType" SG_ 1121 STAT_AMPSoundFieldBalance 0;
BA_ "GenSigSendType" SG_ 1121 STAT_AMPSoundFieldFader 0;
BA_ "GenSigSendType" SG_ 1121 STAT_REQ_AMPA2BMediaSound 0;
BA_ "GenSigSendType" SG_ 1121 STAT_REQ_AMPA2BNaviSound 0;
BA_ "GenSigSendType" SG_ 1121 STAT_REQ_AMPA2BVRSound 0;
BA_ "GenSigSendType" SG_ 1121 STAT_REQ_AMPA2BTTSSound 0;
BA_ "GenSigSendType" SG_ 1121 STAT_REQ_AMPA2BPhoneSound 0;
BA_ "GenSigSendType" SG_ 1121 STAT_REQ_AMPAlarm 0;
BA_ "GenSigSendType" SG_ 1123 IMMOCodeWarningLightSts_463h 0;
BA_ "GenSigSendType" SG_ 1123 ISS_Switch_Sts_463h 0;
BA_ "ASIL" SG_ 1127 DCDC_FaultLevelSts 2;
BA_ "GenSigSendType" SG_ 1127 DCDC_FaultLevelSts 0;
BA_ "GenSigInvalidValue" SG_ 1128 ISS_Sts_GS_468h 31;
BA_ "GenSigSendType" SG_ 1128 ISS_Sts_GS_468h 0;
BA_ "GenSigSendType" SG_ 1128 PromptMesg_468h 0;
BA_ "GenSigSendType" SG_ 1128 GPFWarning_468h 0;
BA_ "GenSigInvalidValue" SG_ 1128 FuelRollingCounter_468h 255;
BA_ "GenSigStartValue" SG_ 1128 FuelRollingCounter_468h 255;
BA_ "GenSigSendType" SG_ 1128 FuelRollingCounter_468h 0;
BA_ "GenSigSendType" SG_ 1128 MILSts_468h 0;
BA_ "GenSigSendType" SG_ 1128 IEMSts_468h 0;
BA_ "GenSigSendType" SG_ 1128 EPCSts_468h 0;
BA_ "GenSigSendType" SG_ 1128 FuelRollingCounterValidData_468h 0;
BA_ "GenSigSendType" SG_ 1128 CruiseControlStsForDisplay_468h 0;
BA_ "GenSigSendType" SG_ 1128 Crosscountry_coolingSts_468h 0;
BA_ "GenSigInvalidValue" SG_ 1129 EngineCoolantTemp_469h 255;
BA_ "GenSigStartValue" SG_ 1129 EngineCoolantTemp_469h 91;
BA_ "GenSigSendType" SG_ 1129 EngineCoolantTemp_469h 0;
BA_ "GenSigInvalidValue" SG_ 1129 EngineSpeed_469h 2047;
BA_ "GenSigSendType" SG_ 1129 EngineSpeed_469h 0;
BA_ "GenSigSendType" SG_ 1129 EngineSpeedValidData_469h 0;
BA_ "GenSigSendType" SG_ 1130 TCU_23_GBFaultstatus 0;
BA_ "GenSigSendType" SG_ 1130 TCU_23_TeachInState 0;
BA_ "GenSigSendType" SG_ 1130 TCU_23_CluSelfLrng 0;
BA_ "GenSigSendType" SG_ 1131 New_Signal_46B_4 0;
BA_ "GenSigSendType" SG_ 1131 New_Signal_46B_3 0;
BA_ "GenSigSendType" SG_ 1131 New_Signal_46B_2 0;
BA_ "GenSigSendType" SG_ 1131 New_Signal_46B_1 0;
BA_ "GenSigInvalidValue" SG_ 1131 GBPositoionDisplay_46Bh 31;
BA_ "GenSigSendType" SG_ 1131 GBPositoionDisplay_46Bh 0;
BA_ "GenSigSendType" SG_ 1131 SpeParkSts_46Bh 0;
BA_ "GenSigSendType" SG_ 1131 GBFaultstatus_46Bh 0;
BA_ "GenSigSendType" SG_ 1131 ClutchTemperature_46Bh 0;
BA_ "GenSigSendType" SG_ 1136 VCC_3_CRC 2;
BA_ "GenSigSendType" SG_ 1136 VCC_3_RollgCntr 2;
BA_ "GenSigSendType" SG_ 1136 VCC_3_Resd1 2;
BA_ "GenSigStartValue" SG_ 1136 VCC_3_SN 1;
BA_ "GenSigSendType" SG_ 1136 VCC_3_SN 2;
BA_ "GenSigSendType" SG_ 1137 ICC_BookChrgSetReq 2;
BA_ "GenSigSendType" SG_ 1137 ICC_BkChrgStartTimeYear 0;
BA_ "GenSigStartValue" SG_ 1137 ICC_BkChrgStartTimeDay 1;
BA_ "GenSigSendType" SG_ 1137 ICC_BkChrgStartTimeDay 0;
BA_ "GenSigInvalidValue" SG_ 1137 ICC_BkChrgStartTimeHour 31;
BA_ "GenSigSendType" SG_ 1137 ICC_BkChrgStartTimeHour 2;
BA_ "GenSigInvalidValue" SG_ 1137 ICC_BkChrgStartTimemMin 63;
BA_ "GenSigSendType" SG_ 1137 ICC_BkChrgStartTimemMin 2;
BA_ "GenSigInvalidValue" SG_ 1137 ICC_BkChrgDuration 2047;
BA_ "GenSigSendType" SG_ 1137 ICC_BkChrgDuration 2;
BA_ "GenSigStartValue" SG_ 1137 ICC_BkChrgStartTimeMonth 1;
BA_ "GenSigSendType" SG_ 1137 ICC_BkChrgStartTimeMonth 0;
BA_ "GenSigSendType" SG_ 1137 ICC_BkChrgCycleMon 0;
BA_ "GenSigSendType" SG_ 1137 ICC_StopChrgReq 2;
BA_ "GenSigSendType" SG_ 1137 ICC_BkChrgCycleType 0;
BA_ "GenSigSendType" SG_ 1137 ICC_BkChrgCycleFri 0;
BA_ "GenSigSendType" SG_ 1137 ICC_BkChrgCycleThur 0;
BA_ "GenSigSendType" SG_ 1137 ICC_BkChrgCycleWen 0;
BA_ "GenSigSendType" SG_ 1137 ICC_BkChrgCycleTues 0;
BA_ "GenSigSendType" SG_ 1137 ICC_BkChrgCycleSun 0;
BA_ "GenSigSendType" SG_ 1137 ICC_BkChrgCycleSat 0;
BA_ "GenSigStartValue" SG_ 1137 ICC_KeepWarmStrt 1;
BA_ "GenSigSendType" SG_ 1137 ICC_KeepWarmStrt 0;
BA_ "GenSigInvalidValue" SG_ 1137 ICC_KeepWarmStrtHour 31;
BA_ "GenSigSendType" SG_ 1137 ICC_KeepWarmStrtHour 2;
BA_ "GenSigInvalidValue" SG_ 1137 ICC_KeepWarmStrtMin 63;
BA_ "GenSigSendType" SG_ 1137 ICC_KeepWarmStrtMin 2;
BA_ "GenSigInvalidValue" SG_ 1137 ICC_PetmodeFb 3;
BA_ "GenSigSendType" SG_ 1137 ICC_PetmodeFb 0;
BA_ "GenSigSendType" SG_ 1137 ICC_SentinelModeFaultSts 0;
BA_ "GenSigSendType" SG_ 1137 ICC_SentinelModeWorkingSts 0;
BA_ "GenSigSendType" SG_ 1137 ICC_SentinelModeSwitchSts 0;
BA_ "GenSigSendType" SG_ 1137 ICC_PetModeWarn 0;
BA_ "GenSigSendType" SG_ 1137 ICC_SentinelModeExitReason 0;
BA_ "GenSigSendType" SG_ 1137 ICC_SentinelModeAlarmSts 0;
BA_ "GenSigSendType" SG_ 1137 ICC_TBOXPetmodeReq 2;
BA_ "GenSigSendType" SG_ 1137 ICC_PetModeWarn_2 0;
BA_ "GenSigInvalidValue" SG_ 1137 ICC_GPSSailingSpeed_471h 63;
BA_ "GenSigSendType" SG_ 1137 ICC_GPSSailingSpeed_471h 0;
BA_ "GenSigSendType" SG_ 1137 ICM_FuelLevel 0;
BA_ "GenSigSendType" SG_ 1137 ICM_AverageVehicleSpeed 0;
BA_ "GenSigInvalidValue" SG_ 1137 ICM_DistenceToEmpty_Km 2047;
BA_ "GenSigSendType" SG_ 1137 ICM_DistenceToEmpty_Km 0;
BA_ "GenSigSendType" SG_ 1137 ICC_ElectronicFenceStsFed_471h 0;
BA_ "GenSigSendType" SG_ 1137 ICM_Maintenance_tips 0;
BA_ "GenSigSendType" SG_ 1137 ICM_FuelLevelFailSts 0;
BA_ "GenSigSendType" SG_ 1137 ICM_SumTrip 0;
BA_ "GenSigInvalidValue" SG_ 1137 ICC_ChgSOCPrioritySet_471h 3;
BA_ "GenSigStartValue" SG_ 1137 ICC_ChgSOCPrioritySet_471h 3;
BA_ "GenSigSendType" SG_ 1137 ICC_ChgSOCPrioritySet_471h 2;
BA_ "GenSigSendType" SG_ 1140 STAT_AMPSoundEffectSupTreble 0;
BA_ "GenSigSendType" SG_ 1140 STAT_AMPMediaDuck 0;
BA_ "GenSigSendType" SG_ 1140 STAT_AMPSpeedVolume 0;
BA_ "GenSigSendType" SG_ 1140 STAT_AMPMute 0;
BA_ "GenSigSendType" SG_ 1140 STAT_AMPRestoreDefaults 0;
BA_ "GenSigSendType" SG_ 1140 STAT_AMPAlarmVolume 0;
BA_ "GenSigSendType" SG_ 1140 STAT_Headrest_Mode 0;
BA_ "GenSigSendType" SG_ 1140 STAT_AMPSoundEffectMegaBass 0;
BA_ "GenSigSendType" SG_ 1140 STAT_AMPSoundEffectMidBass 0;
BA_ "GenSigSendType" SG_ 1140 STAT_AMPSoundEffectMidTreble 0;
BA_ "GenSigSendType" SG_ 1140 STAT_VirtualSbwfrOnOff 0;
BA_ "GenSigSendType" SG_ 1140 STAT_SurndFnOnOff 0;
BA_ "GenSigSendType" SG_ 1140 STAT_AMPBackgroundVolume 0;
BA_ "GenSigSendType" SG_ 1140 STAT_AMPSoundBypass 0;
BA_ "GenSigSendType" SG_ 1140 STAT_AMPPwrRdySts 0;
BA_ "GenSigSendType" SG_ 1140 STAT_AMPVersion 0;
BA_ "GenSigSendType" SG_ 1141 APADispSts_475h 0;
BA_ "GenSigSendType" SG_ 1141 APA_FuncRecommend_475h 0;
BA_ "GenSigSendType" SG_ 1141 APAPrkgChimeVoice_475h 0;
BA_ "GenSigSendType" SG_ 1141 AvmWinDisp_475h 0;
BA_ "GenSigSendType" SG_ 1141 ApaRpaSts_475h 0;
BA_ "GenSigSendType" SG_ 1141 AVMFaultStatusCameraFront_475h 0;
BA_ "GenSigSendType" SG_ 1141 AVMFaultStatusCameraLeft_475h 0;
BA_ "GenSigSendType" SG_ 1141 AVMFaultStatusCameraRear_475h 0;
BA_ "GenSigSendType" SG_ 1141 AVMFaultStatusCameraRight_475h 0;
BA_ "GenSigSendType" SG_ 1141 APA_ParkingVoiceRemind_475h 0;
BA_ "GenSigSendType" SG_ 1141 MRASts_475h 0;
BA_ "GenSigInvalidValue" SG_ 1142 HCU_4_G_AvgFuCns 499;
BA_ "GenSigSendType" SG_ 1142 HCU_4_G_AvgFuCns 0;
BA_ "GenSigInvalidValue" SG_ 1142 HCU_4_G_AvgEnergyCns 499;
BA_ "GenSigSendType" SG_ 1142 HCU_4_G_AvgEnergyCns 0;
BA_ "GenSigInvalidValue" SG_ 1142 HCU_4_G_SumEgyCns 511;
BA_ "GenSigSendType" SG_ 1142 HCU_4_G_SumEgyCns 0;
BA_ "GenSigSendType" SG_ 1143 OBC_CC_ConnectSts 0;
BA_ "GenSigSendType" SG_ 1143 CDU_MILSts 0;
BA_ "GenSigSendType" SG_ 1143 OBC_InnerDischgReq 0;
BA_ "GenSigInvalidValue" SG_ 1144 ICC_HvBattKeepWarmSet 3;
BA_ "GenSigStartValue" SG_ 1144 ICC_HvBattKeepWarmSet 3;
BA_ "GenSigSendType" SG_ 1144 ICC_HvBattKeepWarmSet 0;
BA_ "GenSigSendType" SG_ 1144 ICC_CarSickRelfModeReq 2;
BA_ "GenSigSendType" SG_ 1144 ICC_EnergyRegSet 2;
BA_ "GenSigSendType" SG_ 1144 ICC_HvBattKeepWarmActiveReq 2;
BA_ "GenSigSendType" SG_ 1147 CCP_1_FrontAutoACSwitchReq 0;
BA_ "GenSigInvalidValue" SG_ 1147 CCP_1_FLTempSwitchReq 31;
BA_ "GenSigStartValue" SG_ 1147 CCP_1_FLTempSwitchReq 31;
BA_ "GenSigSendType" SG_ 1147 CCP_1_FLTempSwitchReq 0;
BA_ "GenSigSendType" SG_ 1147 FLCCP_MainSetHeatReq 0;
BA_ "GenSigSendType" SG_ 1147 CCP_1_FrontOFFSwitchReq 0;
BA_ "GenSigSendType" SG_ 1147 CCP_1_FBlowSpdCtrlSwitchReq 0;
BA_ "GenSigSendType" SG_ 1147 CCP_1_ACFastCool 0;
BA_ "GenSigSendType" SG_ 1147 FLCCP_MainSetVentilationReq 0;
BA_ "GenSigStartValue" SG_ 1148 TBOX_BkChrgStartTimeDay 1;
BA_ "GenSigSendType" SG_ 1148 TBOX_BkChrgStartTimeDay 0;
BA_ "GenSigSendType" SG_ 1148 TBOX_BkChrgStartTimeeHour 0;
BA_ "GenSigSendType" SG_ 1148 TBOX_GPSSwitchSts 0;
BA_ "GenSigSendType" SG_ 1148 TBOX_BkChrgStartTimeMin 0;
BA_ "GenSigStartValue" SG_ 1148 TBOX_BkChrgStartTimeMonth 1;
BA_ "GenSigSendType" SG_ 1148 TBOX_BkChrgStartTimeMonth 0;
BA_ "GenSigSendType" SG_ 1148 TBOX_BkChrgStartTimeYear 0;
BA_ "GenSigSendType" SG_ 1148 TBOX_BkChrgDuration 0;
BA_ "GenSigSendType" SG_ 1148 TBOX_BkChrgCycleType 0;
BA_ "GenSigSendType" SG_ 1148 TBOX_BkChrgCycleThur 0;
BA_ "GenSigSendType" SG_ 1148 TBOX_BkChrgCycleWen 0;
BA_ "GenSigSendType" SG_ 1148 TBOX_BkChrgCycleTues 0;
BA_ "GenSigSendType" SG_ 1148 TBOX_BkChrgCycleMon 0;
BA_ "GenSigSendType" SG_ 1148 TBOX_BkChrgCycleSun 0;
BA_ "GenSigSendType" SG_ 1148 TBOX_BkChrgCycleSat 0;
BA_ "GenSigSendType" SG_ 1148 TBOX_BkChrgCycleFri 0;
BA_ "GenSigStartValue" SG_ 1148 TBOX_KeepWarmStrt 1;
BA_ "GenSigSendType" SG_ 1148 TBOX_KeepWarmStrt 0;
BA_ "GenSigSendType" SG_ 1148 TBOX_KeepWarmStrtHour 0;
BA_ "GenSigSendType" SG_ 1148 TBOX_KeepWarmStrtMin 0;
BA_ "GenSigSendType" SG_ 1148 TimeToStartSentinelDayFed_47Ch 0;
BA_ "GenSigInvalidValue" SG_ 1148 TimeToStartSentinelHourFed_47Ch 31;
BA_ "GenSigStartValue" SG_ 1148 TimeToStartSentinelHourFed_47Ch 30;
BA_ "GenSigSendType" SG_ 1148 TimeToStartSentinelHourFed_47Ch 0;
BA_ "GenSigInvalidValue" SG_ 1148 TimeToStartSentinelMinutFed_47Ch 63;
BA_ "GenSigStartValue" SG_ 1148 TimeToStartSentinelMinutFed_47Ch 62;
BA_ "GenSigSendType" SG_ 1148 TimeToStartSentinelMinutFed_47Ch 0;
BA_ "GenSigInvalidValue" SG_ 1148 TimeToStopSentinelHourFed_47Ch 31;
BA_ "GenSigStartValue" SG_ 1148 TimeToStopSentinelHourFed_47Ch 30;
BA_ "GenSigSendType" SG_ 1148 TimeToStopSentinelHourFed_47Ch 0;
BA_ "GenSigInvalidValue" SG_ 1148 TimeToStopSentinelMinutFed_47Ch 63;
BA_ "GenSigStartValue" SG_ 1148 TimeToStopSentinelMinutFed_47Ch 62;
BA_ "GenSigSendType" SG_ 1148 TimeToStopSentinelMinutFed_47Ch 0;
BA_ "GenSigSendType" SG_ 1148 ReservationSentinelSts_Fed_47Ch 0;
BA_ "GenSigSendType" SG_ 1149 IMMO_Teach_VCC 1;
BA_ "GenSigSendType" SG_ 1150 ICC_BD_11_CRC 0;
BA_ "GenSigSendType" SG_ 1150 ICC_BD_11_RollgCntr 0;
BA_ "GenSigSendType" SG_ 1150 ICC_CPDDelaySwitchSet 2;
BA_ "GenSigSendType" SG_ 1150 ICC_PPMIDBSRBPASet 2;
BA_ "GenSigSendType" SG_ 1150 ICC_PPMIDHwSet 2;
BA_ "GenSigSendType" SG_ 1150 ICC_FLDoorButton 2;
BA_ "GenSigSendType" SG_ 1150 ICC_FRDoorButton 2;
BA_ "ASIL" SG_ 1150 ICC_DriveDrosinessLevel 1;
BA_ "GenSigSendType" SG_ 1150 ICC_DriveDrosinessLevel 0;
BA_ "GenSigSendType" SG_ 1150 ICC_RRDoorButton 2;
BA_ "GenSigSendType" SG_ 1150 ICC_RLDoorButton 2;
BA_ "GenSigSendType" SG_ 1150 ICC_CloseAllDoors 2;
BA_ "GenSigSendType" SG_ 1150 ICC_DoorRemoteKeyControlEnable 2;
BA_ "GenSigSendType" SG_ 1150 ICC_SetOpenAngle 2;
BA_ "GenSigSendType" SG_ 1150 ICC_CPDSwitchSet 2;
BA_ "GenSigSendType" SG_ 1150 ICC_FrontDoorPowerMode 2;
BA_ "GenSigSendType" SG_ 1150 ICC_RearDoorPowerMode 2;
BA_ "GenSigSendType" SG_ 1150 ICC_PedalCloseDriverDoorEnable 2;
BA_ "GenSigSendType" SG_ 1150 RR_Door_RearScreen_Control 2;
BA_ "GenSigSendType" SG_ 1150 ICC_RearDoorVoiceControlEnable 2;
BA_ "GenSigSendType" SG_ 1150 ICC_FLVoiceControl 2;
BA_ "GenSigSendType" SG_ 1150 ICC_FRVoiceControl 2;
BA_ "GenSigSendType" SG_ 1150 ICC_RRVoiceControl 2;
BA_ "GenSigSendType" SG_ 1150 ICC_RLVoiceControl 2;
BA_ "GenSigSendType" SG_ 1150 RL_Door_RearScreen_Control 2;
BA_ "GenSigSendType" SG_ 1151 VCC_Teach_IMMO 1;
BA_ "GenSigInvalidValue" SG_ 1152 TBOX_PetmodeSetTemperature 31;
BA_ "GenSigStartValue" SG_ 1152 TBOX_PetmodeSetTemperature 31;
BA_ "GenSigSendType" SG_ 1152 TBOX_PetmodeSetTemperature 2;
BA_ "GenSigSendType" SG_ 1155 ASU_3_horizontalSts 0;
BA_ "GenSigSendType" SG_ 1155 ASU_3_horizontalmodeFb 0;
BA_ "GenSigSendType" SG_ 1157 ICC_DA_15_CRC 0;
BA_ "GenSigSendType" SG_ 1157 ICC_DA_15_RollgCntr 0;
BA_ "GenSigSendType" SG_ 1157 ICC_DA_15_Resd 0;
BA_ "GenSigSendType" SG_ 1157 ICC_DA_15_BSDLCWSettingSt 2;
BA_ "GenSigSendType" SG_ 1157 ICC_DA_15_DOWSettingSt 2;
BA_ "GenSigSendType" SG_ 1157 ICC_DA_15_RCWSettingSt 2;
BA_ "GenSigStartValue" SG_ 1157 ICC_DA_15_RCTARCTBWarnType 3;
BA_ "GenSigSendType" SG_ 1157 ICC_DA_15_RCTARCTBWarnType 2;
BA_ "GenSigStartValue" SG_ 1157 ICC_DA_15_FCTAFCTBWarnType 3;
BA_ "GenSigSendType" SG_ 1157 ICC_DA_15_FCTAFCTBWarnType 2;
BA_ "GenSigSendType" SG_ 1157 ICC_DA_15_FrontPDCMuteSet 0;
BA_ "GenSigSendType" SG_ 1157 ICC_DA_15_FKPMuteSet 0;
BA_ "GenSigSendType" SG_ 1157 ICC_DA_15_ExtremeEnergySaveMode 0;
BA_ "GenSigSendType" SG_ 1157 Driver_AbnormalBehavior 0;
BA_ "ASIL" SG_ 1157 Dms_Status 2;
BA_ "GenSigSendType" SG_ 1157 Dms_Status 0;
BA_ "ASIL" SG_ 1157 Driver_EyeOnRoad 2;
BA_ "GenSigSendType" SG_ 1157 Driver_EyeOnRoad 0;
BA_ "GenSigSendType" SG_ 1157 ICC_IHCfunctionSw 2;
BA_ "ASIL" SG_ 1157 Dms_DriverPresence 1;
BA_ "GenSigSendType" SG_ 1157 Dms_DriverPresence 0;
BA_ "GenSigSendType" SG_ 1157 Driver_GazeRegion 0;
VAL_ 1028 PEPS_WelcomeON 0 "Default_value" 1 "Welcome_light_OFF" 2 "Welcome_light_ON" 3 "Reserved" ;
VAL_ 1028 PEPS_VehicleSearchReq 0 "No_Request" 1 "Request" 2 "Reseved" 3 "Reseved" ;
VAL_ 1028 PEPS_SATOReminder 0 "No_Command" 1 "Remind_stop" 2 "Remind_start" 3 "Reseved" ;
VAL_ 1028 PEPS_PLGUnlockReq 0 "Not_Request" 1 "Request" 2 "Reseved" 3 "Reseved" ;
VAL_ 1028 PEPS_RKETrunkSts 0 "Not_Active" 1 "Long_Press" 2 "Short_Press" 3 "Not_Used" ;
VAL_ 1028 PEPS_SSBInhibitCWCSts 0 "Default" 1 "Disable" 2 "Reseved" 3 "Reseved" ;
VAL_ 1028 PEPS_WirelessChargingCtrSts 0 "Default" 1 "Disable" 2 "Reseved" 3 "Reseved" ;
VAL_ 1028 PEPS_EmgyShutdown 0 "No_Happen" 1 "Happen" 2 "Reseved" 3 "Reseved" ;
VAL_ 1028 PEPS_SSBInputFailure 0 "Not_Fail" 1 "Fail" 2 "Reseved" 3 "Reseved" ;
VAL_ 1028 PEPS_SmartSystemWarning1_1 0 "Normal" 1 "Identifier_is_out_of_vehicle" 2 "Reseved" 3 "Reseved" ;
VAL_ 1028 PEPS_SmartSystemWarning2_2 0 "Normal" 1 "Identifier_is_out_of_vehicle_range_when_vehicle_starts_running" 2 "Reseved" 3 "Reseved" ;
VAL_ 1028 PEPS_SmartSystemWarning3_1 0 "Normal" 1 "Identifier_low_battery_detected" 2 "Reseved" 3 "Reseved" ;
VAL_ 1028 PEPS_SmartSystemWarning3_2 0 "Normal" 1 "Engine_start_not_possible_if_gear_box_not_in_P_or_N_position" 2 "Reseved" 3 "Reseved" ;
VAL_ 1028 PEPS_SmartSystemWarning4_2 0 "Normal" 1 "Engine_start_attempted_without_pressing_clutch/brake_pedal" 2 "Reseved" 3 "Reseved" ;
VAL_ 1028 PEPS_SmartSystemWarning4_3 0 "Normal" 1 "Switching_OFF_while_Gear_box_not_in_P_position" 2 "Reseved" 3 "Reseved" ;
VAL_ 1028 PEPS_SystemWarning 0 "Normal" 1 "Fault" 2 "Reseved" 3 "Reseved" ;
VAL_ 1028 PEPS_BLTKeyPESts 0 "OFF" 1 "ON" 2 "Reseved" 3 "Reseved" ;
VAL_ 1030 RearViewFoldSts 0 "invalid" 1 "Fold" 2 "unFold" ;
VAL_ 1030 FLZCU_AlrmSts 0 "Not active" 1 "Arming Mode" 2 "Pre_rearming Mode" 3 "Trunk Opening Mode" 4 "Alarm Mode" 5 "Disarm Mode" 6 "Arming Fault Mode" 7 "reserved" ;
VAL_ 1030 FLZCU_SteeringMode 0 "Not Active" 1 "Normal" 2 "Sport" ;
VAL_ 1030 FLZCU_OBDDiagOccupy 0 "Not Occupy" 1 "Occupy" ;
VAL_ 1034 HCU_PowerModeFed 0 "Not Active" 1 "EV" 2 "HEV" 3 "EV+" ;
VAL_ 1034 HCU_PowertrainFault 0 "No Fault" 1 "Fault" ;
VAL_ 1034 HCU_PowerModeChangeFail 0 "NOT FAIL" 1 "FAIL" ;
VAL_ 1034 HCU_ChargingSts 0 "No Charging" 1 "Stop Charging" 2 "Run Charging" 3 "Charge Complete" ;
VAL_ 1035 VCC_1_OTASts 0 "Normal Status" 1 "OTA Status" ;
VAL_ 1035 VCC_1_DriveMode 0 "Not Active" 1 "ECO" 2 "Normal" 3 "Sport" 4 "Snow" 5 "Off Road" 6 "Individual" 7 "Energy-saving hybrid" 8 "Sand" 9 "AI" 10 "Wade" 11 "Rock" 12 "Mud" 13 "Smart" ;
VAL_ 1037 ADS_FCTAWarn_Right 0 "No Warning" 1 "Warning" ;
VAL_ 1037 ADS_FCTAWarn_Left 0 "No Warning" 1 "Warning" ;
VAL_ 1037 ADS_RCTAWarn_Rigth 0 "No Warning" 1 "Warning" ;
VAL_ 1037 ADS_RCTAWarn_Left 0 "No Warning" 1 "Warning" ;
VAL_ 1037 ADAS_enum_AESSts_40Dh 0 "None" 1 "On" 2 "Off" 3 "Failure" ;
VAL_ 1037 ADAS_enum_AudibleBeepRate_40Dh 0 "Off_Startup" 1 "On" 2 "4Hz" 3 "2Hz" 4 "1Hz" ;
VAL_ 1037 ADAS_enum_FCTASettingStsFb_40Dh 0 "None" 1 "Warning_only" 2 "Warning_and_Brake" 3 "Off" 4 "Failure" ;
VAL_ 1037 ADAS_enum_RadarWorkSts_40Dh 0 "Not_Active_Startup" 1 "Active" ;
VAL_ 1037 ADAS_enum_PasSwitch_40Dh 0 "Switch_Off_Startup" 1 "Switch_On" ;
VAL_ 1037 ADAS_enum_MEBSts_40Dh 0 "None" 1 "ON" 2 "Off" 3 "failure" ;
VAL_ 1037 ADAS_enum_MAASts_40Dh 0 "None" 1 "ON" 2 "Off" 3 "Failure" ;
VAL_ 1037 IHU_11_VoiceplayModeSwtSet_40Dh 0 "Not_Active" 1 "Concise" 2 "Detail" 3 "Not_Used" ;
VAL_ 1037 IHU_11_LightingBlueSwtSet_40Dh 0 "Not_active" 1 "ON" 2 "OFF" 3 "Reserved" ;
VAL_ 1037 enum_CECULVDSOutputStatus_40Dh 0 "No_Output" 1 "Output" ;
VAL_ 1041 ADS_RadarWarning2AcLvl_411h 0 "no request" 1 "Level 1" 2 "Level 2" 3 "Level 3" 4 "Level 4" 5 "Level 5" 7 "Invalid" ;
VAL_ 1041 ADS_RadarWarning1AcLvl_411h 0 "no request" 1 "Level 1" 2 "Level 2" 3 "Level 3" 4 "Level 4" 5 "Level 5" 7 "Invalid" ;
VAL_ 1041 ADS_RadarWarning0AcLvl_411h 0 "no request" 1 "Level 1" 2 "Level 2" 3 "Level 3" 4 "Level 4" 5 "Level 5" 7 "Invalid" ;
VAL_ 1041 ADS_RadarWarning4AcLvl_411h 0 "no request" 1 "Level 1" 2 "Level 2" 3 "Level 3" 4 "Level 4" 5 "Level 5" 7 "Invalid" ;
VAL_ 1041 ADS_RadarWarning3AcLvl_411h 0 "no request" 1 "Level 1" 2 "Level 2" 3 "Level 3" 4 "Level 4" 5 "Level 5" 7 "Invalid" ;
VAL_ 1041 ADS_RadarWarning7AcLvl_411h 0 "no request" 1 "Level 1" 2 "Level 2" 3 "Level 3" 4 "Level 4" 5 "Level 5" 7 "Invalid" ;
VAL_ 1041 ADS_RadarWarning6AcLvl_411h 0 "no request" 1 "Level 1" 2 "Level 2" 3 "Level 3" 4 "Level 4" 5 "Level 5" 7 "Invalid" ;
VAL_ 1041 ADS_RadarWarning5AcLvl_411h 0 "no request" 1 "Level 1" 2 "Level 2" 3 "Level 3" 4 "Level 4" 5 "Level 5" 7 "Invalid" ;
VAL_ 1041 ADS_RadarWarning10AcLvl_411h 0 "no request" 1 "Level 1" 2 "Level 2" 3 "Level 3" 4 "Level 4" 5 "Level 5" 7 "Invalid" ;
VAL_ 1041 ADS_RadarWarning9AcLvl_411h 0 "no request" 1 "Level 1" 2 "Level 2" 3 "Level 3" 4 "Level 4" 5 "Level 5" 7 "Invalid" ;
VAL_ 1041 ADS_RadarWarning8AcLvl_411h 0 "no request" 1 "Level 1" 2 "Level 2" 3 "Level 3" 4 "Level 4" 5 "Level 5" 7 "Invalid" ;
VAL_ 1041 ADS_RadarWarning12AcLvl_411h 0 "no request" 1 "Level 1" 2 "Level 2" 3 "Level 3" 4 "Level 4" 5 "Level 5" 7 "Invalid" ;
VAL_ 1041 ADS_RadarWarning11AcLvl_411h 0 "no request" 1 "Level 1" 2 "Level 2" 3 "Level 3" 4 "Level 4" 5 "Level 5" 7 "Invalid" ;
VAL_ 1041 ADS_RadarWarning15AcLvl_411h 0 "no request" 1 "Level 1" 2 "Level 2" 3 "Level 3" 4 "Level 4" 5 "Level 5" 7 "Invalid" ;
VAL_ 1041 ADS_RadarWarning14AcLvl_411h 0 "no request" 1 "Level 1" 2 "Level 2" 3 "Level 3" 4 "Level 4" 5 "Level 5" 7 "Invalid" ;
VAL_ 1041 ADS_RadarWarning13AcLvl_411h 0 "no request" 1 "Level 1" 2 "Level 2" 3 "Level 3" 4 "Level 4" 5 "Level 5" 7 "Invalid" ;
VAL_ 1041 ADC_MdcSentryAlarmMod_411h 0 "无告警" 1 "警报" ;
VAL_ 1041 ADC_FuncReq_SentryModDetec_411h 0 "OFF" 1 "哨兵模式维持" ;
VAL_ 1041 ADC_FuncReq_SentryModWarn_411h 0 "OFF" 1 "哨兵模式唤醒" ;
VAL_ 1042 ADS_RiFrntDowWarning_412h 0 "无请求" 1 "常亮" 2 "闪烁" 3 "reserved" ;
VAL_ 1042 ADS_LeFrntDowWarning_412h 0 "无请求" 1 "常亮" 2 "闪烁" 3 "reserved" ;
VAL_ 1042 ADS_AutoLightSwCtrl_412h 0 "无请求" 1 "POSITION_LIGHT" 2 "LOW_BEAM" 3 "AUTO_MODE" ;
VAL_ 1042 ADS_BrkBeamReq_412h 0 "无请求" 1 "ON" ;
VAL_ 1042 ADS_RightMirrWarningCmd_412h 0 "无请求" 1 "Level（常亮）" 2 "Level (闪烁）" 3 "resversed" ;
VAL_ 1042 ADS_LeftMirrWarningCmd_412h 0 "无请求" 1 "Level（常亮）" 2 "Level (闪烁）" 3 "resversed" ;
VAL_ 1042 ADS_RiReDowWarning_412h 0 "无请求" 1 "常亮" 2 "闪烁" 3 "reserved" ;
VAL_ 1042 ADS_LeReDowWarning_412h 0 "无请求" 1 "常亮" 2 "闪烁" 3 "reserved" ;
VAL_ 1042 ADS_WshrReq_412h 0 "无请求" 1 "有请求" ;
VAL_ 1042 ADS_SBeltControl_412h 0 "No Request" 1 "Shake" 2 "Tied level 1" 3 "Tied level 2 （预留）" 4 "reserved" 5 "reserved" 6 "reserved" 7 "reserved" ;
VAL_ 1042 ADS_DoorLockReq_412h 0 "Not Request 无请求" 1 "UnLock 解锁请求" 2 "Lock 上锁请求" 3 "reserved" ;
VAL_ 1042 ADS_ReMirrReq_412h 0 "Not Request" 1 "展开" 2 "折叠" 3 "Not used" ;
VAL_ 1042 ADS_LeFmtWinCtrl_412h 0 "无请求" 1 "关闭" 2 "打开" 3 "resevered" ;
VAL_ 1042 ADS_HornReq_412h 0 "无请求" 1 "哨兵模式喇叭请求" 2 "巡航功能喇叭请求" 3 "resevered" ;
VAL_ 1042 ADS_FrtWindshildHeatReq_412h 0 "无请求" 1 "有请求" 2 "reserved" 3 "reserved" ;
VAL_ 1042 ADS_SeatShakeControl_412h 0 "No Request" 1 "Shake" 2 "reserved" 3 "reserved" ;
VAL_ 1042 ADS_TopWinCtrl_412h 0 "无请求" 1 "关闭" 2 "打开" 3 "resevered" ;
VAL_ 1042 ADS_RiReWinCtrl_412h 0 "无请求" 1 "关闭" 2 "打开" 3 "resevered" ;
VAL_ 1042 ADS_LeReWinCtrl_412h 0 "无请求" 1 "关闭" 2 "打开" 3 "resevered" ;
VAL_ 1042 ADS_RiFmtWinCtrl_412h 0 "无请求" 1 "关闭" 2 "打开" 3 "resevered" ;
VAL_ 1042 ADS_MdcCrtSts_412h 0 "DeepSleep深度睡眠状态" 1 "LightSleep浅睡眠状态" 2 "Active激活状态" 3 "PartialActive半激活状态" 4 "Reserved" 5 "Reserved" 6 "Reserved" 7 "Invalid" ;
VAL_ 1042 ADAS_FctSts_412h 0 "Off" 1 "On" ;
VAL_ 1042 ADS_ChargingPortCmd_412h 0 "no request" 1 "OFF" 2 "ON" 3 "Reversed" ;
VAL_ 1042 ADS_FrontWiperReq_412h 0 "无请求" 1 "有请求" ;
VAL_ 1042 ADS_PwrOnOffReq_412h 0 "no request" 1 "Power on 上电（从OFF至整车Ready状态）" 2 "Power off 下电（KL15 OFF)" 3 "上Ready（等同于过动力防盗）" 4 "下Ready（等同于退动力防盗，需维持高压）" 5 "reserved" 6 "reserved" 7 "reserved" ;
VAL_ 1042 ADS_FlowReq_412h 0 "0.0L/min" 1 "0.25L/min" 2 "0.5L/min" 3 "0.75L/min" 4 "1.0L/min" 5 "1.25L/min" 6 "1.5L/min" 7 "1.75L/min" 8 "2.00L/min" 9 "2.25L/min" 10 "2.5L/min" 11 "2.75L/min" 12 "3.0L/min" 13 "3.25L/min" ;
VAL_ 1042 ADS_ThmPostRun_412h 0 "No Request" 1 "Request" ;
VAL_ 1042 ADS_HVCtrlReq_412h 0 "No Request" 1 "Request" ;
VAL_ 1042 ADS_HiBeamReq_412h 0 "No Request" 1 "Request" ;
VAL_ 1042 ADS_HMAStatus_412h 0 "Off" 1 "Standby" 2 "Active" 3 "Failure" ;
VAL_ 1042 ADS_hmaOnOffSts_412h 0 "Initial" 1 "OFF" 2 "ON" 3 "INVALID" ;
VAL_ 1044 HCU_EnergyFlow 0 "OFF" 1 "Ready" 2 "2WD_EV" 3 "4WD_EV" 4 "2WD_ExtendRangeDisCharge" 5 "2WD_ExtendRangeCharge" 6 "4WD_ExtendRangeDisCharge" 7 "4WD_ExtendRangeCharge" 8 "2WD_Parallel" 9 "4WD_Parallel" 10 "Engine" 11 "Running_Generate" 12 "Parking_Generate" 13 "2WD_ReGenerateBrake" 14 "4WD_ReGenerateBrake" 15 "Charge" ;
VAL_ 1044 HCU_SetSOCFed 255 "Invalid" ;
VAL_ 1044 HCU_2_G_LowBatteryInfo 0 "Not Active" 1 "NoRequest" 2 "Request" 3 "Sail Request" ;
VAL_ 1046 LBMS_LoWSocFlt 0 "No Remind" 1 "Low Power Remind" 2 "Level 2 fault" 3 "Level 3 fault" 4 "Reserved" 5 "Reserved" 6 "Reserved" 7 "Reserved" 8 "Reserved" 9 "Reserved" 10 "Reserved" 11 "Reserved" 12 "Reserved" 13 "Reserved" 14 "Reserved" 15 "Reserved" ;
VAL_ 1046 LBMS_EndLifeFlt 0 "No Active" 1 "Active" ;
VAL_ 1046 LBMS_SysFlt 0 "No Active" 1 "Active" ;
VAL_ 1046 LBMS_ThermRunawayFlt 0 "No Active" 1 "Active" ;
VAL_ 1046 LBMS_LowPowerRemind 0 "No Remind" 1 "Low Power Remind" 2 "Level 2 fault" 3 "Level 3 fault" 4 "Reserved" 5 "Reserved" 6 "Reserved" 7 "Reserved" 8 "Reserved" 9 "Reserved" 10 "Reserved" 11 "Reserved" 12 "Reserved" 13 "Reserved" 14 "Reserved" 15 "Reserved" ;
VAL_ 1056 ICC_DSBH_HeatReq 0 "NotActive" 1 "No Heat Request" 2 "Heat Request" 3 "Reserved" ;
VAL_ 1056 ICC_DSBH_SetTemp 0 "NotActive" ;
VAL_ 1056 ICC_PSBH_HeatReq 0 "NotActive" 1 "No Heat Request" 2 "Heat Request" 3 "Reserved" ;
VAL_ 1056 ICC_PSBH_SetTemp 0 "NotActive" ;
VAL_ 1057 VCU_shfChk 0 "LampOff" 1 "LampON" ;
VAL_ 1057 VCU_TowingMode 0 "NotActive" 1 "Active" 2 "Reserved" ;
VAL_ 1057 VCU_EngyConsuPer50Km 4095 "Invalid" ;
VAL_ 1057 VCU_BookChrgSetFailRes 0 "Default" 1 "OBC Fault" 2 "HvBatt Fault" 3 "DCDC Fault" 4 "Vehicle Fault" 5 "Reserved" 6 "Reserved" 7 "Reserved" ;
VAL_ 1057 VCU_BookChrgFailRes 0 "Default" 1 "OBC Fault" 2 "HvBatt Fault" 3 "DCDC Fault" 4 "Vehicle Fault" 5 "ChargeStationFault" 6 "BNCMfault" 7 "EVSEandBNCMConnectFault" 8 "Reserved" ;
VAL_ 1057 VCU_BookChrgStsFb 0 "Default" 1 "Charging" 2 "ChargeFinished" 3 "Reserved" ;
VAL_ 1057 HCU_EngineSelfMaintain 0 "Not Active" 1 "Active" 2 "Reserved" 3 "Reserved" ;
VAL_ 1059 DrvSeatHeatLevelCmdvelCmd_423h 0 "Not_Active" 1 "OFF" 2 "Seat_heating_Level1" 3 "Seat_heating_Level2" 4 "Seat_heating_Level3" 5 "Reserved" 6 "Reserved" 7 "Reserved" ;
VAL_ 1059 ICC_FRSeatHeatLevelCmd 0 "Not_Active" 1 "OFF" 2 "Seat_heating_Level1" 3 "Seat_heating_Level2" 4 "Seat_heating_Level3" 5 "Reserved" 6 "Reserved" 7 "Reserved" ;
VAL_ 1059 ICC_TrunkSW 0 "Not_Active" 1 "ON" 2 "OFF" 3 "Reserved" ;
VAL_ 1059 ICC_RRSeatHeatLevelCmd 0 "Not_active" 1 "OFF" 2 "Seat_heating_Level1" 3 "Seat_heating_Level2" 4 "Seat_heating_Level3" 5 "Reserved" 6 "Reserved" 7 "Reserved" ;
VAL_ 1059 DrvSecSeatHeatLevelCmd_423h 0 "Not_active" 1 "OFF" 2 "Seat_heating_Level1" 3 "Seat_heating_Level2" 4 "Seat_heating_Level3" 5 "Reserved" 6 "Reserved" 7 "Reserved" ;
VAL_ 1059 ICC_FRSeatVentLevelCmd 0 "Not_Active" 1 "OFF" 2 "Seat_Ventilation_Level1" 3 "Seat_Ventilation_Level2" 4 "Seat_Ventilation_Level3" 5 "Reserved" 6 "Reserved" 7 "Reserved" ;
VAL_ 1059 DrvSeatVentLevelCmd_423h 0 "Not_Active" 1 "OFF" 2 "Seat_Ventilation_Level1" 3 "Seat_Ventilation_Level2" 4 "Seat_Ventilation_Level3" 5 "Reserved" 6 "Reserved" 7 "Reserved" ;
VAL_ 1059 ICC_FrontWiperMaintenanceMode 0 "Not_Active" 1 "ON" 2 "OFF" ;
VAL_ 1059 ICC_RRSeatVentLevelCmd 0 "Not_Active" 1 "OFF" 2 "Seat_Ventilation_Level1" 3 "Seat_Ventilation_Level2" 4 "Seat_Ventilation_Level3" 5 "Reserved" 6 "Reserved" 7 "Reserved" ;
VAL_ 1059 DrvSecSeatVentLevelCmd_423h 0 "Not_Active" 1 "OFF" 2 "Seat_Ventilation_Level1" 3 "Seat_Ventilation_Level2" 4 "Seat_Ventilation_Level3" 5 "Reserved" 6 "Reserved" 7 "Reserved" ;
VAL_ 1059 PLG_ControlReq_423h 0 "Invalid_Default" 1 "Open_Close" 2 "Stop" ;
VAL_ 1059 ICC_RearWiperMaintenanceMode 0 "Not_Active" 1 "ON" 2 "OFF" ;
VAL_ 1060 InforDisplay_424h 0 "No_display" 1 "Pressed_unlock_button" 2 "Pressed_brake_pedal" 3 "Positon_P_only_at_stop" 4 "Speed_too_high_can't_shift" 5 "Please_put_the_gearshift_dial_back_to_the_righ" 6 "Shift_to_or_out_Gear_P_with_Engine_Start" 7 "Pengagementmalfunction" ;
VAL_ 1061 DriverSeatMsgStr_LvlSts 0 "OFF/Intial" 1 "Low" 2 "Middle" 3 "High" 4 "Reserved" 5 "Reserved" 6 "Reserved" 7 "Reserved" ;
VAL_ 1061 DriverSeatMsg_ModeSts 0 "NotActive" 1 "PulseMode" 2 "WaveMode" 3 "CatPawMode" 4 "SigleRowMode" 5 "CrossMode" 6 "ButterflyMode" 7 "WaistMode" 8 "SnakeMode" 9 "Special 1" 10 "Special 2" 11 "Special 3" 12 "Special 4" ;
VAL_ 1061 Drv_Seat_ActvBolster_MdSts 0 "Not Active" 1 "Off" 2 "Normal" 3 "Sensitive" ;
VAL_ 1061 Drv_Seat_LBolster_Sts 0 "NotActive" 1 "Inflate" 2 "Deflate" 3 "Error" ;
VAL_ 1061 Drv_Seat_RBolster_Sts 0 "NotActive" 1 "Inflate" 2 "Deflate" 3 "Error" ;
VAL_ 1063 TBOX_PetmodeSwitch 0 "Not Active" 1 "ON" 2 "OFF" 3 "Reserved" ;
VAL_ 1063 TBOX_SentinelModeSw 0 "Not Active" 1 "ON" 2 "OFF" ;
VAL_ 1063 TBOX_ElectronicFenceReq_427h 0 "Not Active" 1 "ON" 2 "OFF" 3 "Reserved" ;
VAL_ 1065 LeftSeatMsgStr_LvlSts 0 "OFF/Intial" 1 "Low" 2 "Middle" 3 "High" 4 "Reserved" 5 "Reserved" 6 "Reserved" 7 "Reserved" ;
VAL_ 1065 LeftSeatMsg_ModeSts 0 "NotActive" 1 "PulseMode" 2 "WaveMode" 3 "CatPawMode" 4 "SigleRowMode" 5 "CrossMode" 6 "ButterflyMode" 7 "WaistMode" 8 "SnakeMode" 9 "Special 1" 10 "Special 2" 11 "Special 3" 12 "Special 4" ;
VAL_ 1069 PassSeatMsgStr_LvlSts 0 "OFF/Intial" 1 "Low" 2 "Middle" 3 "High" 4 "Reserved" 5 "Reserved" 6 "Reserved" 7 "Reserved" ;
VAL_ 1069 PassSeatMsg_ModeSts 0 "NotActive" 1 "PulseMode" 2 "WaveMode" 3 "CatPawMode" 4 "SigleRowMode" 5 "CrossMode" 6 "ButterflyMode" 7 "WaistMode" 8 "SnakeMode" 9 "Special 1" 10 "Special 2" 11 "Special 3" 12 "Special 4" ;
VAL_ 1070 ChargingSts_42Eh 0 "No charging" 1 "Charging" 2 "Charging completed" 3 "Charging fault" ;
VAL_ 1070 WorkingSts_42Eh 0 "CWCR OFF" 1 "CWCR ON" ;
VAL_ 1070 Phoneforgotten_42Eh 0 "phone not forgotten" 1 "phone forgotten" ;
VAL_ 1070 PhoneforgottenONOFFSts_42Eh 0 "Function OFF" 1 "Function ON" ;
VAL_ 1070 ChrgFlt_42Eh 0 "Not active" 1 "Low_Volf" 2 "High_Volf" 3 "High_Temp" 4 "Foreign_matter_detected" 5 "Reserved" 6 "Reserved" 7 "Reserved" ;
VAL_ 1070 ChargingSts_R_42Eh 0 "No charging" 1 "Charging" 2 "Charging completed" 3 "Charging fault" ;
VAL_ 1070 WorkingSts_R_42Eh 0 "CWCR OFF" 1 "CWCR ON" ;
VAL_ 1070 Phoneforgotten_R_42Eh 0 "phone not forgotten" 1 "phone forgotten" ;
VAL_ 1070 PhoneforgottenONOFFStsR_42Eh 0 "Function OFF" 1 "Function ON" ;
VAL_ 1070 ChrgFlt_R_42Eh 0 "Not active" 1 "Low_Volf" 2 "High_Volf" 3 "High_Temp" 4 "Foreign_matter_detected_R" 5 "Reserved" 6 "Reserved" 7 "Reserved" ;
VAL_ 1071 FLZCU_CarSearhSetSW 0 "Not Active" 1 "Only Lighting" 2 "Sound and Lighting" 3 "Only Sound" ;
VAL_ 1071 FLZCU_AutoFoldSts 0 "Not autofold mode" 1 "Autofold mode" ;
VAL_ 1071 FLZCU_AutolockSts 0 "Not autolock mode" 1 "Autolock mode" ;
VAL_ 1071 FLZCU_FGHeat_Req_CmdFeedback 0 "Off" 1 "On" ;
VAL_ 1071 FLZCU_WindowInhibitSts 0 "Permit" 1 "Inhibit" ;
VAL_ 1071 FLZCU_AutoReadLightSts 0 "Close" 1 "Open" ;
VAL_ 1071 FLZCU_HeatingSW 0 "Off" 1 "On" ;
VAL_ 1071 FLZCU_AutoHeatingFb 0 "Close" 1 "Open" ;
VAL_ 1071 FLZCU_SteerNeedMemory 0 "NO Request" 1 "Request" ;
VAL_ 1071 FLZCU_LowBeamFaults 0 "Not Faults" 1 "Faults" ;
VAL_ 1071 FLZCU_RearNeedMemory 0 "NO Request" 1 "Request" ;
VAL_ 1071 FLZCU_BrkLightFaults 0 "Not Faults" 1 "Faults" ;
VAL_ 1071 FLZCU_TurnLiSwtSts 0 "OFF" 1 "turn left" 2 "turn right" 3 "left change" 4 "right change" 5 "Reserved" 6 "Reserved" 7 "fault" ;
VAL_ 1071 DrvHandleFoldedSts_42Fh 0 "Fold" 1 "Unfold" 2 "Unknown" 3 "Reserved" ;
VAL_ 1071 DrvRearHandleFoldedSts_42Fh 0 "Fold" 1 "Unfold" 2 "Unknown" 3 "Reserved" ;
VAL_ 1071 PassHandleFoldedSts_42Fh 0 "Fold" 1 "Unfold" 2 "Unknown" 3 "Reserved" ;
VAL_ 1071 PassRearHandleFoldedSts_42Fh 0 "Fold" 1 "Unfold" 2 "Unknown" 3 "Reserved" ;
VAL_ 1071 FLZCU_RvsExtMirrFbSts 0 "OFF" 1 "Only Right Side" 2 "Only Left Side" 3 "Both Sides" ;
VAL_ 1071 FLZCU_LightMainSwitchSts 0 "Not active" 1 "Off Position" 2 "Auto Position" 3 "PositionLampSwitch Position" 4 "LowBeamSwitch Position" 5 "Reserved" 6 "Reserved" 7 "Reserved" ;
VAL_ 1071 FLZCU_BeamDelaySts 0 "Not Active" 1 "0s" 2 "10s" 3 "20s" 4 "30s" 5 "60s" 6 "Reserved" 7 "Reserved" ;
VAL_ 1071 FLZCU_LowBeamHighSts 0 "Level 0" 1 "Level 1" 2 "Level 2" 3 "Level 3" 4 "Reserved" 5 "Reserved" 6 "Reserved" 7 "Reserved" ;
VAL_ 1071 FLZCU_WipeSensitivitySts 0 "Not Active" 1 "Level 1" 2 "Level 2" 3 "Level 3" 4 "Level 4" 5 "Reserved" 6 "Reserved" 7 "Reserved" ;
VAL_ 1071 FLZCU_WipeMaintenanceSWSts 0 "Not Active" 1 "Front Wiper" 2 "Rear Wiper" 3 "Both Wiper" ;
VAL_ 1071 FLZCU_HiBeamSwtSts 0 "reserved" 1 "high beam" 2 "flash" 3 "fault" ;
VAL_ 1071 FLZCU_ImmoRequest 0 "no Request" 1 "Request" 2 "BNCM Request" 3 "OTA Request" 4 "TBOX Request" 5 "RMCU Request" 6 "Reserved" 7 "Reserved" ;
VAL_ 1071 FLZCU_AlarmWarnSetSW 0 "Not Active" 1 "OFF" 2 "Only Lighting" 3 "Sound and Lighting" ;
VAL_ 1071 FLZCU_CleanModeStatus 0 "Not active" 1 "OFF" 2 "ON" 3 "Reserved" ;
VAL_ 1071 DrvReleaseLockSts_42Fh 0 "None" 1 "Releasing" 2 "Released" 3 "Reset" 4 "Resetting" 5 "Reserved" 6 "Reserved" 7 "Reserved" ;
VAL_ 1071 FLZCU_RearFogLightSts 0 "OFF" 1 "ON" ;
VAL_ 1071 PassFoglightSts_42Fh 0 "OFF" 1 "ON" ;
VAL_ 1071 DrvFoglightSts_42Fh 0 "OFF" 1 "ON" ;
VAL_ 1071 FLZCU_RearFogLightFaults 0 "Not Faults" 1 "Faults" ;
VAL_ 1071 FLZCU_HighBeamFaults 0 "Not Faults" 1 "Faults" ;
VAL_ 1071 FLZCU_HighBeamSts 0 "Close" 1 "Open" ;
VAL_ 1071 FLZCU_LowBeamSts 0 "Close" 1 "Open" ;
VAL_ 1071 FLZCU_ParkUnlockEnableFb 0 "Disable" 1 "Enable" ;
VAL_ 1071 DrvRearReleaseLockSts_42Fh 0 "None" 1 "Releasing" 2 "Released" 3 "Reset" 4 "Resetting" 5 "Reserved" 6 "Reserved" 7 "Reserved" ;
VAL_ 1071 FLZCU_EasyEntryExitFb 0 "Not Active" 1 "ON" 2 "OFF" 3 "Not Used" ;
VAL_ 1071 FLZCU_EmgyLiSwtSts 0 "No Pressed" 1 "Pressed ON" ;
VAL_ 1071 FLZCU_HMASwSts 0 "Not active" 1 "Active" ;
VAL_ 1071 FLZCU_DaytimeLight 0 "None" 1 "Left" 2 "Right" 3 "Both" ;
VAL_ 1071 FLZCU_FGHeatFaults 0 "Not Faults" 1 "Faults" ;
VAL_ 1071 FLZCU_ParkLightFaults 0 "Not Faults" 1 "Faults" ;
VAL_ 1071 FLZCU_LbatipVehPwrMod 0 "No warning" 1 "Warning" ;
VAL_ 1071 FLZCU_HMASwSts_MDC 0 "OFF" 1 "Standby" 2 "Active" 3 "Failure" ;
VAL_ 1071 FLZCU_LVPowICDsp 0 "Normal" 1 "ChargeFault" 2 "LVBatFaultSt" 3 "BatteryVoltLow" 4 "Reserved" 5 "Reserved" 6 "Reserved" 7 "Reserved" ;
VAL_ 1071 FLZCU_LockCarWinCloseFb 0 "Enable" 1 "Disable" ;
VAL_ 1071 FLZCU_BrkLightSts 0 "Close" 1 "Open" ;
VAL_ 1071 FLZCU_ReverseLightSts 0 "Close" 1 "Open" ;
VAL_ 1071 FLZCU_LowWashLqdWarning 0 "Not Warning" 1 "Warning" ;
VAL_ 1071 FLZCU_SteerWheelHeatingFb 0 "Not Active" 1 "Level1" 2 "Level2" 3 "Level3" 4 "OFF" ;
VAL_ 1071 FLZCU_FrontFogLightSts 0 "OFF" 1 "ON" ;
VAL_ 1071 FLZCU_NapAreaFb 0 "Not Active" 1 "Front Left" 2 "Front Right" 3 "Front Left and Right" ;
VAL_ 1071 FLZCU_NapAlarmStatus 0 "OFF" 1 "ON" ;
VAL_ 1071 FLZCU_NapFailCause 0 "Not_Active" 1 "Gear_Not_P" 2 "Vehicle_Speed≠0km/h" 3 "Hood_Unlock" 4 "Trunk_Unlock" 5 "FLDoor_Unlock" 6 "FRDoor_Unlock" 7 "RLDoor_Unlock" 8 "RRDoor_Unlock" 9 "Low_Voltage_Battery_Voltage_Low" 10 "High_Voltage_Battery_Low" 11 "Brake_Pedal_Depressed" 12 "PowerMode Not Comfortable" ;
VAL_ 1071 FLZCU_NapStatusFb 0 "OFF" 1 "ON" ;
VAL_ 1071 FLZCU_CleanModeFailCause 0 "Not Fail" 1 "Fail" ;
VAL_ 1071 LockCarSunRoofShadeCloseFb 0 "Not Active" 1 "Enable" 2 "Disable" 3 "reserved" ;
VAL_ 1071 FLZCU_NapClosePrompt 0 "Not Active" 1 "Low Voltage Battery Low" 2 "High Voltage Battery Low" ;
VAL_ 1071 FLZCU_AutoWipingInhibit 0 "Not Inhibit" 1 "Inhibit" ;
VAL_ 1071 FLZCU_RemoteUnlockFb 0 "Not Active" 1 "Drivedoor_Unlock" 2 "Fourdoor_Unlock" 3 "reserved" ;
VAL_ 1071 FLZCU_FrntWiprSwSts 0 "OFF" 1 "Auto1" 2 "Auto2" 3 "Auto3" 4 "Auto4" 5 "Low" 6 "High" 7 "Mist" 8 "reserved" 9 "reserved" 10 "reserved" 11 "reserved" 12 "reserved" 13 "reserved" 14 "reserved" 15 "reserved" ;
VAL_ 1071 TurnLightFaults_42Fh 0 "Not Faults" 1 "Faults" ;
VAL_ 1071 FLZCU_HazardLightSWSts_42Fh 0 "OFF" 1 "ON" ;
VAL_ 1071 DrvRearWinSts_42Fh 0 "Not Active" 1 "Comfort" 2 "Close" 3 "Open" 4 "Other Position" 5 "Closing" 6 "Opening" 7 "Reserved" ;
VAL_ 1071 DrvWinSts_42Fh 0 "Not Active" 1 "Comfort" 2 "Close" 3 "Open" 4 "Other Position" 5 "Closing" 6 "Opening" 7 "Reserved" ;
VAL_ 1071 FLZCU_DaytimeLightFaults 0 "Not Faults" 1 "Faults" ;
VAL_ 1071 FLZCU_FrontFogLightFaults 0 "Not Faults" 1 "Faults" ;
VAL_ 1071 FLZCU_HomeLinkWelLightSetSts 0 "OFF" 1 "ON" ;
VAL_ 1071 FLZCU_HomeLinkArmHornSetSts 0 "OFF" 1 "ON" ;
VAL_ 1071 FLZCU_UIROpenStas 0 "OFF" 1 "ON" ;
VAL_ 1071 FLZCU_WALOpenStas 0 "OFF" 1 "ON" ;
VAL_ 1071 FLZCU_WelcomeOpenStas 0 "OFF" 1 "ON" ;
VAL_ 1071 FLZCU_RearWiprSwSts_42Fh 0 "OFF" 1 "Low" 2 "Wash" 3 "Reserved" ;
VAL_ 1071 FLZCU_ExtLiSwtClsSts 0 "Not Active" 1 "OFF" 2 "ON" 3 "Reserved" ;
VAL_ 1072 AutoSeatHeatLevelsFb_430h 0 "Not Active" 1 "ON" 2 "OFF" 3 "Reserved" ;
VAL_ 1072 AutoSteerWhlHeatFb_430h 0 "Not Active" 1 "ON" 2 "OFF" 3 "Reserved" ;
VAL_ 1072 AutoSeatVentLevelsFb_430h 0 "Not Active" 1 "ON" 2 "OFF" 3 "Reserved" ;
VAL_ 1072 DrvDoorSts_430h 0 "Close" 1 "Ajar" 2 "full_open" 3 "Reserved" ;
VAL_ 1072 DrvSeatBeltSW_430h 0 "Not Active" 1 "Active" ;
VAL_ 1072 DrvRearWinPosn_430h 127 "Invalid" ;
VAL_ 1072 DrvSeatHeatLevels_430h 0 "OFF" 1 "Level1" 2 "Level2" 3 "Level3" ;
VAL_ 1072 DrvRearChildProtectSwt_430h 0 "Locked" 1 "Unlocked" 2 "Superlocked" ;
VAL_ 1072 DrvSecSeatHeatLevels_430h 0 "OFF" 1 "Level1" 2 "Level2" 3 "Level3" ;
VAL_ 1072 DrvSeatVentLevels_430h 0 "OFF" 1 "Level1" 2 "Level2" 3 "Level3" ;
VAL_ 1072 DrvSecSeatVentLevels_430h 0 "OFF" 1 "Level1" 2 "Level2" 3 "Level3" ;
VAL_ 1072 DrvWinPosn_430h 127 "Invalid" ;
VAL_ 1072 FLZCU_RearWiperMaintenanceSts 0 "Not Active" 1 "ON" 2 "OFF" ;
VAL_ 1072 FLZCU_FrontWiperMaintenanceSts 0 "Not Active" 1 "ON" 2 "OFF" ;
VAL_ 1073 RearDoorSta_431h 0 "Close" 1 "Open" ;
VAL_ 1073 RearDoorMoveDirection_431h 0 "Down_Moving" 1 "UP_Moving" 2 "Stop" 3 "Reserved" ;
VAL_ 1075 VCC_2_ConfigurationMessageTrg 0 "not active" 1 "active" ;
VAL_ 1078 PLG_LatchSts 0 "Open" 1 "Secondary" 2 "Latched" 3 "Initializing" ;
VAL_ 1079 BSCU_1_MotorLockSts 0 "Not active" 1 "Locked" 2 "HalfLocked" 3 "Unlocked" ;
VAL_ 1087 RightSeatMsgStr_LvlSts 0 "OFF/Intial" 1 "Low" 2 "Middle" 3 "High" 4 "Reserved" 5 "Reserved" 6 "Reserved" 7 "Reserved" ;
VAL_ 1087 RightSeatMsg_ModeSts 0 "NotActive" 1 "PulseMode" 2 "WaveMode" 3 "CatPawMode" 4 "SigleRowMode" 5 "CrossMode" 6 "ButterflyMode" 7 "WaistMode" 8 "SnakeMode" 9 "Special 1" 10 "Special 2" 11 "Special 3" 12 "Special 4" ;
VAL_ 1095 RLCR_1_SysSt 0 "Off" 1 "On" 2 "Temporary Error" 3 "System Error" ;
VAL_ 1095 RLCR_1_BlkSts 0 "Not Blockage" 1 "Blockage" ;
VAL_ 1095 RLCR_1_BSDWarn 0 "No Warning" 1 "Standard Warning" 2 "Critical Warning" 3 "Not Used" ;
VAL_ 1095 RLCR_1_ELK_Collision_flag 0 "No critical situation of collision" 1 "Critical situation of collision" ;
VAL_ 1095 RLCR_1_ELK_CollisionFlagValid 0 "Not valid" 1 "Valid" ;
VAL_ 1096 TMS_AirPurgeReminderSts 0 "Not_Active" 1 "ON" 2 "OFF" 3 "Not_Used" ;
VAL_ 1096 TMS_CirculationInTunnelsSts 0 "Off" 1 "Active" ;
VAL_ 1096 TMS_First_BlowingSts 0 "Off" 1 "Active" ;
VAL_ 1096 TMS_BT_Reduce_Wind_SpeedSts 0 "Off" 1 "Active" ;
VAL_ 1096 TMS_CoolantFillSts 0 "No_Request" 1 "Request" ;
VAL_ 1096 TMS_ParkingAirConditioningStatus 0 "Inactive" 1 "AUTO" 2 "ventilate" ;
VAL_ 1096 TMS_crosscountry_coolingSts 0 "No_Request" 1 "Active" 2 "Not_Active" ;
VAL_ 1096 TMS_ICC_Lightoff_Sts 0 "No_Request" 1 "FraganceLight_on_Sts" 2 "FraganceLight_off_Sts" 3 "Reserved" ;
VAL_ 1096 TMS_UVC_LuminanceSts 0 "No_Request" 1 "level_1" 2 "level_2" 3 "Reserved" 4 "Reserved" 5 "Reserved" 6 "Reserved" 7 "Reserved" ;
VAL_ 1096 TMS_AutoDefogActiveSts 0 "Off" 1 "On" ;
VAL_ 1096 TMS_UVC_ControlSts 0 "No_Request" 1 "Close_Request" 2 "Open_Request" 3 "AUTO" ;
VAL_ 1096 TMS_ICC_Memoff_Sts 0 "No_Request" 1 "FraganceMem_on" 2 "FraganceMem_off" 3 "Reserved" ;
VAL_ 1096 TMS_keepwarmSet_TemperatureSts 0 "Temperature_20°C" 1 "Temperature_25°C" 2 "Temperature_30°C" 3 "Temperature_35°C" 4 "Temperature_40°C" 5 "Temperature_45°C" 6 "Temperature_50°C" 7 "Temperature_55°C" 8 "Temperature_60°C" 9 "reserved" 10 "reserved" 11 "reserved" 12 "reserved" 13 "reserved" 14 "reserved" 15 "reserved" 16 "reserved" 17 "reserved" 18 "reserved" 19 "reserved" 20 "reserved" 21 "reserved" 22 "reserved" 23 "reserved" 24 "reserved" 25 "reserved" 26 "reserved" 27 "reserved" 28 "reserved" 29 "reserved" 30 "reserved" 31 "reserved" 32 "reserved" 33 "reserved" 34 "reserved" 35 "reserved" 36 "reserved" 37 "reserved" 38 "reserved" 39 "reserved" 40 "reserved" 41 "reserved" 42 "reserved" 43 "reserved" 44 "reserved" 45 "reserved" 46 "reserved" 47 "reserved" 48 "reserved" 49 "reserved" 50 "reserved" 51 "reserved" 52 "reserved" 53 "reserved" 54 "reserved" 55 "reserved" 56 "reserved" 57 "reserved" 58 "reserved" 59 "reserved" 60 "reserved" 61 "reserved" 62 "reserved" 63 "reserved" 64 "reserved" 65 "reserved" 66 "reserved" 67 "reserved" 68 "reserved" 69 "reserved" 70 "reserved" 71 "reserved" 72 "reserved" 73 "reserved" 74 "reserved" 75 "reserved" 76 "reserved" 77 "reserved" 78 "reserved" 79 "reserved" 80 "reserved" 81 "reserved" 82 "reserved" 83 "reserved" 84 "reserved" 85 "reserved" 86 "reserved" 87 "reserved" 88 "reserved" 89 "reserved" 90 "reserved" 91 "reserved" 92 "reserved" 93 "reserved" 94 "reserved" 95 "reserved" 96 "reserved" 97 "reserved" 98 "reserved" 99 "reserved" 100 "reserved" 101 "reserved" 102 "reserved" 103 "reserved" 104 "reserved" 105 "reserved" 106 "reserved" 107 "reserved" 108 "reserved" 109 "reserved" 110 "reserved" 111 "reserved" 112 "reserved" 113 "reserved" 114 "reserved" 115 "reserved" 116 "reserved" 117 "reserved" 118 "reserved" 119 "reserved" 120 "reserved" 121 "reserved" 122 "reserved" 123 "reserved" 124 "reserved" 125 "reserved" 126 "reserved" 127 "reserved" 128 "reserved" 129 "reserved" 130 "reserved" 131 "reserved" 132 "reserved" 133 "reserved" 134 "reserved" 135 "reserved" 136 "reserved" 137 "reserved" 138 "reserved" 139 "reserved" 140 "reserved" 141 "reserved" 142 "reserved" 143 "reserved" 144 "reserved" 145 "reserved" 146 "reserved" 147 "reserved" 148 "reserved" 149 "reserved" 150 "reserved" 151 "reserved" 152 "reserved" 153 "reserved" 154 "reserved" 155 "reserved" 156 "reserved" 157 "reserved" 158 "reserved" 159 "reserved" 160 "reserved" 161 "reserved" 162 "reserved" 163 "reserved" 164 "reserved" 165 "reserved" 166 "reserved" 167 "reserved" 168 "reserved" 169 "reserved" 170 "reserved" 171 "reserved" 172 "reserved" 173 "reserved" 174 "reserved" 175 "reserved" 176 "reserved" 177 "reserved" 178 "reserved" 179 "reserved" 180 "reserved" 181 "reserved" 182 "reserved" 183 "reserved" 184 "reserved" 185 "reserved" 186 "reserved" 187 "reserved" 188 "reserved" 189 "reserved" 190 "reserved" 191 "reserved" 192 "reserved" 193 "reserved" 194 "reserved" 195 "reserved" 196 "reserved" 197 "reserved" 198 "reserved" 199 "reserved" 200 "reserved" 201 "reserved" 202 "reserved" 203 "reserved" 204 "reserved" 205 "reserved" 206 "reserved" 207 "reserved" 208 "reserved" 209 "reserved" 210 "reserved" 211 "reserved" 212 "reserved" 213 "reserved" 214 "reserved" 215 "reserved" 216 "reserved" 217 "reserved" 218 "reserved" 219 "reserved" 220 "reserved" 221 "reserved" 222 "reserved" 223 "reserved" 224 "reserved" 225 "reserved" 226 "reserved" 227 "reserved" 228 "reserved" 229 "reserved" 230 "reserved" 231 "reserved" 232 "reserved" 233 "reserved" 234 "reserved" 235 "reserved" 236 "reserved" 237 "reserved" 238 "reserved" 239 "reserved" 240 "reserved" 241 "reserved" 242 "reserved" 243 "reserved" 244 "reserved" 245 "reserved" 246 "reserved" 247 "reserved" 248 "reserved" 249 "reserved" 250 "reserved" 251 "reserved" 252 "reserved" 253 "reserved" 254 "reserved" ;
VAL_ 1096 TMS_BiochemicalFuncSts 0 "Not Active" 1 "ON" 2 "OFF" 3 "Reserved" ;
VAL_ 1096 TMS_TimedVentilationSts 0 "Not Active" 1 "ON" 2 "OFF" 3 "Reserved" ;
VAL_ 1096 TMS_LowbattACDisable_448h 0 "Not Active" 1 "NoRequest" 2 "Request" 3 "Reserved" ;
VAL_ 1096 TMS_SailEACDisable_448h 0 "Not Active" 1 "NoRequest" 2 "Request" 3 "Reserved" ;
VAL_ 1096 TMS_ICAstsFed_448h 0 "Not Active" 1 "Open" 2 "Close" 3 "Fault" ;
VAL_ 1099 ISGF_SysTempOvrInd 0 "Lamp off" 1 "Lamp on" ;
VAL_ 1100 Set_AMPNaviVolume 0 "Not Active" 1 "0" 2 "1" 3 "2" 4 "3" 5 "4" 6 "5" 7 "6" 8 "7" 9 "8" 10 "9" 11 "10" 12 "Reserved" 13 "Reserved" 14 "Reserved" 15 "Reserved" ;
VAL_ 1100 Set_AMPVRVolume 0 "Not Active" 1 "0" 2 "1" 3 "2" 4 "3" 5 "4" 6 "5" 7 "6" 8 "7" 9 "8" 10 "9" 11 "10" 12 "Reserved" 13 "Reserved" 14 "Reserved" 15 "Reserved" ;
VAL_ 1100 Set_AMPKeyTone 0 "Not Active" 1 "ON" 2 "OFF" 3 "reserved" ;
VAL_ 1100 Set_AMPMediaVolume 0 "Not Active" 1 "0" 2 "1" 3 "2" 4 "3" 5 "4" 6 "5" 7 "6" 8 "7" 9 "8" 10 "9" 11 "10" 12 "11" 13 "12" 14 "13" 15 "14" 16 "15" 17 "16" 18 "17" 19 "18" 20 "19" 21 "20" 22 "21" 23 "22" 24 "23" 25 "24" 26 "25" 27 "26" 28 "27" 29 "28" 30 "29" 31 "30" 32 "31" 33 "Reserved" 34 "Reserved" 35 "Reserved" 36 "Reserved" 37 "Reserved" 38 "Reserved" 39 "Reserved" 40 "Reserved" 41 "Reserved" 42 "Reserved" 43 "Reserved" 44 "Reserved" 45 "Reserved" 46 "Reserved" 47 "Reserved" 48 "Reserved" 49 "Reserved" 50 "Reserved" 51 "Reserved" 52 "Reserved" 53 "Reserved" 54 "Reserved" 55 "Reserved" 56 "Reserved" 57 "Reserved" 58 "Reserved" 59 "Reserved" 60 "Reserved" 61 "Reserved" 62 "Reserved" 63 "Reserved" ;
VAL_ 1100 Set_AMPPhoneVolume 0 "Not Active" 1 "0" 2 "1" 3 "2" 4 "3" 5 "4" 6 "5" 7 "6" 8 "7" 9 "8" 10 "9" 11 "10" 12 "11" 13 "12" 14 "13" 15 "14" 16 "15" 17 "16" 18 "17" 19 "18" 20 "19" 21 "20" 22 "21" 23 "22" 24 "23" 25 "24" 26 "25" 27 "Reserved" 28 "Reserved" 29 "Reserved" 30 "Reserved" 31 "Reserved" ;
VAL_ 1100 Set_AMPSoundFocus 0 "Not Active" 1 "Customized" 2 "All" 3 "Driver" 4 "Sleep" 5 "VIP" 6 "Dolby7.1.4" 7 "Reserved" ;
VAL_ 1100 Set_AMPSoundEffect 0 "Not Active" 1 "Customer-defined mode" 2 "Standard mode" 3 "Popular mode" 4 "Jazz mode" 5 "Classic mode" 6 "Rock mode" 7 "Vocal mode" 8 "Reserved" 9 "Reserved" 10 "Reserved" 11 "Reserved" 12 "Reserved" 13 "Reserved" 14 "Reserved" 15 "Reserved" ;
VAL_ 1100 Set_AMPSoundEffectBass 0 "Not Active" 1 "-7" 2 "-6" 3 "-5" 4 "-4" 5 "-3" 6 "-2" 7 "-1" 8 "0" 9 "1" 10 "2" 11 "3" 12 "4" 13 "5" 14 "6" 15 "7" ;
VAL_ 1100 Set_AMPSoundEffectMidrange 0 "Not Active" 1 "-7" 2 "-6" 3 "-5" 4 "-4" 5 "-3" 6 "-2" 7 "-1" 8 "0" 9 "1" 10 "2" 11 "3" 12 "4" 13 "5" 14 "6" 15 "7" ;
VAL_ 1100 Set_AMPSoundEffectTreble 0 "Not Active" 1 "-7" 2 "-6" 3 "-5" 4 "-4" 5 "-3" 6 "-2" 7 "-1" 8 "0" 9 "1" 10 "2" 11 "3" 12 "4" 13 "5" 14 "6" 15 "7" ;
VAL_ 1100 Set_AMPSoundFieldBalance 0 "Not Active" 1 "-7" 2 "-6" 3 "-5" 4 "-4" 5 "-3" 6 "-2" 7 "-1" 8 "0" 9 "1" 10 "2" 11 "3" 12 "4" 13 "5" 14 "6" 15 "7" ;
VAL_ 1100 Set_AMPSoundFieldFader 0 "Not Active" 1 "-7" 2 "-6" 3 "-5" 4 "-4" 5 "-3" 6 "-2" 7 "-1" 8 "0" 9 "1" 10 "2" 11 "3" 12 "4" 13 "5" 14 "6" 15 "7" ;
VAL_ 1100 ICC_AMPVRVolume_44Ch 0 "Not Active" 1 "0" 2 "1" 3 "2" 4 "3" 5 "4" 6 "5" 7 "6" 8 "7" 9 "8" 10 "9" 11 "10" 12 "11" 13 "12" 14 "13" 15 "14" 16 "15" 17 "16" 18 "17" 19 "18" 20 "19" 21 "20" 22 "21" 23 "22" 24 "23" 25 "24" 26 "25" 27 "26" 28 "27" 29 "28" 30 "29" 31 "30" 32 "31" ;
VAL_ 1100 Set_Headrest_Mode 0 "Not Active" 1 "Share Mode" 2 "Enjoy Driving Mode" 3 "Enjoy Private Mode" ;
VAL_ 1100 Set_SurndFnOnOff 0 "Not Active" 1 "ON" 2 "OFF" 3 "Reserved" ;
VAL_ 1100 Set_VirtualSbwfrOnOff 0 "Not Active" 1 "VocalConcert" 2 "ConcertHall" 3 "OFF" ;
VAL_ 1104 RLCR_2_RCWWarn 0 "No Warning" 1 "Level1 Warning" 2 "Level2 Warning" 3 "Not Used" ;
VAL_ 1104 RLCR_2_RCTAWarn 0 "No Warning" 1 "Warning" ;
VAL_ 1104 RLCR_2_BSDLCWONOFFSts 0 "Not active" 1 "OFF" 2 "ON" 3 "Reserved" ;
VAL_ 1104 RLCR_2_DOWONOFFSts 0 "Not active" 1 "OFF" 2 "ON" 3 "Reserved" ;
VAL_ 1104 RLCR_2_RCWONOFFSts 0 "Not active" 1 "OFF" 2 "ON" 3 "Reserved" ;
VAL_ 1104 RLCR_2_RCTARCTBONOFFSts 0 "OFF" 1 "warning" 2 "Reserved" 3 "Reserved" ;
VAL_ 1105 ICC_MultiplexSignalStatusSet 0 "Not Active" 1 "Mirror" 2 "EPS" 3 "HUD" 4 "OFF" 5 "Reserved" 6 "Reserved" 7 "invalid" ;
VAL_ 1107 TMS_CCP_FrontAutoACSts 0 "NotActive" 1 "Active" ;
VAL_ 1107 TMS_PM25_Detect 0 "NotActive" 1 "Active" ;
VAL_ 1107 TMS_CCP_FrontDefrostSts 0 "NotActive" 1 "Active" ;
VAL_ 1107 TMS_CCP_FBlowSpdCtrlSts 0 "No_Request" 1 "Speed_1_Request" 2 "Speed_2_Request" 3 "Speed_3_Request" 4 "Speed_4_Request" 5 "Speed_5_Request" 6 "Speed_6_Request" 7 "Speed_7_Request" 8 "Speed_8_Request" 9 "Speed_9_Request" 10 "Speed_10_Request" 12 "Speed_0_Request" 15 "Invalid" ;
VAL_ 1107 TMS_CCP_FrontOFFSts 0 "NotActive" 1 "Active" ;
VAL_ 1107 TMS_CCP_ACStatus 0 "NotActive" 1 "Active" ;
VAL_ 1107 TMS_CCP_RecyMode 0 "no_Request" 1 "internal_Recycle_Request" 2 "external_Recycle_Request" 3 "auto_Recycle_Request" ;
VAL_ 1107 TMS_CCP_ACFastHeat 0 "Not_Active" 1 "ON" 2 "OFF" 3 "Not_Used" ;
VAL_ 1107 TMS_CCP_ACFastCool 0 "Not_Active" 1 "ON" 2 "OFF" 3 "Not_Used" ;
VAL_ 1107 TMS_UVC_LuminanceBfReq 0 "No_Request" 1 "Higher" 2 "Lower" 3 "Reserved" ;
VAL_ 1107 TMS_UVC_WorkingBfReq 0 "No_Request" 1 "Open_Request" 2 "Close_Request" 3 "AUTO" ;
VAL_ 1107 TMS_ThrModeStsFb_453h 0 "Blow Face" 1 "Blow Face and Blow Foot" 2 "Blow Foot" 3 "Auto" 4 "Reserved" 5 "Reserved" 6 "Reserved" 7 "Not Active" ;
VAL_ 1107 TMS_ThrCLMSwitchFb_453h 0 "OFF" 1 "On" ;
VAL_ 1107 TMS_ThrAutoSwitchFb_453h 0 "Auto OFF" 1 "Auto On" ;
VAL_ 1107 TMS_ThrACReqKeyStsFb_453h 0 "OFF" 1 "On" ;
VAL_ 1109 CWC_ChargingSts 0 "No charging" 1 "Charging" 2 "Charging completed" 3 "Charging fault" ;
VAL_ 1109 CWC_workingSts 0 "CWC OFF" 1 "CWC ON" ;
VAL_ 1109 CWC_Phoneforgotten 0 "phone not forgotten" 1 "phone forgotten" ;
VAL_ 1109 CWC_Phoneforgotten_ON_OFF_Sts 0 "Function OFF" 1 "Function ON" ;
VAL_ 1109 CWC_1_ChrgFlt 0 "Not active" 1 "Low_Volf" 2 "High_Volf" 3 "High_Temp" 4 "Foreign_matter_detected" 5 "NFC_card_protect_L" 6 "Reserved" 7 "Reserved" ;
VAL_ 1109 CWC_ChargingSts_R 0 "No charging" 1 "Charging" 2 "Charging completed" 3 "Charging fault" ;
VAL_ 1109 CWC_workingSts_R 0 "CWC OFF" 1 "CWC ON" ;
VAL_ 1109 CWC_Phoneforgotten_R 0 "phone not forgotten" 1 "phone forgotten" ;
VAL_ 1109 CWC_Phoneforgotten_ON_OFF_Sts_R 0 "Function OFF" 1 "Function ON" ;
VAL_ 1109 CWC_1_ChrgFlt_R 0 "Not active" 1 "Low_Volf" 2 "High_Vol" 3 "High_Temp" 4 "Foreign_matter_detected_R" 5 "NFC_card_protect_R" 6 "Reserved" 7 "Reserved" ;
VAL_ 1112 PassSeatMsgStr_LvlCmd_458h 0 "NotActive/Initial" 1 "OFF" 2 "Low" 3 "Middle" 4 "High" ;
VAL_ 1112 PassSeatMsg_ModeCmd_458h 0 "NotActive" 1 "PulseMode" 2 "WaveMode" 3 "CatPawMode" 4 "SigleRowMode" 5 "CrossMode" 6 "ButterflyMode" 7 "WaistMode" 8 "SnakeMode" 9 "Special 1" 10 "Special 2" 11 "Special 3" 12 "Special 4" ;
VAL_ 1112 DriverSeatMsgStr_Lvlcmd 0 "NotActive/Initial" 1 "OFF" 2 "Low" 3 "Middle" 4 "High" ;
VAL_ 1112 DriverSeatMsg_ModeCmd 0 "NotActive" 1 "PulseMode" 2 "WaveMode" 3 "CatPawMode" 4 "SigleRowMode" 5 "CrossMode" 6 "ButterflyMode" 7 "WaistMode" 8 "SnakeMode" 9 "Special 1" 10 "Special 2" 11 "Special 3" 12 "Special 4" ;
VAL_ 1112 ICC_DSeatInOrDeflationCmd_458h 0 "NotActive" 1 "Inflate" 2 "Deflate" ;
VAL_ 1112 ICC_DSeatBolsterModeCmd_458h 0 "NotActive" 1 "Off" 2 "Normal" 3 "sensitive" ;
VAL_ 1112 PassSecSeatMsgStr_LvlCmd_458h 0 "NotActive/Initial" 1 "OFF" 2 "Low" 3 "Middle" 4 "High" ;
VAL_ 1112 PassSecSeatMsg_ModeCmd_458h 0 "NotActive" 1 "PulseMode" 2 "WaveMode" 3 "CatPawMode" 4 "SigleRowMode" 5 "CrossMode" 6 "ButterflyMode" 7 "WaistMode" 8 "SnakeMode" 9 "Special 1" 10 "Special 2" 11 "Special 3" 12 "Special 4" ;
VAL_ 1112 DrvSecSeatMsgStr_LvlCmd_458h 0 "NotActive/Initial" 1 "OFF" 2 "Low" 3 "Middle" 4 "High" ;
VAL_ 1112 DrvSecSeatMsg_ModeCmd_458h 0 "NotActive" 1 "PulseMode" 2 "WaveMode" 3 "CatPawMode" 4 "SigleRowMode" 5 "CrossMode" 6 "ButterflyMode" 7 "WaistMode" 8 "SnakeMode" 9 "Special 1" 10 "Special 2" 11 "Special 3" 12 "Special 4" ;
VAL_ 1119 Set_AMPMediaDuck 0 "Not Active" 1 "ON" 2 "OFF" 3 "Reserved" ;
VAL_ 1119 Set_AMPSpeedVolume 0 "Not Active" 1 "OFF" 2 "Low" 3 "Middle" 4 "High" 5 "Reserved" 6 "Reserved" 7 "Reserved" ;
VAL_ 1119 Set_AMPMute 0 "Not Active" 1 "ON" 2 "OFF" 3 "Reserved" ;
VAL_ 1119 REQ_AMPA2BMediaSound 0 "Not Active" 1 "Media" 2 "Background" 3 "OFF" ;
VAL_ 1119 REQ_AMPA2BNaviSound 0 "Not Active" 1 "ON" 2 "OFF" 3 "Reserved" ;
VAL_ 1119 REQ_AMPA2BVRSound 0 "Not Active" 1 "VR" 2 "Siri" 3 "OFF" ;
VAL_ 1119 REQ_AMPA2BTTSSound 0 "Not Active" 1 "ON" 2 "OFF" 3 "Reserved" ;
VAL_ 1119 ICC_AMPPhoneVolume_45Fh 0 "Not Active" 1 "0" 2 "1" 3 "2" 4 "3" 5 "4" 6 "5" 7 "6" 8 "7" 9 "8" 10 "9" 11 "10" 12 "11" 13 "12" 14 "13" 15 "14" 16 "15" 17 "16" 18 "17" 19 "18" 20 "19" 21 "20" 22 "21" 23 "22" 24 "23" 25 "24" 26 "25" 27 "26" 28 "27" 29 "28" 30 "29" 31 "30" 32 "31" ;
VAL_ 1119 REQ_AMPA2BKeyTone 0 "Not Active" 1 "ON" 2 "OFF" 3 "Reserved" ;
VAL_ 1119 Set_AMPRestoreDefaults 0 "Not Active" 1 "ON" 2 "OFF" 3 "Reserved" ;
VAL_ 1119 Set_AMPAlarmVolume 0 "Not Active" 1 "1" 2 "2" 3 "3" 4 "4" 5 "5" 6 "6" 7 "7" 8 "8" 9 "9" 10 "10" 11 "Reserved" 12 "Reserved" 13 "Reserved" 14 "Reserved" 15 "Reserved" ;
VAL_ 1119 REQ_AMPA2BPhoneSound 0 "Not Active" 1 "BT Phone Sound ON" 2 "Tbox Sound ON" 3 "OFF" ;
VAL_ 1119 Set_AMPSoundEffectMegaBass 0 "Not Active" 1 "-7" 2 "-6" 3 "-5" 4 "-4" 5 "-3" 6 "-2" 7 "-1" 8 "0" 9 "1" 10 "2" 11 "3" 12 "4" 13 "5" 14 "6" 15 "7" ;
VAL_ 1119 Set_AMPSoundEffectMidBass 0 "Not Active" 1 "-7" 2 "-6" 3 "-5" 4 "-4" 5 "-3" 6 "-2" 7 "-1" 8 "0" 9 "1" 10 "2" 11 "3" 12 "4" 13 "5" 14 "6" 15 "7" ;
VAL_ 1119 Set_AMPSoundEffectMidTreble 0 "Not Active" 1 "-7" 2 "-6" 3 "-5" 4 "-4" 5 "-3" 6 "-2" 7 "-1" 8 "0" 9 "1" 10 "2" 11 "3" 12 "4" 13 "5" 14 "6" 15 "7" ;
VAL_ 1119 Set_AMPSoundBypass 0 "Not Active" 1 "ON" 2 "OFF" 3 "Reserved" ;
VAL_ 1119 Set_AMPA2BConfig 0 "Not Active" 1 "Not OK" 2 "OK" 3 "Reserved" ;
VAL_ 1119 Set_AMPBackgroundVolume 0 "Not Active" 1 "0" 2 "1" 3 "2" 4 "3" 5 "4" 6 "5" 7 "6" 8 "7" 9 "8" 10 "9" 11 "10" 12 "11" 13 "12" 14 "13" 15 "14" 16 "15" 17 "16" 18 "17" 19 "18" 20 "19" 21 "20" 22 "21" 23 "22" 24 "23" 25 "24" 26 "25" 27 "26" 28 "27" 29 "28" 30 "29" 31 "30" 32 "31" 33 "Reserved" 34 "Reserved" 35 "Reserved" 36 "Reserved" 37 "Reserved" 38 "Reserved" 39 "Reserved" 40 "Reserved" 41 "Reserved" 42 "Reserved" 43 "Reserved" 44 "Reserved" 45 "Reserved" 46 "Reserved" 47 "Reserved" 48 "Reserved" 49 "Reserved" 50 "Reserved" 51 "Reserved" 52 "Reserved" 53 "Reserved" 54 "Reserved" 55 "Reserved" 56 "Reserved" 57 "Reserved" 58 "Reserved" 59 "Reserved" 60 "Reserved" 61 "Reserved" 62 "Reserved" 63 "Reserved" ;
VAL_ 1119 ICC_AMPNaviVolume_45Fh 0 "Not Active" 1 "0" 2 "1" 3 "2" 4 "3" 5 "4" 6 "5" 7 "6" 8 "7" 9 "8" 10 "9" 11 "10" 12 "11" 13 "12" 14 "13" 15 "14" 16 "15" 17 "16" 18 "17" 19 "18" 20 "19" 21 "20" 22 "21" 23 "22" 24 "23" 25 "24" 26 "25" 27 "26" 28 "27" 29 "28" 30 "29" 31 "30" 32 "31" ;
VAL_ 1120 RLHS_LiSwithReason 0 "Darkstart" 1 "Day" 2 "Night" 3 "Tunnul" ;
VAL_ 1121 STAT_AMPNaviVolume 0 "Not Active" 1 "0" 2 "1" 3 "2" 4 "3" 5 "4" 6 "5" 7 "6" 8 "7" 9 "8" 10 "9" 11 "10" 12 "Reserved" 13 "Reserved" 14 "Reserved" 15 "Reserved" ;
VAL_ 1121 STAT_AMPVRVolume 0 "Not Active" 1 "0" 2 "1" 3 "2" 4 "3" 5 "4" 6 "5" 7 "6" 8 "7" 9 "8" 10 "9" 11 "10" 12 "Reserved" 13 "Reserved" 14 "Reserved" 15 "Reserved" ;
VAL_ 1121 STAT_AMPKeyTone 0 "Not Active" 1 "ON" 2 "OFF" 3 "reserved" ;
VAL_ 1121 STAT_AMPMediaVolume 0 "Not Active" 1 "0" 2 "1" 3 "2" 4 "3" 5 "4" 6 "5" 7 "6" 8 "7" 9 "8" 10 "9" 11 "10" 12 "11" 13 "12" 14 "13" 15 "14" 16 "15" 17 "16" 18 "17" 19 "18" 20 "19" 21 "20" 22 "21" 23 "22" 24 "23" 25 "24" 26 "25" 27 "26" 28 "27" 29 "28" 30 "29" 31 "30" 32 "31" 33 "Reserved" 34 "Reserved" 35 "Reserved" 36 "Reserved" 37 "Reserved" 38 "Reserved" 39 "Reserved" 40 "Reserved" 41 "Reserved" 42 "Reserved" 43 "Reserved" 44 "Reserved" 45 "Reserved" 46 "Reserved" 47 "Reserved" 48 "Reserved" 49 "Reserved" 50 "Reserved" 51 "Reserved" 52 "Reserved" 53 "Reserved" 54 "Reserved" 55 "Reserved" 56 "Reserved" 57 "Reserved" 58 "Reserved" 59 "Reserved" 60 "Reserved" 61 "Reserved" 62 "Reserved" 63 "Reserved" ;
VAL_ 1121 STAT_AMPPhoneVolume 0 "Not Active" 1 "0" 2 "1" 3 "2" 4 "3" 5 "4" 6 "5" 7 "6" 8 "7" 9 "8" 10 "9" 11 "10" 12 "11" 13 "12" 14 "13" 15 "14" 16 "15" 17 "16" 18 "17" 19 "18" 20 "19" 21 "20" 22 "21" 23 "22" 24 "23" 25 "24" 26 "25" 27 "Reserved" 28 "Reserved" 29 "Reserved" 30 "Reserved" 31 "Reserved" ;
VAL_ 1121 STAT_AMPSoundFocus 0 "Not Active" 1 "Customized" 2 "All" 3 "Driver" 4 "Sleep" 5 "VIP" 6 "Dolby7.1.4" 7 "Reserved" ;
VAL_ 1121 STAT_AMPSoundEffect 0 "Not Active" 1 "Customer-defined mode" 2 "Standard mode" 3 "Popular mode" 4 "Jazz mode" 5 "Classic mode" 6 "Rock mode" 7 "Vocal mode" 8 "Reserved" 9 "Reserved" 10 "Reserved" 11 "Reserved" 12 "Reserved" 13 "Reserved" 14 "Reserved" 15 "Reserved" ;
VAL_ 1121 STAT_AMPSoundEffectBass 0 "Not Active" 1 "-7" 2 "-6" 3 "-5" 4 "-4" 5 "-3" 6 "-2" 7 "-1" 8 "0" 9 "1" 10 "2" 11 "3" 12 "4" 13 "5" 14 "6" 15 "7" ;
VAL_ 1121 STAT_AMPSoundEffectMidrange 0 "Not Active" 1 "-7" 2 "-6" 3 "-5" 4 "-4" 5 "-3" 6 "-2" 7 "-1" 8 "0" 9 "1" 10 "2" 11 "3" 12 "4" 13 "5" 14 "6" 15 "7" ;
VAL_ 1121 STAT_AMPSoundEffectTreble 0 "Not Active" 1 "-7" 2 "-6" 3 "-5" 4 "-4" 5 "-3" 6 "-2" 7 "-1" 8 "0" 9 "1" 10 "2" 11 "3" 12 "4" 13 "5" 14 "6" 15 "7" ;
VAL_ 1121 STAT_AMPSoundFieldBalance 0 "Not Active" 1 "-7" 2 "-6" 3 "-5" 4 "-4" 5 "-3" 6 "-2" 7 "-1" 8 "0" 9 "1" 10 "2" 11 "3" 12 "4" 13 "5" 14 "6" 15 "7" ;
VAL_ 1121 STAT_AMPSoundFieldFader 0 "Not Active" 1 "-7" 2 "-6" 3 "-5" 4 "-4" 5 "-3" 6 "-2" 7 "-1" 8 "0" 9 "1" 10 "2" 11 "3" 12 "4" 13 "5" 14 "6" 15 "7" ;
VAL_ 1121 STAT_REQ_AMPA2BMediaSound 0 "Not Active" 1 "Media" 2 "Background" 3 "OFF" ;
VAL_ 1121 STAT_REQ_AMPA2BNaviSound 0 "Not Active" 1 "ON" 2 "OFF" 3 "Reserved" ;
VAL_ 1121 STAT_REQ_AMPA2BVRSound 0 "Not Active" 1 "VR" 2 "Siri" 3 "OFF" ;
VAL_ 1121 STAT_REQ_AMPA2BTTSSound 0 "Not Active" 1 "ON" 2 "OFF" 3 "Reserved" ;
VAL_ 1121 STAT_REQ_AMPA2BPhoneSound 0 "Not Active" 1 "BT Phone Sound ON" 2 "Tbox Sound ON" 3 "OFF" ;
VAL_ 1121 STAT_REQ_AMPAlarm 0 "Not Active" 1 "Other CHIME" 2 "PDC_FL only" 3 "PDC_FR only" 4 "PDC_RL only" 5 "PDC_RR only" 6 "PDC_FL+FR" 7 "PDC_FL+RL" 8 "PDC_FL+RR" 9 "PDC_FR+RL" 10 "PDC_FR+RR" 11 "PDC_RL+RR" 12 "PDC_FL+FR+RL" 13 "PDC_FL+FR+RR" 14 "PDC_FL+RL+RR" 15 "PDC_FR+RL+RR" 16 "PDC_all" 17 "BSD_L only" 18 "BSD_R only" 19 "BSD_L+R" 20 "CHIME OFF" 21 "Reserved" 22 "Reserved" 23 "Reserved" 24 "Reserved" 25 "Reserved" 26 "Reserved" 27 "Reserved" 28 "Reserved" 29 "Reserved" 30 "Reserved" 31 "Reserved" 32 "Reserved" 33 "Reserved" 34 "Reserved" 35 "Reserved" 36 "Reserved" 37 "Reserved" 38 "Reserved" 39 "Reserved" 40 "Reserved" 41 "Reserved" 42 "Reserved" 43 "Reserved" 44 "Reserved" 45 "Reserved" 46 "Reserved" 47 "Reserved" 48 "Reserved" 49 "Reserved" 50 "Reserved" 51 "Reserved" 52 "Reserved" 53 "Reserved" 54 "Reserved" 55 "Reserved" 56 "Reserved" 57 "Reserved" 58 "Reserved" 59 "Reserved" 60 "Reserved" 61 "Reserved" 62 "Reserved" 63 "Reserved" ;
VAL_ 1123 IMMOCodeWarningLightSts_463h 0 "Engine start enable" 1 "Engine start disable" 2 "Key not stored" 3 "Not valid" ;
VAL_ 1123 ISS_Switch_Sts_463h 0 "Not Active" 1 "ISS_Switch_Off" 2 "ISS_Switch_On" ;
VAL_ 1127 DCDC_FaultLevelSts 0 "No fault" 1 "Lever1 fault" 2 "Lever2 fault" 3 "Lever3 fault" 4 "Lever4 fault" 5 "Reserved" 6 "Reserved" 7 "Reserved" ;
VAL_ 1128 ISS_Sts_GS_468h 0 "ISS_DefaultOn" 1 "ISS_EOL" 2 "ISS_StopEnable" 3 "ISS_AutoStop" 4 "ISS_NoStopBelt" 5 "ISS_NoStopAC" 6 "ISS_NoStopDoor" 7 "ISS_NoStopHood" 8 "ISS_NoStopBrake" 9 "ISS_AutoStart" 10 "ISS_NoStartBelt" 11 "ISS_OnSeatCheck" 12 "ISS_ExitInfo" 13 "ISS_ExitInfo2" 14 "ISS_AlarmNeutral" 15 "ISS_AlarmStartByHand" 16 "ISS_AlarmFault" 17 "ISS_TurnOff" 18 "ISS_TurnOn" 19 "Reserved" 20 "Reserved" 21 "Reserved" 22 "Reserved" 23 "Reserved" 24 "Reserved" 25 "Reserved" 26 "Reserved" 27 "Reserved" 28 "Reserved" 29 "Reserved" 30 "Reserved" ;
VAL_ 1128 PromptMesg_468h 0 "Not Active" 1 "Off" 2 "Active" ;
VAL_ 1128 GPFWarning_468h 0 "No GPF warning" 1 "GPF Full" 2 "GPF Overlimited" 3 "Reserved" ;
VAL_ 1128 MILSts_468h 0 "Off" 1 "Not used" 2 "Active" 3 "Not used" ;
VAL_ 1128 IEMSts_468h 0 "Lamp Off" 1 "Lamp On" ;
VAL_ 1128 EPCSts_468h 0 "Off" 1 "Active" ;
VAL_ 1128 FuelRollingCounterValidData_468h 0 "Valid" 1 "Not valid" ;
VAL_ 1128 CruiseControlStsForDisplay_468h 0 "Not inserted" 1 "Inserted" 2 "Pre cruise (flash)" 3 "Cancel" ;
VAL_ 1128 Crosscountry_coolingSts_468h 0 "No_Request" 1 "Active" 2 "Not_Active" ;
VAL_ 1129 EngineSpeedValidData_469h 0 "Valid" 1 "Not valid" ;
VAL_ 1130 TCU_23_GBFaultstatus 0 "No failure" 1 "GB failure" 2 "High oil over temperature" 3 "Clutch over temperature" ;
VAL_ 1130 TCU_23_TeachInState 0 "Default" 1 "Successful" 2 "Fault" 3 "Teach in process" 4 "require teach in" 5 "teach in done" ;
VAL_ 1130 TCU_23_CluSelfLrng 0 "No Request" 1 "ClutchSelfLearnEnb" ;
VAL_ 1131 GBPositoionDisplay_46Bh 0 "NO Display" 1 "Display P" 2 "Display R" 3 "Display N" 4 "Display D" 5 "Display M1" 6 "Display M2" 7 "Display M3" 8 "Display M4" 9 "Display M5" 10 "Display M6" 11 "Display M7" 12 "Low" 13 "Display M1+" 14 "Display M2+" 15 "Display M3+" 16 "Display M4+" 17 "Display M5+" 18 "Display M6+" 19 "Display M7+" 20 "Display M2-" 21 "Display M3-" 22 "Display M4-" 23 "Display M5-" 24 "Display M6-" 25 "Display M7-" 26 "Display M8" 27 "Display M9" 28 "Display M8+" 29 "Display M8-" 30 "Display M9-" ;
VAL_ 1131 SpeParkSts_46Bh 0 "Not Active" 1 "OFF" 2 "ON" ;
VAL_ 1131 GBFaultstatus_46Bh 0 "No failure" 1 "GB failure" 2 "High oil over temperature" 3 "Clutch over temperature" ;
VAL_ 1131 ClutchTemperature_46Bh 0 "Normal" 1 "Over" 2 "Super over" 3 "Not used" ;
VAL_ 1137 ICC_BookChrgSetReq 0 "default" 1 "BookSet" 2 "CancellBook" 3 "Reserved" ;
VAL_ 1137 ICC_BkChrgCycleMon 0 "Not active" 1 "Active" ;
VAL_ 1137 ICC_StopChrgReq 0 "Not Active" 1 "Active" ;
VAL_ 1137 ICC_BkChrgCycleType 0 "default" 1 "Once" 2 "EveryDay" 3 "WorkDay" 4 "Reserved" 5 "Reserved" ;
VAL_ 1137 ICC_BkChrgCycleFri 0 "Not active" 1 "Active" ;
VAL_ 1137 ICC_BkChrgCycleThur 0 "Not active" 1 "Active" ;
VAL_ 1137 ICC_BkChrgCycleWen 0 "Not active" 1 "Active" ;
VAL_ 1137 ICC_BkChrgCycleTues 0 "Not active" 1 "Active" ;
VAL_ 1137 ICC_BkChrgCycleSun 0 "Not active" 1 "Active" ;
VAL_ 1137 ICC_BkChrgCycleSat 0 "Not active" 1 "Active" ;
VAL_ 1137 ICC_PetmodeFb 0 "Not active" 1 "ON" 2 "OFF" 3 "Invalid" ;
VAL_ 1137 ICC_SentinelModeFaultSts 0 "Not Warming" 1 "Artificial occlusion" 2 "Rain and snow cover" 3 "Reserved" ;
VAL_ 1137 ICC_SentinelModeWorkingSts 0 "Not Active" 1 "Active" 2 "LowSOC" 3 "HVNotReady" 4 "HVFault" 5 "MirrorUnFold" 6 "CameraFault" 7 "LowBatVolt" ;
VAL_ 1137 ICC_SentinelModeSwitchSts 0 "Not active" 1 "ON" 2 "OFF" 3 "Reserved" ;
VAL_ 1137 ICC_PetModeWarn 0 "Not Active" 1 "High Voltage Battery Low" 2 "TMS Abnormal" 3 "High Pressure Abnormal" 4 "Low Voltage Battery Low" 5 "High Voltage Battery Less Than 15%" 6 "High Voltage Battery Less Than 12%" 7 "Time Long Warning" ;
VAL_ 1137 ICC_SentinelModeExitReason 0 "Normal" 1 "LowSOC" 2 "HVNotReady" 3 "HVFault" 4 "MirrorUnFold" 5 "CameraFault" 6 "LowBatVolt" 7 "Reserved" ;
VAL_ 1137 ICC_SentinelModeAlarmSts 0 "Not Alarm" 1 "Level 1" 2 "Level 2" 3 "Level 3" ;
VAL_ 1137 ICC_TBOXPetmodeReq 0 "Not Active" 1 "ON" 2 "OFF" 3 "Reserved" ;
VAL_ 1137 ICC_PetModeWarn_2 0 "Not Active" 1 "High Voltage Battery Low" 2 "TMS Abnormal" 3 "High Pressure Abnormal" 4 "Low Voltage Battery Low" 5 "High Voltage Battery Less Than 15%" 6 "High Voltage Battery Less Than 12%" 7 "Time Long Warning" 8 "Vehicle charging" 9 "Vehicle Disarming" 10 "Gear is non-p" ;
VAL_ 1137 ICC_ElectronicFenceStsFed_471h 0 "Not Active" 1 "ON" 2 "OFF" 3 "Reserved" ;
VAL_ 1137 ICM_Maintenance_tips 0 "Tip_Not_Present" 1 "Tip_Present" ;
VAL_ 1137 ICM_FuelLevelFailSts 0 "Fail_Not_Present" 1 "Fail_Present" ;
VAL_ 1137 ICC_ChgSOCPrioritySet_471h 0 "Not active" 1 "ChrgDuration_FullPriority" 2 "SOC_SetPriority" ;
VAL_ 1140 STAT_AMPMediaDuck 0 "Not Active" 1 "ON" 2 "OFF" 3 "Reserved" ;
VAL_ 1140 STAT_AMPSpeedVolume 0 "Not Active" 1 "OFF" 2 "Low" 3 "Middle" 4 "High" 5 "Reserved" 6 "Reserved" 7 "Reserved" ;
VAL_ 1140 STAT_AMPMute 0 "Not Active" 1 "ON" 2 "OFF" 3 "Reserved" ;
VAL_ 1140 STAT_AMPRestoreDefaults 0 "Not Active" 1 "ON" 2 "OFF" 3 "Reserved" ;
VAL_ 1140 STAT_AMPAlarmVolume 0 "Not Active" 1 "1" 2 "2" 3 "3" 4 "4" 5 "5" 6 "6" 7 "7" 8 "8" 9 "9" 10 "10" 11 "Reserved" 12 "Reserved" 13 "Reserved" 14 "Reserved" 15 "Reserved" ;
VAL_ 1140 STAT_Headrest_Mode 0 "Not Active" 1 "Share Mode" 2 "Enjoy Driving Mode" 3 "Enjoy Private Mode" ;
VAL_ 1140 STAT_AMPSoundEffectMegaBass 0 "Not Active" 1 "-7" 2 "-6" 3 "-5" 4 "-4" 5 "-3" 6 "-2" 7 "-1" 8 "0" 9 "1" 10 "2" 11 "3" 12 "4" 13 "5" 14 "6" 15 "7" ;
VAL_ 1140 STAT_AMPSoundEffectMidBass 0 "Not Active" 1 "-7" 2 "-6" 3 "-5" 4 "-4" 5 "-3" 6 "-2" 7 "-1" 8 "0" 9 "1" 10 "2" 11 "3" 12 "4" 13 "5" 14 "6" 15 "7" ;
VAL_ 1140 STAT_AMPSoundEffectMidTreble 0 "Not Active" 1 "-7" 2 "-6" 3 "-5" 4 "-4" 5 "-3" 6 "-2" 7 "-1" 8 "0" 9 "1" 10 "2" 11 "3" 12 "4" 13 "5" 14 "6" 15 "7" ;
VAL_ 1140 STAT_VirtualSbwfrOnOff 0 "Not Active" 1 "VocalConcert" 2 "ConcertHall" 3 "OFF" ;
VAL_ 1140 STAT_SurndFnOnOff 0 "Not Active" 1 "ON" 2 "OFF" 3 "Reserved" ;
VAL_ 1140 STAT_AMPBackgroundVolume 0 "Not Active" 1 "0" 2 "1" 3 "2" 4 "3" 5 "4" 6 "5" 7 "6" 8 "7" 9 "8" 10 "9" 11 "10" 12 "11" 13 "12" 14 "13" 15 "14" 16 "15" 17 "16" 18 "17" 19 "18" 20 "19" 21 "20" 22 "21" 23 "22" 24 "23" 25 "24" 26 "25" 27 "26" 28 "27" 29 "28" 30 "29" 31 "30" 32 "31" 33 "Reserved" 34 "Reserved" 35 "Reserved" 36 "Reserved" 37 "Reserved" 38 "Reserved" 39 "Reserved" 40 "Reserved" 41 "Reserved" 42 "Reserved" 43 "Reserved" 44 "Reserved" 45 "Reserved" 46 "Reserved" 47 "Reserved" 48 "Reserved" 49 "Reserved" 50 "Reserved" 51 "Reserved" 52 "Reserved" 53 "Reserved" 54 "Reserved" 55 "Reserved" 56 "Reserved" 57 "Reserved" 58 "Reserved" 59 "Reserved" 60 "Reserved" 61 "Reserved" 62 "Reserved" 63 "Reserved" ;
VAL_ 1140 STAT_AMPSoundBypass 0 "Not Active" 1 "ON" 2 "OFF" 3 "Reserved" ;
VAL_ 1140 STAT_AMPPwrRdySts 0 "Not Active" 1 "Not Ready" 2 "Ready" 3 "Reserved" ;
VAL_ 1141 APADispSts_475h 0 "off" 1 "on" ;
VAL_ 1141 APA_FuncRecommend_475h 0 "No_Request" 1 "Request" ;
VAL_ 1141 APAPrkgChimeVoice_475h 0 "Not Request" 1 "ParkingchimeVoice1" 2 "ParkingchimeVoice2" 3 "ParkingchimeVoice3" 4 "ParkingchimeVoice4" 5 "ParkingchimeVoice5" 6 "Reserved" 7 "Reserved" ;
VAL_ 1141 AvmWinDisp_475h 0 "Full" 1 "BSV_Float" 2 "Object_Float" 3 "Reserved" ;
VAL_ 1141 ApaRpaSts_475h 0 "Off" 1 "Standby" 2 "Searching" 3 "Guidance active" 4 "Completed" 5 "Failure" 6 "Terminate" 7 "Pause" ;
VAL_ 1141 AVMFaultStatusCameraFront_475h 0 "Normal" 1 "Failure" ;
VAL_ 1141 AVMFaultStatusCameraLeft_475h 0 "Normal" 1 "Failure" ;
VAL_ 1141 AVMFaultStatusCameraRear_475h 0 "Normal" 1 "Failure" ;
VAL_ 1141 AVMFaultStatusCameraRight_475h 0 "Normal" 1 "Failure" ;
VAL_ 1141 APA_ParkingVoiceRemind_475h 0 "No_Request" 1 "Slot_Found" 2 "Req_Stop" 3 "Req_Press_Brake_pedal_&&_press_Start_Button" 4 "Req_Slow_speed" 5 "Req_Parking_start_guidance" 6 "Req_Apa_Pause" 7 "Req_Apa_Resume" 8 "Req_Apa_Completed" 9 "Req_Apa_Quit_&&_TOR" 10 "Req_MRA_Start_Guidance" 11 "Req_MRA_Paused" 12 "Req_MRA_Resume" 13 "Req_MRA_Completed" 14 "Req_MRA_Quit_&&_TOR" 15 "Req_Control_Fail" ;
VAL_ 1141 MRASts_475h 0 "OFF" 1 "Standby" 2 "Background Record" 3 "Preparing" 4 "Guidance" 5 "Finish and reset" 6 "failure" 7 "Terminate" 8 "Pause" ;
VAL_ 1142 HCU_4_G_SumEgyCns 511 "Invalid" ;
VAL_ 1143 OBC_CC_ConnectSts 0 "Not connected" 1 "Charge Connected" 2 "V2V" 3 "V2L" 4 "Half Connection" 5 "Error" 6 "Reserved" 7 "Reserved" ;
VAL_ 1143 CDU_MILSts 0 "Not Active" 1 "Active" ;
VAL_ 1143 OBC_InnerDischgReq 0 "No Req" 1 "Req" ;
VAL_ 1144 ICC_HvBattKeepWarmSet 0 "Not active" 1 "active" ;
VAL_ 1144 ICC_CarSickRelfModeReq 0 "Not Active" 1 "ON" 2 "OFF" 3 "Reserved" ;
VAL_ 1144 ICC_HvBattKeepWarmActiveReq 0 "Not active" 1 "StartWarm" 2 "EndWarm" 3 "Not Used" ;
VAL_ 1147 CCP_1_FrontAutoACSwitchReq 0 "No_Pressed" 1 "Pressed" ;
VAL_ 1147 FLCCP_MainSetHeatReq 0 "Not_Active" 1 "OFF" 2 "Seat_heating_Level1" 3 "Seat_heating_Level2" 4 "Seat_heating_Level3" ;
VAL_ 1147 CCP_1_FrontOFFSwitchReq 0 "No_Pressed" 1 "Pressed" ;
VAL_ 1147 CCP_1_FBlowSpdCtrlSwitchReq 0 "No_Request" 1 "Speed_1_Request" 2 "Speed_2_Request" 3 "Speed_3_Request" 4 "Speed_4_Request" 5 "Speed_5_Request" 6 "Speed_6_Request" 7 "Speed_7_Request" 8 "Speed_8_Request" 9 "Speed_9_Request" 10 "Speed_10_Request" 12 "Speed_0_Request" 15 "Invalid" ;
VAL_ 1147 CCP_1_ACFastCool 0 "Not_Active" 1 "On" 2 "Off" 3 "Not_Used" ;
VAL_ 1147 FLCCP_MainSetVentilationReq 0 "Not_Active" 1 "OFF" 2 "Seat_Ventilation_Level1" 3 "Seat_Ventilation_Level2" 4 "Seat_Ventilation_Level3" ;
VAL_ 1148 TBOX_GPSSwitchSts 0 "Not Active" 1 "On" 2 "Off" 3 "Not Used" ;
VAL_ 1148 TBOX_BkChrgCycleType 0 "default" 1 "Once" 2 "EveryDay" 3 "WorkDay" 4 "Reserved" 5 "Reserved" ;
VAL_ 1148 TBOX_BkChrgCycleThur 0 "Not active" 1 "Active" ;
VAL_ 1148 TBOX_BkChrgCycleWen 0 "Not active" 1 "Active" ;
VAL_ 1148 TBOX_BkChrgCycleTues 0 "Not active" 1 "Active" ;
VAL_ 1148 TBOX_BkChrgCycleMon 0 "Not active" 1 "Active" ;
VAL_ 1148 TBOX_BkChrgCycleSun 0 "Not active" 1 "Active" ;
VAL_ 1148 TBOX_BkChrgCycleSat 0 "Not active" 1 "Active" ;
VAL_ 1148 TBOX_BkChrgCycleFri 0 "Not active" 1 "Active" ;
VAL_ 1148 TimeToStartSentinelDayFed_47Ch 0 "No_active" 1 "Toady" 2 "Tomorrow" ;
VAL_ 1148 TimeToStartSentinelHourFed_47Ch 0 "Hour_0" 1 "Hour_1" 2 "Hour_2" 3 "Hour_3" 4 "Hour_4" 5 "Hour_5" 6 "Hour_6" 7 "Hour_7" 8 "Hour_8" 9 "Hour_9" 10 "Hour_10" 11 "Hour_11" 12 "Hour_12" 13 "Hour_13" 14 "Hour_14" 15 "Hour_15" 16 "Hour_16" 17 "Hour_17" 18 "Hour_18" 19 "Hour_19" 20 "Hour_20" 21 "Hour_21" 22 "Hour_22" 23 "Hour_23" 24 "Reserved" 25 "Reserved" 26 "Reserved" 27 "Reserved" 28 "Reserved" 29 "Reserved" 30 "Inactive" 31 "Invalid" ;
VAL_ 1148 TimeToStartSentinelMinutFed_47Ch 0 "Minute_0" 1 "Minute_1" 2 "Minute_2" 3 "Minute_3" 4 "Minute_4" 5 "Minute_5" 6 "Minute_6" 7 "Minute_7" 8 "Minute_8" 9 "Minute_9" 10 "Minute_10" 11 "Minute_11" 12 "Minute_12" 13 "Minute_13" 14 "Minute_14" 15 "Minute_15" 16 "Minute_16" 17 "Minute_17" 18 "Minute_18" 19 "Minute_19" 20 "Minute_20" 21 "Minute_21" 22 "Minute_22" 23 "Minute_23" 24 "Minute_24" 25 "Minute_25" 26 "Minute_26" 27 "Minute_27" 28 "Minute_28" 29 "Minute_29" 30 "Minute_30" 31 "Minute_31" 32 "Minute_32" 33 "Minute_33" 34 "Minute_34" 35 "Minute_35" 36 "Minute_36" 37 "Minute_37" 38 "Minute_38" 39 "Minute_39" 40 "Minute_40" 41 "Minute_41" 42 "Minute_42" 43 "Minute_43" 44 "Minute_44" 45 "Minute_45" 46 "Minute_46" 47 "Minute_47" 48 "Minute_48" 49 "Minute_49" 50 "Minute_50" 51 "Minute_51" 52 "Minute_52" 53 "Minute_53" 54 "Minute_54" 55 "Minute_55" 56 "Minute_56" 57 "Minute_57" 58 "Minute_58" 59 "Minute_59" 60 "Reserved" 61 "Reserved" 62 "Inactive" 63 "Invalid" ;
VAL_ 1148 TimeToStopSentinelHourFed_47Ch 0 "Hour_0" 1 "Hour_1" 2 "Hour_2" 3 "Hour_3" 4 "Hour_4" 5 "Hour_5" 6 "Hour_6" 7 "Hour_7" 8 "Hour_8" 9 "Hour_9" 10 "Hour_10" 11 "Hour_11" 12 "Hour_12" 13 "Hour_13" 14 "Hour_14" 15 "Hour_15" 16 "Hour_16" 17 "Hour_17" 18 "Hour_18" 19 "Hour_19" 20 "Hour_20" 21 "Hour_21" 22 "Hour_22" 23 "Hour_23" 24 "Reserved" 25 "Reserved" 26 "Reserved" 27 "Reserved" 28 "Reserved" 29 "Reserved" 30 "Inactive" 31 "Invalid" ;
VAL_ 1148 TimeToStopSentinelMinutFed_47Ch 0 "Minute_0" 1 "Minute_1" 2 "Minute_2" 3 "Minute_3" 4 "Minute_4" 5 "Minute_5" 6 "Minute_6" 7 "Minute_7" 8 "Minute_8" 9 "Minute_9" 10 "Minute_10" 11 "Minute_11" 12 "Minute_12" 13 "Minute_13" 14 "Minute_14" 15 "Minute_15" 16 "Minute_16" 17 "Minute_17" 18 "Minute_18" 19 "Minute_19" 20 "Minute_20" 21 "Minute_21" 22 "Minute_22" 23 "Minute_23" 24 "Minute_24" 25 "Minute_25" 26 "Minute_26" 27 "Minute_27" 28 "Minute_28" 29 "Minute_29" 30 "Minute_30" 31 "Minute_31" 32 "Minute_32" 33 "Minute_33" 34 "Minute_34" 35 "Minute_35" 36 "Minute_36" 37 "Minute_37" 38 "Minute_38" 39 "Minute_39" 40 "Minute_40" 41 "Minute_41" 42 "Minute_42" 43 "Minute_43" 44 "Minute_44" 45 "Minute_45" 46 "Minute_46" 47 "Minute_47" 48 "Minute_48" 49 "Minute_49" 50 "Minute_50" 51 "Minute_51" 52 "Minute_52" 53 "Minute_53" 54 "Minute_54" 55 "Minute_55" 56 "Minute_56" 57 "Minute_57" 58 "Minute_58" 59 "Minute_59" 60 "Reserved" 61 "Reserved" 62 "Inactive" 63 "Invalid" ;
VAL_ 1148 ReservationSentinelSts_Fed_47Ch 0 "No_active" 1 "ON" 2 "OFF" ;
VAL_ 1150 ICC_CPDDelaySwitchSet 0 "Not Active" 1 "ON" 2 "OFF" 3 "Not Used" ;
VAL_ 1150 ICC_PPMIDBSRBPASet 0 "Not Active" 1 "ON" 2 "OFF" 3 "Not Used" ;
VAL_ 1150 ICC_PPMIDHwSet 0 "Not Active" 1 "ON" 2 "OFF" 3 "Not Used" ;
VAL_ 1150 ICC_FLDoorButton 0 "Init" 1 "Inactive" 2 "Active" ;
VAL_ 1150 ICC_FRDoorButton 0 "Init" 1 "Inactive" 2 "Active" ;
VAL_ 1150 ICC_DriveDrosinessLevel 0 "not available" 1 "unknown" 2 "not fatigue" 3 "low fatigue" 4 "mid-fatigue" 5 "highly fatigue" 6 "Reserved" 7 "Reserved" ;
VAL_ 1150 ICC_RRDoorButton 0 "Init" 1 "Inactive" 2 "Active" ;
VAL_ 1150 ICC_RLDoorButton 0 "Init" 1 "Inactive" 2 "Active" ;
VAL_ 1150 ICC_CloseAllDoors 0 "Init" 1 "Inactive" 2 "Active" ;
VAL_ 1150 ICC_DoorRemoteKeyControlEnable 0 "No Request" 1 "Enable" 2 "Disable" ;
VAL_ 1150 ICC_SetOpenAngle 0 "No Request" 1 "50%" 2 "75%" 3 "100%" ;
VAL_ 1150 ICC_CPDSwitchSet 0 "Not Active" 1 "ON" 2 "OFF" 3 "Not Used" ;
VAL_ 1150 ICC_FrontDoorPowerMode 0 "No Request" 1 "PowerMode" 2 "ManualMode" 3 "SemiAutoMode" ;
VAL_ 1150 ICC_RearDoorPowerMode 0 "No Request" 1 "PowerMode" 2 "ManualMode" 3 "SemiAutoMode" ;
VAL_ 1150 ICC_PedalCloseDriverDoorEnable 0 "No Request" 1 "Enable" 2 "Disable" ;
VAL_ 1150 RR_Door_RearScreen_Control 0 "No Request" 1 "Inactive" 2 "active" ;
VAL_ 1150 ICC_RearDoorVoiceControlEnable 0 "No Request" 1 "Enable" 2 "Disable" ;
VAL_ 1150 ICC_FLVoiceControl 0 "No Action" 1 "Door Close" 2 "Door Open" ;
VAL_ 1150 ICC_FRVoiceControl 0 "No Action" 1 "Door Close" 2 "Door Open" ;
VAL_ 1150 ICC_RRVoiceControl 0 "No Action" 1 "Door Close" 2 "Door Open" ;
VAL_ 1150 ICC_RLVoiceControl 0 "No Action" 1 "Door Close" 2 "Door Open" ;
VAL_ 1150 RL_Door_RearScreen_Control 0 "No Request" 1 "Inactive" 2 "active" ;
VAL_ 1155 ASU_3_horizontalSts 0 "Not Active" 1 "ON" 2 "OFF" 3 "Not use" ;
VAL_ 1155 ASU_3_horizontalmodeFb 0 "Not Active" 1 "Working" 2 "Complete" 3 "Abort" 4 "Failure" 5 "Reserved" 6 "Reserved" 7 "Reserved" ;
VAL_ 1157 ICC_DA_15_BSDLCWSettingSt 0 "None" 1 "ON" 2 "OFF" 3 "Reserved" ;
VAL_ 1157 ICC_DA_15_DOWSettingSt 0 "None" 1 "ON" 2 "OFF" 3 "Reserved" ;
VAL_ 1157 ICC_DA_15_RCWSettingSt 0 "None" 1 "ON" 2 "OFF" 3 "Reserved" ;
VAL_ 1157 ICC_DA_15_RCTARCTBWarnType 0 "OFF" 1 "Warning" 2 "Warning and braking" 3 "None" ;
VAL_ 1157 ICC_DA_15_FCTAFCTBWarnType 0 "OFF" 1 "Warning" 2 "Warning and braking" 3 "None" ;
VAL_ 1157 ICC_DA_15_FrontPDCMuteSet 0 "OFF" 1 "ON" ;
VAL_ 1157 ICC_DA_15_FKPMuteSet 0 "OFF" 1 "ON" ;
VAL_ 1157 ICC_DA_15_ExtremeEnergySaveMode 0 "OFF" 1 "ON" ;
VAL_ 1157 Driver_AbnormalBehavior 0 "unknown" 1 "no abnormal behavior detected" 2 "abnormal behavior detected" 3 "Reserved" ;
VAL_ 1157 Dms_Status 0 "Init" 1 "off/standby" 2 "active" 3 "fault" 4 "camera blocked" ;
VAL_ 1157 Driver_EyeOnRoad 0 "Unavailable" 1 "Eyes on road" 2 "Eyes off road -- driving task related region" 3 "Eyes off road -- non-driving task related region" ;
VAL_ 1157 ICC_IHCfunctionSw 0 "Not Active" 1 "ON" 2 "OFF" 3 "Reserved" ;
VAL_ 1157 Dms_DriverPresence 0 "unknown" 1 "Not present" 2 "present" 3 "Reserved" ;
VAL_ 1157 Driver_GazeRegion 0 "Unknown" 1 "Driver Side of Windscreen" 2 "Passenger Side of Windscreen" 3 "Left Rear View Mirror" 4 "Right Rear View Mirror" 5 "Left Side Window" 6 "Right Side Window" 7 "Central Rear View Mirror" 8 "Central driver's Instrument Cluster(speed gauge,etc.)" 9 "other" ;
